VERSION ""

NS_ :

BS_:

BU_: FC

BO_ 999 GW_3E7: 8 Vector__XXX
 SG_ BCM_Status_Temp : 51|2@0+ (1,0) [0|3] ""  FC
 SG_ BCM_T_BATT : 39|8@0+ (1,-40) [-40|105] "°C"  FC

BO_ 1021 GW_3FD: 8 Vector__XXX
 SG_ BCM_DriveMode : 7|4@0+ (1,0) [0|15] ""  FC
 SG_ BCM_PowerManageLevel : 8|3@0+ (1,0) [0|7] ""  FC

BO_ 1310 GW_51E: 8 Vector__XXX
 SG_ TPMS_TireTemperature : 15|8@0+ (1,-40) [-40|214] "°C"  FC
 SG_ TPMS_TirePosition : 2|3@0+ (1,0) [0|3] ""  FC

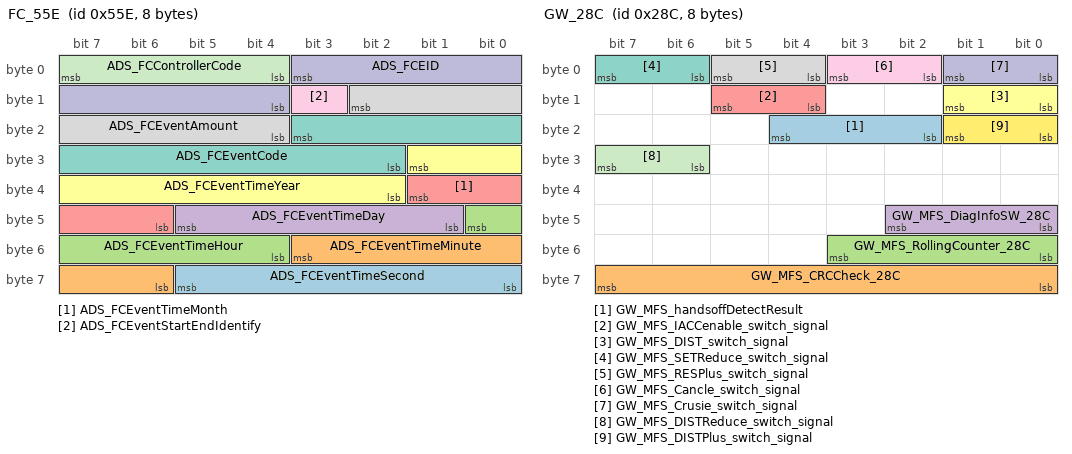
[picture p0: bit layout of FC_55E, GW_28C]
BO_ 1374 FC_55E: 8 FC
 SG_ ADS_FCEventTimeSecond : 61|6@0+ (1,0) [0|59] "秒" Vector__XXX
 SG_ ADS_FCEventTimeMinute : 51|6@0+ (1,0) [0|59] "分" Vector__XXX
 SG_ ADS_FCEventTimeHour : 40|5@0+ (1,0) [0|23] "时" Vector__XXX
 SG_ ADS_FCEventTimeDay : 45|5@0+ (1,0) [0|31] "日" Vector__XXX
 SG_ ADS_FCEventTimeMonth : 33|4@0+ (1,0) [0|15] "月" Vector__XXX
 SG_ ADS_FCEventTimeYear : 25|8@0+ (1,2013) [2013|2268] "年" Vector__XXX
 SG_ ADS_FCEventCode : 19|10@0+ (1,0) [0|1023] "" Vector__XXX
 SG_ ADS_FCEventAmount : 10|7@0+ (1,0) [0|127] "" Vector__XXX
 SG_ ADS_FCEventStartEndIdentify : 11|1@0+ (1,0) [0|1] "" Vector__XXX
 SG_ ADS_FCEID : 3|8@0+ (1,0) [0|255] "" Vector__XXX
 SG_ ADS_FCControllerCode : 7|4@0+ (1,0) [0|15] "" Vector__XXX

BO_ 652 GW_28C: 8 Vector__XXX
 SG_ GW_MFS_handsoffDetectResult : 20|3@0+ (1,0) [0|7] ""  FC
 SG_ GW_MFS_CRCCheck_28C : 63|8@0+ (1,0) [0|255] ""  FC
 SG_ GW_MFS_RollingCounter_28C : 51|4@0+ (1,0) [0|15] ""  FC
 SG_ GW_MFS_DiagInfoSW_28C : 42|3@0+ (1,0) [0|7] ""  FC
 SG_ GW_MFS_IACCenable_switch_signal : 13|2@0+ (1,0) [0|3] ""  FC
 SG_ GW_MFS_DIST_switch_signal : 9|2@0+ (1,0) [0|3] ""  FC
 SG_ GW_MFS_SETReduce_switch_signal : 7|2@0+ (1,0) [0|3] ""  FC
 SG_ GW_MFS_RESPlus_switch_signal : 5|2@0+ (1,0) [0|3] ""  FC
 SG_ GW_MFS_Cancle_switch_signal : 3|2@0+ (1,0) [0|3] ""  FC
 SG_ GW_MFS_Crusie_switch_signal : 1|2@0+ (1,0) [0|3] ""  FC
 SG_ GW_MFS_DISTReduce_switch_signal : 31|2@0+ (1,0) [0|3] ""  FC
 SG_ GW_MFS_DISTPlus_switch_signal : 17|2@0+ (1,0) [0|3] ""  FC

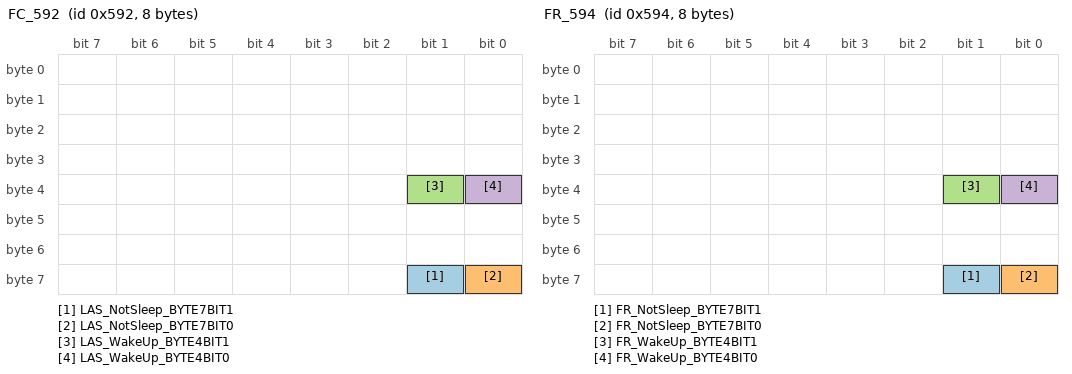
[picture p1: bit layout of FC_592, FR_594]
BO_ 1426 FC_592: 8 FC
 SG_ LAS_NotSleep_BYTE7BIT1 : 57|1@0+ (1,0) [0|1] "" Vector__XXX
 SG_ LAS_NotSleep_BYTE7BIT0 : 56|1@0+ (1,0) [0|1] "" Vector__XXX
 SG_ LAS_WakeUp_BYTE4BIT1 : 33|1@0+ (1,0) [0|1] "" Vector__XXX
 SG_ LAS_WakeUp_BYTE4BIT0 : 32|1@0+ (1,0) [0|1] "" Vector__XXX

BO_ 1428 FR_594: 8 Vector__XXX
 SG_ FR_NotSleep_BYTE7BIT1 : 57|1@0+ (1,0) [0|1] ""  FC
 SG_ FR_NotSleep_BYTE7BIT0 : 56|1@0+ (1,0) [0|1] ""  FC
 SG_ FR_WakeUp_BYTE4BIT1 : 33|1@0+ (1,0) [0|1] ""  FC
 SG_ FR_WakeUp_BYTE4BIT0 : 32|1@0+ (1,0) [0|1] ""  FC

BO_ 1106 FC_452: 8 FC

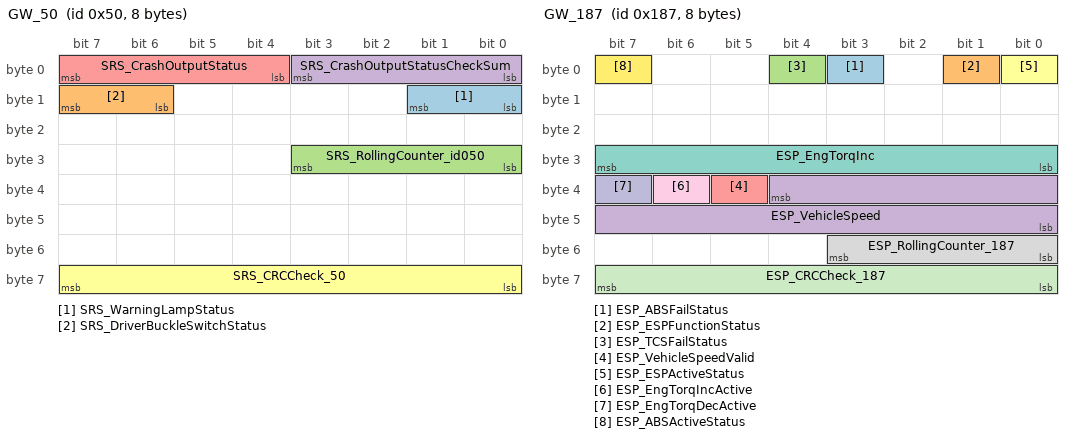
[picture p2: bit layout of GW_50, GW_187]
BO_ 80 GW_50: 8 Vector__XXX
 SG_ SRS_WarningLampStatus : 9|2@0+ (1,0) [0|3] ""  FC
 SG_ SRS_DriverBuckleSwitchStatus : 15|2@0+ (1,0) [0|3] ""  FC
 SG_ SRS_RollingCounter_id050 : 27|4@0+ (1,0) [0|15] ""  FC
 SG_ SRS_CrashOutputStatusCheckSum : 3|4@0+ (1,0) [0|15] ""  FC
 SG_ SRS_CrashOutputStatus : 7|4@0+ (1,0) [0|15] ""  FC
 SG_ SRS_CRCCheck_50 : 63|8@0+ (1,0) [0|255] ""  FC

BO_ 898 FC_382: 64 FC
 SG_ ACC_RollingCounter_382 : 491|4@0+ (1,0) [0|15] "" Vector__XXX
 SG_ ACC_CRCCheck_382 : 503|16@0+ (1,0) [0|65535] "" Vector__XXX
 SG_ ACC_CRCCheck_3E6 : 191|8@0+ (1,0) [0|255] "" Vector__XXX
 SG_ ACC_RollingCounter_3E6 : 179|4@0+ (1,0) [0|15] "" Vector__XXX
 SG_ ACC_LaneEquationStatus : 181|2@0+ (1,0) [0|3] "" Vector__XXX
 SG_ ACC_LaneEquationC3 : 161|12@0+ (4.768E-007,-0.0009760857) [-0.0009760857|0.0009760857] "" Vector__XXX
 SG_ ACC_LaneEquationC2 : 157|12@0+ (1.52588E-005,-0.0312347412) [-0.0312347412|0.0312347412] "" Vector__XXX
 SG_ ACC_LaneEquationC1 : 137|12@0+ (0.0004882813,-1) [-1|0.9990234375] "rad" Vector__XXX
 SG_ ACC_LaneQuality : 134|6@0+ (0.015625,0) [0|0.984375] "" Vector__XXX
 SG_ ACC_CRCCheck_35C : 127|8@0+ (1,0) [0|255] "" Vector__XXX
 SG_ ACC_RollingCounter_35C : 115|4@0+ (1,0) [0|15] "" Vector__XXX
 SG_ ACC_FRTarget2Type : 99|4@0+ (1,0) [0|15] "" Vector__XXX
 SG_ ACC_FRTarget2LatRange : 94|10@0+ (0.1,-50) [-50|50] "m" Vector__XXX
 SG_ ACC_FRTarget2LngRange : 72|9@0+ (0.5,-70) [-70|180] "m" Vector__XXX
 SG_ ACC_FRTarget2Detection : 76|3@0+ (1,0) [0|7] "" Vector__XXX
 SG_ ACC_FRTarget2Direction : 111|3@0+ (1,0) [0|7] "" Vector__XXX
 SG_ ACC_CRCCheck_35D : 63|8@0+ (1,0) [0|255] "" Vector__XXX
 SG_ ACC_RollingCounter_35D : 51|4@0+ (1,0) [0|15] "" Vector__XXX
 SG_ ACC_FRTarget1Direction : 47|3@0+ (1,0) [0|7] "" Vector__XXX
 SG_ ACC_FRTarget1Type : 35|4@0+ (1,0) [0|15] "" Vector__XXX
 SG_ ACC_FRTarget1LatRange : 30|10@0+ (0.1,-50) [-50|50] "m" Vector__XXX
 SG_ ACC_FRTarget1LngRange : 8|9@0+ (0.5,-70) [-70|180] "m" Vector__XXX
 SG_ ACC_FRTarget1Detection : 12|3@0+ (1,0) [0|7] "" Vector__XXX
 SG_ ACC_FLTarget2LatRange : 7|10@0+ (0.1,-50) [-50|50] "m" Vector__XXX

BO_ 1328 GW_530: 8 Vector__XXX
 SG_ IP_TotalOdometer : 23|24@0+ (0.1,0) [0|999999] "Km"  FC

BO_ 391 GW_187: 8 Vector__XXX
 SG_ ESP_ABSFailStatus : 3|1@0+ (1,0) [0|1] ""  FC
 SG_ ESP_ESPFunctionStatus : 1|1@0+ (1,0) [0|1] ""  FC
 SG_ ESP_TCSFailStatus : 4|1@0+ (1,0) [0|1] ""  FC
 SG_ ESP_VehicleSpeed : 36|13@0+ (0.05625,0) [0|360] "km/h"  FC
 SG_ ESP_VehicleSpeedValid : 37|1@0+ (1,0) [0|1] ""  FC
 SG_ ESP_ESPActiveStatus : 0|1@0+ (1,0) [0|1] ""  FC
 SG_ ESP_EngTorqInc : 31|8@0+ (0.392,0) [0|99.568] "%"  FC
 SG_ ESP_RollingCounter_187 : 51|4@0+ (1,0) [0|15] ""  FC
 SG_ ESP_EngTorqIncActive : 38|1@0+ (1,0) [0|1] ""  FC
 SG_ ESP_EngTorqDecActive : 39|1@0+ (1,0) [0|1] ""  FC
 SG_ ESP_CRCCheck_187 : 63|8@0+ (1,0) [0|255] ""  FC
 SG_ ESP_ABSActiveStatus : 7|1@0+ (1,0) [0|1] ""  FC

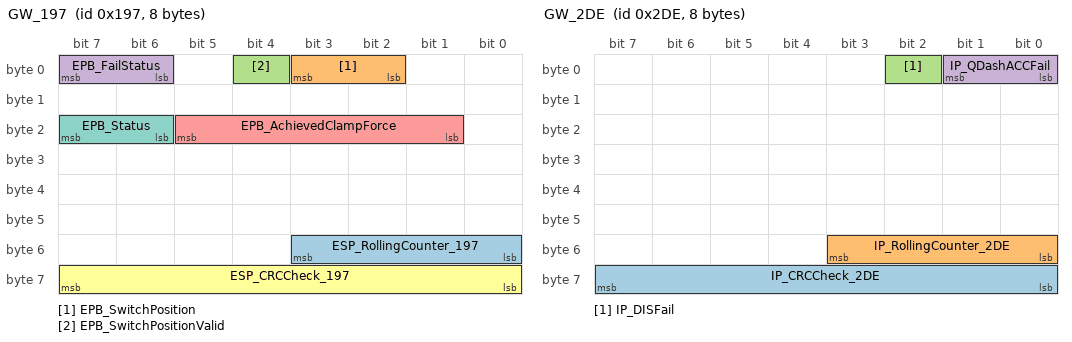
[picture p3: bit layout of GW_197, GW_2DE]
BO_ 407 GW_197: 8 Vector__XXX
 SG_ ESP_RollingCounter_197 : 51|4@0+ (1,0) [0|15] ""  FC
 SG_ EPB_SwitchPosition : 3|2@0+ (1,0) [0|3] ""  FC
 SG_ EPB_SwitchPositionValid : 4|1@0+ (1,0) [0|1] ""  FC
 SG_ EPB_FailStatus : 7|2@0+ (1,0) [0|3] ""  FC
 SG_ EPB_AchievedClampForce : 21|5@0+ (1,0) [0|31] "KN"  FC
 SG_ ESP_CRCCheck_197 : 63|8@0+ (1,0) [0|255] ""  FC
 SG_ EPB_Status : 23|2@0+ (1,0) [0|3] ""  FC

BO_ 523 GW_20B: 64 Vector__XXX
 SG_ ESP_RollingCounter_20B : 491|4@0+ (1,0) [0|15] ""  FC
 SG_ ESP_CRCCheck_20B : 503|16@0+ (1,0) [0|65535] ""  FC
 SG_ ESP_Vehicle_Speed_Reference : 103|13@0+ (0.05625,0) [0|360] "km/h"  FC
 SG_ Wheel_Speed_RR_Valid_Data : 71|1@0+ (1,0) [0|1] ""  FC
 SG_ Wheel_Speed_RR_Pulse : 231|8@0+ (1,0) [0|254] ""  FC
 SG_ Wheel_Speed_RR_Direction : 70|2@0+ (1,0) [0|3] ""  FC
 SG_ Wheel_Speed_RR_Data : 68|13@0+ (0.05625,0) [0|360] "km/h"  FC
 SG_ Wheel_Speed_RL_Valid_Data : 87|1@0+ (1,0) [0|1] ""  FC
 SG_ Wheel_Speed_RL_Pulse : 239|8@0+ (1,0) [0|254] ""  FC
 SG_ Wheel_Speed_RL_Direction : 86|2@0+ (1,0) [0|3] ""  FC
 SG_ Wheel_Speed_RL_Data : 84|13@0+ (0.05625,0) [0|360] "km/h"  FC
 SG_ Wheel_Speed_FR_Valid_Data : 7|1@0+ (1,0) [0|1] ""  FC
 SG_ Wheel_Speed_FR_Pulse : 223|8@0+ (1,0) [0|254] ""  FC
 SG_ Wheel_Speed_FR_Direction : 6|2@0+ (1,0) [0|3] ""  FC
 SG_ Wheel_Speed_FR_Data : 4|13@0+ (0.05625,0) [0|360] "km/h"  FC
 SG_ Wheel_Speed_FL_Valid_Data : 23|1@0+ (1,0) [0|1] ""  FC
 SG_ Wheel_Speed_FL_Pulse : 215|8@0+ (1,0) [0|254] ""  FC
 SG_ Wheel_Speed_FL_Direction : 22|2@0+ (1,0) [0|3] ""  FC
 SG_ Wheel_Speed_FL_Data : 20|13@0+ (0.05625,0) [0|360] "km/h"  FC
 SG_ ESP_VehicleStandstill : 267|1@0+ (1,0) [0|1] ""  FC
 SG_ ESP_VDCActive : 266|1@0+ (1,0) [0|1] ""  FC
 SG_ ESP_TCSActive : 265|1@0+ (1,0) [0|1] ""  FC
 SG_ ESP_RollingCounter_277 : 307|4@0+ (1,0) [0|15] ""  FC
 SG_ ESP_RollingCounter_258 : 243|4@0+ (1,0) [0|15] ""  FC
 SG_ ESP_RollingCounter_208 : 115|4@0+ (1,0) [0|15] ""  FC
 SG_ ESP_RollingCounter_206 : 51|4@0+ (1,0) [0|15] ""  FC
 SG_ ESP_QDCACC : 279|2@0+ (1,0) [0|3] ""  FC
 SG_ ESP_PrefillAvailable : 259|1@0+ (1,0) [0|1] ""  FC
 SG_ ESP_PrefillActive : 260|1@0+ (1,0) [0|1] ""  FC
 SG_ ESP_OnlyABSActive : 264|1@0+ (1,0) [0|1] ""  FC
 SG_ ESP_MasCylBrakePressureValid : 199|1@0+ (1,0) [0|1] ""  FC
 SG_ ESP_MasCylBrakePressure : 195|12@0+ (0.1,0) [0|250] "Bar"  FC
 SG_ ESP_HDC_STATUS : 274|2@0+ (1,0) [0|3] ""  FC
 SG_ ESP_CRCCheck_277 : 319|8@0+ (1,0) [0|255] ""  FC
 SG_ ESP_CRCCheck_258 : 255|8@0+ (1,0) [0|255] ""  FC
 SG_ ESP_CRCCheck_208 : 127|8@0+ (1,0) [0|255] ""  FC
 SG_ ESP_CRCCheck_206 : 63|8@0+ (1,0) [0|255] ""  FC
 SG_ ESP_CDD_Available : 268|1@0+ (1,0) [0|1] ""  FC
 SG_ ESP_CDD_Active : 269|1@0+ (1,0) [0|1] ""  FC
 SG_ ESP_BrakeOverHeatBrakeDiscTemp : 270|1@0+ (1,0) [0|1] ""  FC
 SG_ ESP_BrakeForce : 263|1@0+ (1,0) [0|1] ""  FC
 SG_ ESP_AWBavailable : 271|1@0+ (1,0) [0|1] ""  FC
 SG_ ESP_AWBactive : 256|1@0+ (1,0) [0|1] ""  FC
 SG_ ESP_AEBdecActive : 257|1@0+ (1,0) [0|1] ""  FC
 SG_ ESP_AEBAvailable : 258|1@0+ (1,0) [0|1] ""  FC
 SG_ ESP_ABAavailable : 261|1@0+ (1,0) [0|1] ""  FC
 SG_ ESP_ABAactive : 262|1@0+ (1,0) [0|1] ""  FC

BO_ 734 GW_2DE: 8 Vector__XXX
 SG_ IP_CRCCheck_2DE : 63|8@0+ (1,0) [0|255] ""  FC
 SG_ IP_RollingCounter_2DE : 51|4@0+ (1,0) [0|15] ""  FC
 SG_ IP_DISFail : 2|1@0+ (1,0) [0|1] ""  FC
 SG_ IP_QDashACCFail : 1|2@0+ (1,0) [0|3] ""  FC

BO_ 947 IBCMR_3B3: 8 Vector__XXX
 SG_ BCM_BrakeLampError : 31|1@0+ (1,0) [0|1] ""  FC
 SG_ BCM_RearFoglampStatus : 11|2@0+ (1,0) [0|3] ""  FC

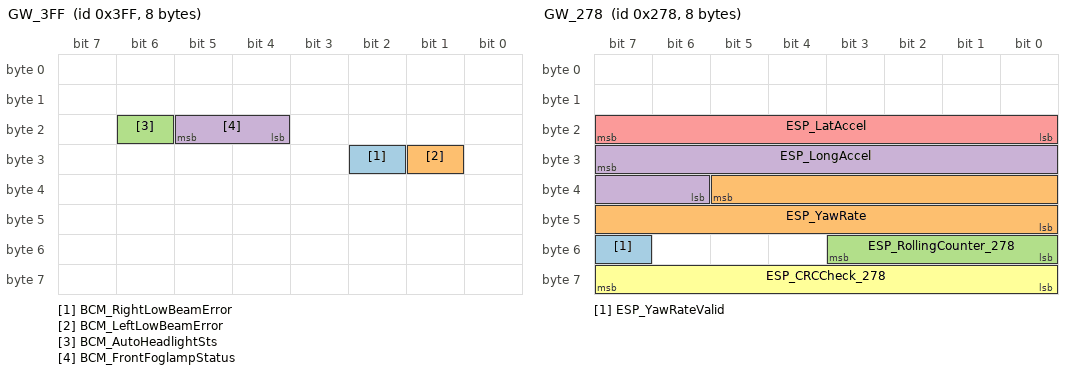
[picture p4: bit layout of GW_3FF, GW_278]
BO_ 1023 GW_3FF: 8 Vector__XXX
 SG_ BCM_RightLowBeamError : 26|1@0+ (1,0) [0|1] ""  FC
 SG_ BCM_LeftLowBeamError : 25|1@0+ (1,0) [0|1] ""  FC
 SG_ BCM_AutoHeadlightSts : 22|1@0+ (1,0) [0|1] ""  FC
 SG_ BCM_FrontFoglampStatus : 21|2@0+ (1,0) [0|3] ""  FC

BO_ 1882 FC_75A: 64 FC

BO_ 1899 FC_76B: 8 FC

BO_ 632 GW_278: 8 Vector__XXX
 SG_ ESP_YawRateValid : 55|1@0+ (1,0) [0|1] ""  FC
 SG_ ESP_YawRate : 37|14@0+ (0.01,-81.91) [-81.91|81.91] "degree/s"  FC
 SG_ ESP_RollingCounter_278 : 51|4@0+ (1,0) [0|15] ""  FC
 SG_ ESP_LongAccel : 31|10@0+ (0.03125,-16) [-16|15.90625] "m/s2"  FC
 SG_ ESP_LatAccel : 23|8@0+ (0.1,-12.7) [-12.7|12.7] "m/s2"  FC
 SG_ ESP_CRCCheck_278 : 63|8@0+ (1,0) [0|255] ""  FC

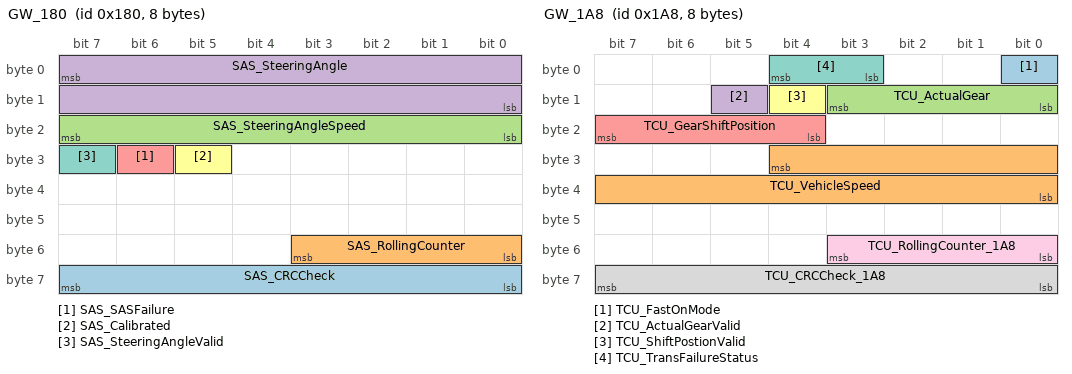
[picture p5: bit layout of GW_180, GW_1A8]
BO_ 384 GW_180: 8 Vector__XXX
 SG_ SAS_CRCCheck : 63|8@0+ (1,0) [0|255] ""  FC
 SG_ SAS_RollingCounter : 51|4@0+ (1,0) [0|15] ""  FC
 SG_ SAS_SteeringAngleSpeed : 23|8@0+ (4,0) [0|1016] "deg/s"  FC
 SG_ SAS_SteeringAngle : 7|16@0- (0.1,0) [-780|780] "degree"  FC
 SG_ SAS_SASFailure : 30|1@0+ (1,0) [0|1] ""  FC
 SG_ SAS_Calibrated : 29|1@0+ (1,0) [0|1] ""  FC
 SG_ SAS_SteeringAngleValid : 31|1@0+ (1,0) [0|1] ""  FC

BO_ 424 GW_1A8: 8 Vector__XXX
 SG_ TCU_FastOnMode : 0|1@0+ (1,0) [0|1] ""  FC
 SG_ TCU_VehicleSpeed : 28|13@0+ (0.05625,0) [0|360] "km/h"  FC
 SG_ TCU_ActualGear : 11|4@0+ (1,0) [0|15] ""  FC
 SG_ TCU_ActualGearValid : 13|1@0+ (1,0) [0|1] ""  FC
 SG_ TCU_GearShiftPosition : 23|4@0+ (1,0) [0|15] ""  FC
 SG_ TCU_ShiftPostionValid : 12|1@0+ (1,0) [0|1] ""  FC
 SG_ TCU_TransFailureStatus : 4|2@0+ (1,0) [0|3] ""  FC
 SG_ TCU_CRCCheck_1A8 : 63|8@0+ (1,0) [0|255] ""  FC
 SG_ TCU_RollingCounter_1A8 : 51|4@0+ (1,0) [0|15] ""  FC

BO_ 784 GW_310: 8 Vector__XXX
 SG_ AMP_AllAlarmFailureStatus : 38|1@0+ (1,0) [0|1] ""  FC
 SG_ AMP_IPEnableAlarmFailureStatus : 39|1@0+ (1,0) [0|1] ""  FC

BO_ 790 FC_316: 64 FC
 SG_ LAS_Line_04_MeasureType_FT : 495|3@0+ (1,0) [0|7] "" Vector__XXX
 SG_ LAS_Line_03_MeasureType_FT : 482|3@0+ (1,0) [0|7] "" Vector__XXX
 SG_ LAS_Line_02_MeasureType_FT : 354|3@0+ (1,0) [0|7] "" Vector__XXX
 SG_ LAS_Line_01_MeasureType_FT : 338|3@0+ (1,0) [0|7] "" Vector__XXX
 SG_ LAS_Line_03_curvature_alte_FT : 367|12@0+ (1.272E-007,-0.00026042) [-0.00026042|0.000260417] "1/m2" Vector__XXX
 SG_ LAS_Line_03_curve_FT : 274|14@0+ (1.9074E-006,-0.015625) [-0.015625|0.0156212077] "1/m" Vector__XXX
 SG_ LAS_Line_02_curvature_alte_FT : 179|12@0+ (1.272E-007,-0.00026042) [-0.00026042|0.000260417] "1/m2" Vector__XXX
 SG_ LAS_Line_02_curve_FT : 157|14@0+ (1.9074E-006,-0.015625) [-0.015625|0.0156212077] "1/m" Vector__XXX
 SG_ LAS_Line_01_curvature_alte_FT : 175|12@0+ (1.272E-007,-0.00026042) [-0.00026042|0.000260417] "1/m2" Vector__XXX
 SG_ LAS_Line_01_curve_FT : 82|14@0+ (1.9074E-006,-0.015625) [-0.015625|0.0156212077] "1/m" Vector__XXX
 SG_ LAS_RollingCounter_316 : 491|4@0+ (1,0) [0|15] "" Vector__XXX
 SG_ LAS_CRCCheck_316 : 503|16@0+ (1,0) [0|65535] "" Vector__XXX
 SG_ LAS_Line_03_MeasureType : 465|2@0+ (1,0) [0|2] "" Vector__XXX
 SG_ LAS_Line_03_curvature_alteration : 371|12@0+ (3.8147E-006,-0.0078125) [-0.0078125|0.0078086965] "1/m2" Vector__XXX
 SG_ LAS_Line_03__curve : 479|13@0+ (3.8147E-006,-0.015625) [-0.015625|0.0156212077] "1/m" Vector__XXX
 SG_ LAS_Line_03_HeadingAngle : 351|13@0+ (0.000488281,-1.6) [-1.6|1.6] "rad" Vector__XXX
 SG_ LAS_Line_03_dy : 462|12@0+ (0.015625,-32) [-32|31.984375] "m" Vector__XXX
 SG_ LAS_Line_03_dx_End_std : 455|9@0+ (0.0078125,0) [0|3.992187] "m" Vector__XXX
 SG_ LAS_Line_03__dx_End : 433|10@0+ (0.25,0) [0|255.75] "m" Vector__XXX
 SG_ LAS_Line_03_dx_Start_std : 426|9@0+ (0.0078125,0) [0|3.9921875] "m" Vector__XXX
 SG_ LAS_Line_03_dx_Start : 423|13@0+ (0.025,0) [0|204.775] "m" Vector__XXX
 SG_ LAS_Line_03_Width : 415|8@0+ (0.01,0) [0|2.55] "m" Vector__XXX
 SG_ LAS_Line_03_color : 402|3@0+ (1,0) [0|7] "" Vector__XXX
 SG_ LAS_Line_03_Id : 399|8@0+ (1,0) [1|255] "" Vector__XXX
 SG_ LAS_Line_03_TypeConfidence : 391|6@0+ (2,0) [0|100] "%" Vector__XXX
 SG_ LAS_Line_03_Type : 407|5@0+ (1,0) [0|31] "" Vector__XXX
 SG_ LAS_Line_02__exist_prob : 325|6@0+ (2,0) [0|100] "%" Vector__XXX
 SG_ LAS_Line_02_MeasureType : 310|2@0+ (1,0) [0|2] "" Vector__XXX
 SG_ LAS_Line_02_curvature_alteration : 307|12@0+ (3.8147E-006,-0.0078125) [-0.0078125|0.0078086965] "1/m2" Vector__XXX
 SG_ LAS_Line_02__curve : 292|13@0+ (3.8147E-006,-0.015625) [-0.015625|0.0156212077] "1/m" Vector__XXX
 SG_ LAS_Line_02_HeadingAngle : 335|13@0+ (0.000488281,-1.6) [-1.6|1.6] "rad" Vector__XXX
 SG_ LAS_Line_02_dy : 270|12@0+ (0.015625,-32) [-32|31.984375] "m" Vector__XXX
 SG_ LAS_Line_02_dx_End_std : 263|9@0+ (0.0078125,0) [0|3.992187] "m" Vector__XXX
 SG_ LAS_Line_02__dx_End : 241|10@0+ (0.25,0) [0|255.75] "m" Vector__XXX
 SG_ LAS_Line_02_dx_Start_std : 234|9@0+ (0.0078125,0) [0|3.9921875] "m" Vector__XXX
 SG_ LAS_Line_02_dx_Start : 231|13@0+ (0.025,0) [0|204.775] "m" Vector__XXX
 SG_ LAS_Line_02_Width : 223|8@0+ (0.01,0) [0|2.55] "m" Vector__XXX
 SG_ LAS_Line_02_color : 210|3@0+ (1,0) [0|7] "" Vector__XXX
 SG_ LAS_Line_02_Id : 207|8@0+ (1,0) [1|255] "" Vector__XXX
 SG_ LAS_Line_02_TypeConfidence : 199|6@0+ (2,0) [0|100] "%" Vector__XXX
 SG_ LAS_Line_02_Type : 215|5@0+ (1,0) [0|31] "" Vector__XXX
 SG_ LAS_Line_01__exist_prob : 133|6@0+ (2,0) [0|100] "%" Vector__XXX
 SG_ LAS_Line_01_MeasureType : 118|2@0+ (1,0) [0|2] "" Vector__XXX
 SG_ LAS_Line_01_curvature_alteration : 115|12@0+ (3.8147E-006,-0.0078125) [-0.0078125|0.0078086965] "1/m2" Vector__XXX
 SG_ LAS_Line_01__curve : 100|13@0+ (3.8147E-006,-0.015625) [-0.015625|0.0156212077] "1/m" Vector__XXX
 SG_ LAS_Line_01_HeadingAngle : 143|13@0+ (0.000488281,-1.6) [-1.6|1.6] "rad" Vector__XXX
 SG_ LAS_Line_01_dy : 78|12@0+ (0.015625,-32) [-32|31.984375] "m" Vector__XXX
 SG_ LAS_Line_01_dx_End_std : 71|9@0+ (0.0078125,0) [0|3.992187] "m" Vector__XXX
 SG_ LAS_Line_01__dx_End : 49|10@0+ (0.25,0) [0|255.75] "m" Vector__XXX
 SG_ LAS_Line_01_dx_Start_std : 42|9@0+ (0.0078125,0) [0|3.9921875] "m" Vector__XXX
 SG_ LAS_Line_01_dx_Start : 39|13@0+ (0.025,0) [0|204.775] "m" Vector__XXX
 SG_ LAS_Line_01_Width : 31|8@0+ (0.01,0) [0|2.55] "m" Vector__XXX
 SG_ LAS_Line_01_color : 18|3@0+ (1,0) [0|7] "" Vector__XXX
 SG_ LAS_Line_01_Id : 15|8@0+ (1,0) [1|255] "" Vector__XXX
 SG_ LAS_Line_01_TypeConfidence : 7|6@0+ (2,0) [0|100] "%" Vector__XXX
 SG_ LAS_Line_01_Type : 23|5@0+ (1,0) [0|31] "" Vector__XXX

BO_ 800 GW_320: 8 Vector__XXX
 SG_ GW_ResetReq : 31|7@0+ (1,0) [0|127] ""  FC

BO_ 822 FC_336: 64 FC
 SG_ LAS_Line_06_MeasureType_FT : 481|3@0+ (1,0) [0|7] "" Vector__XXX
 SG_ LAS_Line_06_curve_FT : 346|14@0+ (1.9074E-006,-0.015625) [-0.015625|0.0156212077] "1/m" Vector__XXX
 SG_ LAS_Line_05_MeasureType_FT : 154|3@0+ (1,0) [0|7] "" Vector__XXX
 SG_ LAS_Line_05_curve_FT : 170|14@0+ (1.9074E-006,-0.015625) [-0.015625|0.0156212077] "1/m" Vector__XXX
 SG_ LAS_Line_04_curvature_alte_FT : 272|12@0+ (1.272E-007,-0.00026042) [-0.00026042|0.000260417] "1/m2" Vector__XXX
 SG_ LAS_Line_04_curve_FT : 82|14@0+ (1.9074E-006,-0.015625) [-0.015625|0.0156212077] "1/m" Vector__XXX
 SG_ LAS_RollingCounter_336 : 491|4@0+ (1,0) [0|15] "" Vector__XXX
 SG_ LAS_CRCCheck_336 : 503|16@0+ (1,0) [0|65535] "" Vector__XXX
 SG_ LAS_Line_06__exist_prob : 333|6@0+ (2,0) [0|100] "%" Vector__XXX
 SG_ LAS_Line_06_MeasureType : 465|2@0+ (1,0) [0|2] "" Vector__XXX
 SG_ LAS_Line_06_curvature_alteration : 371|12@0+ (3.8147E-006,-0.0078125) [-0.0078125|0.0078086965] "1/m2" Vector__XXX
 SG_ LAS_Line_06__curve : 479|13@0+ (3.8147E-006,-0.015625) [-0.015625|0.0156212077] "1/m" Vector__XXX
 SG_ LAS_Line_06_HeadingAngle : 343|13@0+ (0.000488281,-1.6) [-1.6|1.6] "rad" Vector__XXX
 SG_ LAS_Line_06_dy : 462|12@0+ (0.015625,-32) [-32|31.984375] "m" Vector__XXX
 SG_ LAS_Line_06_dx_End_std : 455|9@0+ (0.0078125,0) [0|3.992187] "m" Vector__XXX
 SG_ LAS_Line_06__dx_End : 433|10@0+ (0.25,0) [0|255.75] "m" Vector__XXX
 SG_ LAS_Line_06_dx_Start_std : 426|9@0+ (0.0078125,0) [0|3.9921875] "m" Vector__XXX
 SG_ LAS_Line_06_dx_Start : 423|13@0+ (0.025,0) [0|204.775] "m" Vector__XXX
 SG_ LAS_Line_06_Width : 415|8@0+ (0.01,0) [0|2.55] "m" Vector__XXX
 SG_ LAS_Line_06_color : 402|3@0+ (1,0) [0|7] "" Vector__XXX
 SG_ LAS_Line_06_Id : 399|8@0+ (1,0) [1|255] "" Vector__XXX
 SG_ LAS_Line_06_TypeConfidence : 391|6@0+ (2,0) [0|100] "%" Vector__XXX
 SG_ LAS_Line_06_Type : 407|5@0+ (1,0) [0|31] "" Vector__XXX
 SG_ LAS_Line_05__exist_prob : 325|6@0+ (2,0) [0|100] "%" Vector__XXX
 SG_ LAS_Line_05_MeasureType : 310|2@0+ (1,0) [0|2] "" Vector__XXX
 SG_ LAS_Line_05_curvature_alteration : 307|12@0+ (3.8147E-006,-0.0078125) [-0.0078125|0.0078086965] "1/m2" Vector__XXX
 SG_ LAS_Line_05__curve : 292|13@0+ (3.8147E-006,-0.015625) [-0.015625|0.0156212077] "1/m" Vector__XXX
 SG_ LAS_Line_05_HeadingAngle : 167|13@0+ (0.000488281,-1.6) [-1.6|1.6] "rad" Vector__XXX
 SG_ LAS_Line_05_dy : 270|12@0+ (0.015625,-32) [-32|31.984375] "m" Vector__XXX
 SG_ LAS_Line_05_dx_End_std : 263|9@0+ (0.0078125,0) [0|3.992187] "m" Vector__XXX
 SG_ LAS_Line_05__dx_End : 241|10@0+ (0.25,0) [0|255.75] "m" Vector__XXX
 SG_ LAS_Line_05_dx_Start_std : 234|9@0+ (0.0078125,0) [0|3.9921875] "m" Vector__XXX
 SG_ LAS_Line_05_dx_Start : 231|13@0+ (0.025,0) [0|204.775] "m" Vector__XXX
 SG_ LAS_Line_05_Width : 223|8@0+ (0.01,0) [0|2.55] "m" Vector__XXX
 SG_ LAS_Line_05_color : 210|3@0+ (1,0) [0|7] "" Vector__XXX
 SG_ LAS_Line_05_Id : 207|8@0+ (1,0) [1|255] "" Vector__XXX
 SG_ LAS_Line_05_TypeConfidence : 199|6@0+ (2,0) [0|100] "%" Vector__XXX
 SG_ LAS_Line_05_Type : 215|5@0+ (1,0) [0|31] "" Vector__XXX
 SG_ LAS_Line_04__exist_prob : 133|6@0+ (2,0) [0|100] "%" Vector__XXX
 SG_ LAS_Line_04_MeasureType : 118|2@0+ (1,0) [0|2] "" Vector__XXX
 SG_ LAS_Line_04_curvature_alteration : 115|12@0+ (3.8147E-006,-0.0078125) [-0.0078125|0.0078086965] "1/m2" Vector__XXX
 SG_ LAS_Line_04__curve : 100|13@0+ (3.8147E-006,-0.015625) [-0.015625|0.0156212077] "1/m" Vector__XXX
 SG_ LAS_Line_04_HeadingAngle : 151|13@0+ (0.000488281,-1.6) [-1.6|1.6] "rad" Vector__XXX
 SG_ LAS_Line_04_dy : 78|12@0+ (0.015625,-32) [-32|31.984375] "m" Vector__XXX
 SG_ LAS_Line_04_dx_End_std : 71|9@0+ (0.0078125,0) [0|3.992187] "m" Vector__XXX
 SG_ LAS_Line_04__dx_End : 49|10@0+ (0.25,0) [0|255.75] "m" Vector__XXX
 SG_ LAS_Line_04_dx_Start_std : 42|9@0+ (0.0078125,0) [0|3.9921875] "m" Vector__XXX
 SG_ LAS_Line_04_dx_Start : 39|13@0+ (0.025,0) [0|204.775] "m" Vector__XXX
 SG_ LAS_Line_04_Width : 31|8@0+ (0.01,0) [0|2.55] "m" Vector__XXX
 SG_ LAS_Line_04_color : 18|3@0+ (1,0) [0|7] "" Vector__XXX
 SG_ LAS_Line_04_Id : 15|8@0+ (1,0) [1|255] "" Vector__XXX
 SG_ LAS_Line_04_TypeConfidence : 7|6@0+ (2,0) [0|100] "%" Vector__XXX
 SG_ LAS_Line_04_Type : 23|5@0+ (1,0) [0|31] "" Vector__XXX
 SG_ LAS_Line_03__exist_prob : 141|6@0+ (2,0) [0|100] "%" Vector__XXX

BO_ 683 FC_2AB: 64 FC
 SG_ FC_RollingCounter_28D : 491|4@0+ (1,0) [0|15] "" Vector__XXX
 SG_ FC_CRCCheck_28D : 503|16@0+ (1,0) [0|65535] "" Vector__XXX
 SG_ FC_AEBOBJ_Track_Age : 479|8@0+ (1,0) [0|255] "" Vector__XXX
 SG_ FC_AEBOBJ_Track_ID : 460|8@0+ (1,0) [0|255] "" Vector__XXX
 SG_ FC_AEBOBJ_FusionedFC_Track_ID : 487|8@0+ (1,0) [0|255] "" Vector__XXX
 SG_ FC_AEBOBJ_fusion_Sts : 463|2@0+ (1,0) [0|3] "" Vector__XXX
 SG_ FC_AEBOBJ_ObstacleProb : 453|6@0+ (2,0) [0|100] "%" Vector__XXX
 SG_ FC_AEBOBJ_ExistProb : 445|6@0+ (2,0) [0|100] "%" Vector__XXX
 SG_ FC_AEBOBJ_Brakelight_Info : 447|1@0+ (1,0) [0|1] "" Vector__XXX
 SG_ FC_AEBOBJ_Taillight_Info : 434|3@0+ (1,0) [0|7] "" Vector__XXX
 SG_ FC_AEBOBJ_Dis_to_R_LaneMark : 428|9@0+ (0.01,0) [0|5] "m" Vector__XXX
 SG_ FC_AEBOBJ_Dis_to_L_LaneMark : 422|9@0+ (0.01,0) [0|5] "m" Vector__XXX
 SG_ FC_AEBOBJ_Ax : 401|10@0+ (0.03125,-16) [-16|15.96875] "m/s2" Vector__XXX
 SG_ FC_AEBOBJ_Ay : 394|9@0+ (0.0625,-16) [-16|15.9375] "m/s2" Vector__XXX
 SG_ FC_AEBOBJ_Vx_std : 391|12@0+ (0.0625,-128) [-128|127.9375] "m/s" Vector__XXX
 SG_ FC_AEBOBJ_Vx : 372|12@0+ (0.0625,-128) [-128|127.9375] "m/s" Vector__XXX
 SG_ FC_AEBOBJ_Vy_std : 367|10@0+ (0.125,-64) [-64|63.875] "m/s" Vector__XXX
 SG_ FC_AEBOBJ_Vy : 345|10@0+ (0.125,-64) [-64|63.875] "m/s" Vector__XXX
 SG_ FC_AEBOBJ_Dx_Vnce : 329|14@0+ (0.05,0) [0|50] "" Vector__XXX
 SG_ FC_AEBOBJ_Dx : 327|13@0+ (0.0625,-256) [-256|255.9375] "m" Vector__XXX
 SG_ FC_AEBOBJ_Dy_Vnce : 305|10@0+ (0.02,0) [0|20] "m2" Vector__XXX
 SG_ FC_AEBOBJ_Dy : 301|11@0+ (0.125,-128) [-128|127.875] "m" Vector__XXX
 SG_ FC_AEBOBJ_HeadingAngle : 294|9@0+ (0.01,-1.57) [-1.57|1.57] "rad" Vector__XXX
 SG_ FC_AEBOBJ_Length : 287|9@0+ (0.05,0) [0|25.5] "m" Vector__XXX
 SG_ FC_AEBOBJ_Height : 264|9@0+ (0.01,0) [0|5.11] "m" Vector__XXX
 SG_ FC_AEBOBJ_Width : 259|11@0+ (0.01,0) [0|12] "m" Vector__XXX
 SG_ FC_AEBOBJ_Class : 263|3@0+ (1,0) [0|7] "" Vector__XXX

BO_ 711 GW_2C7: 64 Vector__XXX
 SG_ FRC_TiOut : 101|1@0+ (1,0) [0|1] "-"  FC
 SG_ FRC_TiLeap : 102|1@0+ (1,0) [0|1] "-"  FC
 SG_ FRC_TiBas : 103|1@0+ (1,0) [0|1] "-"  FC
 SG_ FRC_TiStamp : 71|32@0+ (0.0001,0) [0|429496.7295] "s"  FC
 SG_ FRC_FCTBStatus : 47|2@0+ (1,0) [0|3] ""  FC
 SG_ FRC_FCTAEnable : 52|1@0+ (1,0) [0|1] ""  FC
 SG_ FRC_PrefillActive : 26|1@0+ (1,0) [0|1] ""  FC
 SG_ FRC_RollingCounter_2C7 : 491|4@0+ (1,0) [0|15] ""  FC
 SG_ FRC_CRCCheck_2C7 : 503|16@0+ (1,0) [0|65535] ""  FC
 SG_ FRC_ObjDelay : 39|8@0+ (1,0) [0|255] "ms"  FC
 SG_ FRC_SystemStatus : 29|3@0+ (1,0) [0|7] ""  FC
 SG_ FRC_Right_FCTARStatus : 31|2@0+ (1,0) [0|3] ""  FC
 SG_ FRC_Right_FCTARAlert : 17|2@0+ (1,0) [0|3] ""  FC
 SG_ FRC_Left_FCTALAlert : 21|2@0+ (1,0) [0|3] ""  FC
 SG_ FRC_FCTBActive : 22|1@0+ (1,0) [0|1] ""  FC
 SG_ FRC_FCTBTargetDeceleration : 7|16@0+ (0.0005,-16) [-16|16] "m/s2"  FC
 SG_ FRC_FCTBEnable : 23|1@0+ (1,0) [0|1] ""  FC

BO_ 747 FC_2EB: 64 FC
 SG_ FC_RollingCounter_28F : 491|4@0+ (1,0) [0|15] "" Vector__XXX
 SG_ FC_CRCCheck_28F : 503|16@0+ (1,0) [0|65535] "" Vector__XXX
 SG_ FC_FrFrOBJ_Track_Age : 479|8@0+ (1,0) [0|255] "" Vector__XXX
 SG_ FC_FrFrOBJ_Track_ID : 460|8@0+ (1,0) [0|255] "" Vector__XXX
 SG_ FC_FrFrOBJ_FusionedFC_Track_ID : 487|8@0+ (1,0) [0|255] "" Vector__XXX
 SG_ FC_FrFrOBJ_fusion_Sts : 463|2@0+ (1,0) [0|3] "" Vector__XXX
 SG_ FC_FrFrOBJ_ObstacleProb : 453|6@0+ (2,0) [0|100] "%" Vector__XXX
 SG_ FC_FrFrOBJ_ExistProb : 445|6@0+ (2,0) [0|100] "%" Vector__XXX
 SG_ FC_FrFrOBJ_Brakelight_Info : 447|1@0+ (1,0) [0|1] "" Vector__XXX
 SG_ FC_FrFrOBJ_Taillight_Info : 434|3@0+ (1,0) [0|7] "" Vector__XXX
 SG_ FC_FrFrOBJ_Dis_to_R_LaneMark : 428|9@0+ (0.01,0) [0|5] "m" Vector__XXX
 SG_ FC_FrFrOBJ_Dis_to_L_LaneMark : 422|9@0+ (0.01,0) [0|5] "m" Vector__XXX
 SG_ FC_FrFrOBJ_Ax : 401|10@0+ (0.03125,-16) [-16|15.96875] "m/s2" Vector__XXX
 SG_ FC_FrFrOBJ_Ay : 394|9@0+ (0.0625,-16) [-16|15.9375] "m/s2" Vector__XXX
 SG_ FC_FrFrOBJ_Vx_std : 391|12@0+ (0.0625,-128) [-128|127.9375] "m/s" Vector__XXX
 SG_ FC_FrFrOBJ_Vx : 372|12@0+ (0.0625,-128) [-128|127.9375] "m/s" Vector__XXX
 SG_ FC_FrFrOBJ_Vy_std : 367|10@0+ (0.125,-64) [-64|63.875] "m/s" Vector__XXX
 SG_ FC_FrFrOBJ_Vy : 345|10@0+ (0.125,-64) [-64|63.875] "m/s" Vector__XXX
 SG_ FC_FrFrOBJ_Dx_Vnce : 329|14@0+ (0.05,0) [0|50] "" Vector__XXX
 SG_ FC_FrFrOBJ_Dx : 327|13@0+ (0.0625,-256) [-256|255.9375] "m" Vector__XXX
 SG_ FC_FrFrOBJ_Dy_Vnce : 305|10@0+ (0.02,0) [0|20] "m2" Vector__XXX
 SG_ FC_FrFrOBJ_Dy : 301|11@0+ (0.125,-128) [-128|127.875] "m" Vector__XXX
 SG_ FC_FrFrOBJ_HeadingAngle : 294|9@0+ (0.01,-1.57) [-1.57|1.57] "rad" Vector__XXX
 SG_ FC_FrFrOBJ_Length : 287|9@0+ (0.05,0) [0|25.5] "m" Vector__XXX
 SG_ FC_FrFrOBJ_Height : 264|9@0+ (0.01,0) [0|5.11] "m" Vector__XXX
 SG_ FC_FrFrOBJ_Width : 259|11@0+ (0.01,0) [0|12] "m" Vector__XXX
 SG_ FC_FrFrOBJ_Class : 263|3@0+ (1,0) [0|7] "" Vector__XXX
 SG_ FC_FrOBJ_Track_Age : 223|8@0+ (1,0) [0|255] "" Vector__XXX
 SG_ FC_FrOBJ_Track_ID : 204|8@0+ (1,0) [0|255] "" Vector__XXX
 SG_ FC_FrOBJ_FusionedFC_Track_ID : 231|8@0+ (1,0) [0|255] "" Vector__XXX
 SG_ FC_FrOBJ_fusion_Sts : 207|2@0+ (1,0) [0|3] "" Vector__XXX
 SG_ FC_FrOBJ_ObstacleProb : 197|6@0+ (2,0) [0|100] "%" Vector__XXX
 SG_ FC_FrOBJ_ExistProb : 189|6@0+ (2,0) [0|100] "%" Vector__XXX
 SG_ FC_FrOBJ_Brakelight_Info : 191|1@0+ (1,0) [0|1] "" Vector__XXX
 SG_ FC_FrOBJ_Taillight_Info : 178|3@0+ (1,0) [0|7] "" Vector__XXX
 SG_ FC_FrOBJ_Dis_to_R_LaneMark : 172|9@0+ (0.01,0) [0|5] "m" Vector__XXX
 SG_ FC_FrOBJ_Dis_to_L_LaneMark : 166|9@0+ (0.01,0) [0|5] "m" Vector__XXX
 SG_ FC_FrOBJ_Ax : 145|10@0+ (0.03125,-16) [-16|15.96875] "m/s2" Vector__XXX
 SG_ FC_FrOBJ_Ay : 138|9@0+ (0.0625,-16) [-16|15.9375] "m/s2" Vector__XXX
 SG_ FC_FrOBJ_Vx_std : 135|12@0+ (0.0625,-128) [-128|127.9375] "m/s" Vector__XXX
 SG_ FC_FrOBJ_Vx : 116|12@0+ (0.0625,-128) [-128|127.9375] "m/s" Vector__XXX
 SG_ FC_FrOBJ_Vy_std : 111|10@0+ (0.125,-64) [-64|63.875] "m/s" Vector__XXX
 SG_ FC_FrOBJ_Vy : 89|10@0+ (0.125,-64) [-64|63.875] "m/s" Vector__XXX
 SG_ FC_FrOBJ_Dx_Vnce : 73|14@0+ (0.05,0) [0|50] "m2" Vector__XXX
 SG_ FC_FrOBJ_Dx : 71|13@0+ (0.0625,-256) [-256|255.9375] "m" Vector__XXX
 SG_ FC_FrOBJ_Dy_Vnce : 49|10@0+ (0.02,0) [0|20] "m2" Vector__XXX
 SG_ FC_FrOBJ_Dy : 45|11@0+ (0.125,-128) [-128|127.875] "m" Vector__XXX
 SG_ FC_FrOBJ_HeadingAngle : 38|9@0+ (0.01,-1.57) [-1.57|1.57] "rad" Vector__XXX
 SG_ FC_FrOBJ_Length : 31|9@0+ (0.05,0) [0|25.5] "m" Vector__XXX
 SG_ FC_FrOBJ_Height : 8|9@0+ (0.01,0) [0|5.11] "m" Vector__XXX
 SG_ FC_FrOBJ_Width : 3|11@0+ (0.01,0) [0|12] "m" Vector__XXX
 SG_ FC_FrOBJ_Class : 7|3@0+ (1,0) [0|7] "" Vector__XXX

BO_ 750 FC_2EE: 64 FC
 SG_ FC_RollingCounter_29C : 491|4@0+ (1,0) [0|15] "" Vector__XXX
 SG_ FC_CRCCheck_29C : 503|16@0+ (1,0) [0|65535] "" Vector__XXX
 SG_ FC_LeFrOBJ_Track_Age : 479|8@0+ (1,0) [0|255] "" Vector__XXX
 SG_ FC_LeFrOBJ_Track_ID : 460|8@0+ (1,0) [0|255] "" Vector__XXX
 SG_ FC_LeFrOBJ_FusionedFC_Track_ID : 487|8@0+ (1,0) [0|255] "" Vector__XXX
 SG_ FC_LeFrOBJ_fusion_Sts : 463|2@0+ (1,0) [0|3] "" Vector__XXX
 SG_ FC_LeFrOBJ_ObstacleProb : 453|6@0+ (2,0) [0|100] "%" Vector__XXX
 SG_ FC_LeFrOBJ_ExistProb : 445|6@0+ (2,0) [0|100] "%" Vector__XXX
 SG_ FC_LeFrOBJ_Brakelight_Info : 447|1@0+ (1,0) [0|1] "" Vector__XXX
 SG_ FC_LeFrOBJ_Taillight_Info : 434|3@0+ (1,0) [0|7] "" Vector__XXX
 SG_ FC_LeFrOBJ_Dis_to_R_LaneMark : 428|9@0+ (0.01,0) [0|5] "m" Vector__XXX
 SG_ FC_LeFrOBJ_Dis_to_L_LaneMark : 422|9@0+ (0.01,0) [0|5] "m" Vector__XXX
 SG_ FC_LeFrOBJ_Ax : 401|10@0+ (0.03125,-16) [-16|15.96875] "m/s2" Vector__XXX
 SG_ FC_LeFrOBJ_Ay : 394|9@0+ (0.0625,-16) [-16|15.9375] "m/s2" Vector__XXX
 SG_ FC_LeFrOBJ_Vx_std : 391|12@0+ (0.0625,-128) [-128|127.9375] "m/s" Vector__XXX
 SG_ FC_LeFrOBJ_Vx : 372|12@0+ (0.0625,-128) [-128|127.9375] "m/s" Vector__XXX
 SG_ FC_LeFrOBJ_Vy_std : 367|10@0+ (0.125,-64) [-64|63.875] "m/s" Vector__XXX
 SG_ FC_LeFrOBJ_Vy : 345|10@0+ (0.125,-64) [-64|63.875] "m/s" Vector__XXX
 SG_ FC_LeFrOBJ_Dx_Vnce : 329|14@0+ (0.05,0) [0|50] "" Vector__XXX
 SG_ FC_LeFrOBJ_Dx : 327|13@0+ (0.0625,-256) [-256|255.9375] "m" Vector__XXX
 SG_ FC_LeFrOBJ_Dy_Vnce : 305|10@0+ (0.02,0) [0|20] "m2" Vector__XXX
 SG_ FC_LeFrOBJ_Dy : 301|11@0+ (0.125,-128) [-128|127.875] "m" Vector__XXX
 SG_ FC_LeFrOBJ_HeadingAngle : 294|9@0+ (0.01,-1.57) [-1.57|1.57] "rad" Vector__XXX
 SG_ FC_LeFrOBJ_Length : 287|9@0+ (0.05,0) [0|25.5] "m" Vector__XXX
 SG_ FC_LeFrOBJ_Height : 264|9@0+ (0.01,0) [0|5.11] "m" Vector__XXX
 SG_ FC_LeFrOBJ_Width : 259|11@0+ (0.01,0) [0|12] "m" Vector__XXX
 SG_ FC_LeFrOBJ_Class : 263|3@0+ (1,0) [0|7] "" Vector__XXX
 SG_ FC_LeOBJ_Track_Age : 223|8@0+ (1,0) [0|255] "" Vector__XXX
 SG_ FC_LeOBJ_Track_ID : 204|8@0+ (1,0) [0|255] "" Vector__XXX
 SG_ FC_LeOBJ_FusionedFC_Track_ID : 231|8@0+ (1,0) [0|255] "" Vector__XXX
 SG_ FC_LeOBJ_fusion_Sts : 207|2@0+ (1,0) [0|3] "" Vector__XXX
 SG_ FC_LeOBJ_ObstacleProb : 197|6@0+ (2,0) [0|100] "%" Vector__XXX
 SG_ FC_LeOBJ_ExistProb : 189|6@0+ (2,0) [0|100] "%" Vector__XXX
 SG_ FC_LeOBJ_Brakelight_Info : 191|1@0+ (1,0) [0|1] "" Vector__XXX
 SG_ FC_LeOBJ_Taillight_Info : 178|3@0+ (1,0) [0|7] "" Vector__XXX
 SG_ FC_LeOBJ_Dis_to_R_LaneMark : 172|9@0+ (0.01,0) [0|5] "m" Vector__XXX
 SG_ FC_LeOBJ_Dis_to_L_LaneMark : 166|9@0+ (0.01,0) [0|5] "m" Vector__XXX
 SG_ FC_LeOBJ_Ax : 145|10@0+ (0.03125,-16) [-16|15.96875] "m/s2" Vector__XXX
 SG_ FC_LeOBJ_Ay : 138|9@0+ (0.0625,-16) [-16|15.9375] "m/s2" Vector__XXX
 SG_ FC_LeOBJ_Vx_std : 135|12@0+ (0.0625,-128) [-128|127.9375] "m/s" Vector__XXX
 SG_ FC_LeOBJ_Vx : 116|12@0+ (0.0625,-128) [-128|127.9375] "m/s" Vector__XXX
 SG_ FC_LeOBJ_Vy_std : 111|10@0+ (0.125,-64) [-64|63.875] "m/s" Vector__XXX
 SG_ FC_LeOBJ_Vy : 89|10@0+ (0.125,-64) [-64|63.875] "m/s" Vector__XXX
 SG_ FC_LeOBJ_Dx_Vnce : 73|14@0+ (0.05,0) [0|50] "" Vector__XXX
 SG_ FC_LeOBJ_Dx : 71|13@0+ (0.0625,-256) [-256|255.9375] "m" Vector__XXX
 SG_ FC_LeOBJ_Dy_Vnce : 49|10@0+ (0.02,0) [0|20] "m2" Vector__XXX
 SG_ FC_LeOBJ_Dy : 45|11@0+ (0.125,-128) [-128|127.875] "m" Vector__XXX
 SG_ FC_LeOBJ_HeadingAngle : 38|9@0+ (0.01,-1.57) [-1.57|1.57] "rad" Vector__XXX
 SG_ FC_LeOBJ_Length : 31|9@0+ (0.05,0) [0|25.5] "m" Vector__XXX
 SG_ FC_LeOBJ_Height : 8|9@0+ (0.01,0) [0|5.11] "m" Vector__XXX
 SG_ FC_LeOBJ_Width : 3|11@0+ (0.01,0) [0|12] "m" Vector__XXX
 SG_ FC_LeOBJ_Class : 7|3@0+ (1,0) [0|7] "" Vector__XXX

BO_ 756 FC_2F4: 64 FC
 SG_ FC_RollingCounter_29D : 491|4@0+ (1,0) [0|15] "" Vector__XXX
 SG_ FC_CRCCheck_29D : 503|16@0+ (1,0) [0|65535] "" Vector__XXX
 SG_ FC_RiFrOBJ_Track_Age : 479|8@0+ (1,0) [0|255] "" Vector__XXX
 SG_ FC_RiFrOBJ_Track_ID : 460|8@0+ (1,0) [0|255] "" Vector__XXX
 SG_ FC_RiFrOBJ_FusionedFC_Track_ID : 487|8@0+ (1,0) [0|255] "" Vector__XXX
 SG_ FC_RiFrOBJ_fusion_Sts : 463|2@0+ (1,0) [0|3] "" Vector__XXX
 SG_ FC_RiFrOBJ_ObstacleProb : 453|6@0+ (2,0) [0|100] "%" Vector__XXX
 SG_ FC_RiFrOBJ_ExistProb : 445|6@0+ (2,0) [0|100] "%" Vector__XXX
 SG_ FC_RiFrOBJ_Brakelight_Info : 447|1@0+ (1,0) [0|1] "" Vector__XXX
 SG_ FC_RiFrOBJ_Taillight_Info : 434|3@0+ (1,0) [0|7] "" Vector__XXX
 SG_ FC_RiFrOBJ_Dis_to_R_LaneMark : 428|9@0+ (0.01,0) [0|5] "m" Vector__XXX
 SG_ FC_RiFrOBJ_Dis_to_L_LaneMark : 422|9@0+ (0.01,0) [0|5] "m" Vector__XXX
 SG_ FC_RiFrOBJ_Ax : 401|10@0+ (0.03125,-16) [-16|15.96875] "m/s2" Vector__XXX
 SG_ FC_RiFrOBJ_Ay : 394|9@0+ (0.0625,-16) [-16|15.9375] "m/s2" Vector__XXX
 SG_ FC_RiFrOBJ_Vx_std : 391|12@0+ (0.0625,-128) [-128|127.9375] "m/s" Vector__XXX
 SG_ FC_RiFrOBJ_Vx : 372|12@0+ (0.0625,-128) [-128|127.9375] "m/s" Vector__XXX
 SG_ FC_RiFrOBJ_Vy_std : 367|10@0+ (0.125,-64) [-64|63.875] "m/s" Vector__XXX
 SG_ FC_RiFrOBJ_Vy : 345|10@0+ (0.125,-64) [-64|63.875] "m/s" Vector__XXX
 SG_ FC_RiFrOBJ_Dx_Vnce : 329|14@0+ (0.05,0) [0|50] "" Vector__XXX
 SG_ FC_RiFrOBJ_Dx : 327|13@0+ (0.0625,-256) [-256|255.9375] "m" Vector__XXX
 SG_ FC_RiFrOBJ_Dy_Vnce : 305|10@0+ (0.02,0) [0|20] "m2" Vector__XXX
 SG_ FC_RiFrOBJ_Dy : 301|11@0+ (0.125,-128) [-128|127.875] "m" Vector__XXX
 SG_ FC_RiFrOBJ_HeadingAngle : 294|9@0+ (0.01,-1.57) [-1.57|1.57] "rad" Vector__XXX
 SG_ FC_RiFrOBJ_Length : 287|9@0+ (0.05,0) [0|25.5] "m" Vector__XXX
 SG_ FC_RiFrOBJ_Height : 264|9@0+ (0.01,0) [0|5.11] "m" Vector__XXX
 SG_ FC_RiFrOBJ_Width : 259|11@0+ (0.01,0) [0|12] "m" Vector__XXX
 SG_ FC_RiFrOBJ_Class : 263|3@0+ (1,0) [0|7] "" Vector__XXX
 SG_ FC_RiOBJ_Track_Age : 223|8@0+ (1,0) [0|255] "" Vector__XXX
 SG_ FC_RiOBJ_Track_ID : 204|8@0+ (1,0) [0|255] "" Vector__XXX
 SG_ FC_RiOBJ_FusionedFC_Track_ID : 231|8@0+ (1,0) [0|255] "" Vector__XXX
 SG_ FC_RiOBJ_fusion_Sts : 207|2@0+ (1,0) [0|3] "" Vector__XXX
 SG_ FC_RiOBJ_ObstacleProb : 197|6@0+ (2,0) [0|100] "%" Vector__XXX
 SG_ FC_RiOBJ_ExistProb : 189|6@0+ (2,0) [0|100] "%" Vector__XXX
 SG_ FC_RiOBJ_Brakelight_Info : 191|1@0+ (1,0) [0|1] "" Vector__XXX
 SG_ FC_RiOBJ_Taillight_Info : 178|3@0+ (1,0) [0|7] "" Vector__XXX
 SG_ FC_RiOBJ_Dis_to_R_LaneMark : 172|9@0+ (0.01,0) [0|5] "m" Vector__XXX
 SG_ FC_RiOBJ_Dis_to_L_LaneMark : 166|9@0+ (0.01,0) [0|5] "m" Vector__XXX
 SG_ FC_RiOBJ_Ax : 145|10@0+ (0.03125,-16) [-16|15.96875] "m/s2" Vector__XXX
 SG_ FC_RiOBJ_Ay : 138|9@0+ (0.0625,-16) [-16|15.9375] "m/s2" Vector__XXX
 SG_ FC_RiOBJ_Vx_std : 135|12@0+ (0.0625,-128) [-128|127.9375] "m/s" Vector__XXX
 SG_ FC_RiOBJ_Vx : 116|12@0+ (0.0625,-128) [-128|127.9375] "m/s" Vector__XXX
 SG_ FC_RiOBJ_Vy_std : 111|10@0+ (0.125,-64) [-64|63.875] "m/s" Vector__XXX
 SG_ FC_RiOBJ_Vy : 89|10@0+ (0.125,-64) [-64|63.875] "m/s" Vector__XXX
 SG_ FC_RiOBJ_Dx_Vnce : 73|14@0+ (0.05,0) [0|50] "" Vector__XXX
 SG_ FC_RiOBJ_Dx : 71|13@0+ (0.0625,-256) [-256|255.9375] "m" Vector__XXX
 SG_ FC_RiOBJ_Dy_Vnce : 49|10@0+ (0.02,0) [0|20] "m2" Vector__XXX
 SG_ FC_RiOBJ_Dy : 45|11@0+ (0.125,-128) [-128|127.875] "m" Vector__XXX
 SG_ FC_RiOBJ_HeadingAngle : 38|9@0+ (0.01,-1.57) [-1.57|1.57] "rad" Vector__XXX
 SG_ FC_RiOBJ_Length : 31|9@0+ (0.05,0) [0|25.5] "m" Vector__XXX
 SG_ FC_RiOBJ_Height : 8|9@0+ (0.01,0) [0|5.11] "m" Vector__XXX
 SG_ FC_RiOBJ_Width : 3|11@0+ (0.01,0) [0|12] "m" Vector__XXX
 SG_ FC_RiOBJ_Class : 7|3@0+ (1,0) [0|7] "" Vector__XXX

BO_ 831 FC_33F: 64 FC
 SG_ LAS_RollingCounter_33F : 491|4@0+ (1,0) [0|15] "" Vector__XXX
 SG_ LAS_CRCCheck_33F : 503|16@0+ (1,0) [0|65535] "" Vector__XXX
 SG_ LAS_Line_06_curvature_alte_FT : 11|12@0+ (1.272E-007,-0.00026042) [-0.00026042|0.000260417] "1/m2" Vector__XXX
 SG_ LAS_Line_05_curvature_alte_FT : 7|12@0+ (1.272E-007,-0.00026042) [-0.00026042|0.000260417] "1/m2" Vector__XXX

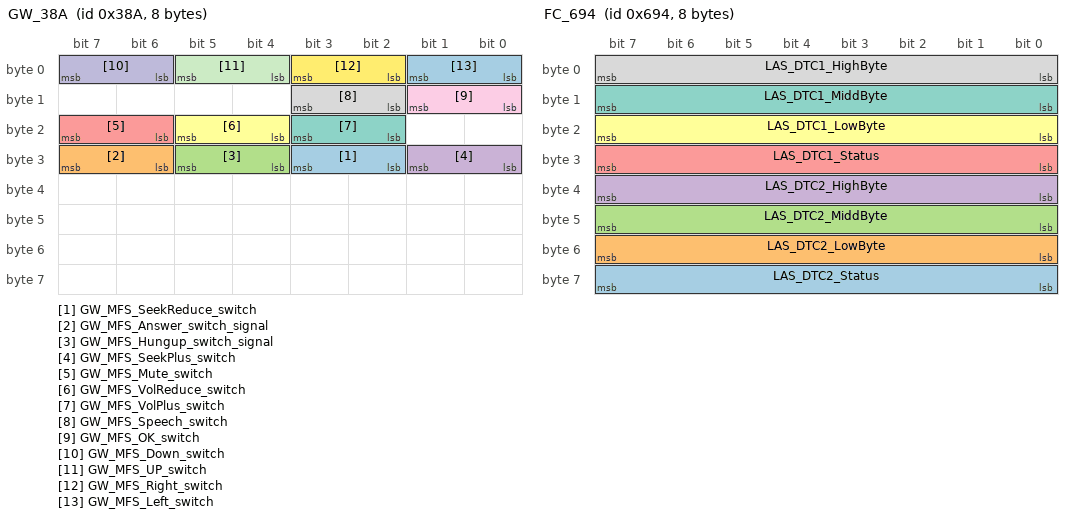
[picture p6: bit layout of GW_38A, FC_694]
BO_ 906 GW_38A: 8 Vector__XXX
 SG_ GW_MFS_SeekReduce_switch : 27|2@0+ (1,0) [0|3] ""  FC
 SG_ GW_MFS_Answer_switch_signal : 31|2@0+ (1,0) [0|3] ""  FC
 SG_ GW_MFS_Hungup_switch_signal : 29|2@0+ (1,0) [0|3] ""  FC
 SG_ GW_MFS_SeekPlus_switch : 25|2@0+ (1,0) [0|3] ""  FC
 SG_ GW_MFS_Mute_switch : 23|2@0+ (1,0) [0|3] ""  FC
 SG_ GW_MFS_VolReduce_switch : 21|2@0+ (1,0) [0|3] ""  FC
 SG_ GW_MFS_VolPlus_switch : 19|2@0+ (1,0) [0|3] ""  FC
 SG_ GW_MFS_Speech_switch : 11|2@0+ (1,0) [0|3] ""  FC
 SG_ GW_MFS_OK_switch : 9|2@0+ (1,0) [0|3] ""  FC
 SG_ GW_MFS_Down_switch : 7|2@0+ (1,0) [0|3] ""  FC
 SG_ GW_MFS_UP_switch : 5|2@0+ (1,0) [0|3] ""  FC
 SG_ GW_MFS_Right_switch : 3|2@0+ (1,0) [0|3] ""  FC
 SG_ GW_MFS_Left_switch : 1|2@0+ (1,0) [0|3] ""  FC

BO_ 1000 GW_3E8: 8 Vector__XXX
 SG_ BCM_SOF_Q_STATE : 51|2@0+ (1,0) [0|3] ""  FC
 SG_ BCM_SOF_Q : 15|8@0+ (0.5,0) [0|127] "Ah"  FC

BO_ 1684 FC_694: 8 FC
 SG_ LAS_DTC2_Status : 63|8@0+ (1,0) [0|255] "" Vector__XXX
 SG_ LAS_DTC2_LowByte : 55|8@0+ (1,0) [0|255] "" Vector__XXX
 SG_ LAS_DTC2_MiddByte : 47|8@0+ (1,0) [0|255] "" Vector__XXX
 SG_ LAS_DTC2_HighByte : 39|8@0+ (1,0) [0|255] "" Vector__XXX
 SG_ LAS_DTC1_Status : 31|8@0+ (1,0) [0|255] "" Vector__XXX
 SG_ LAS_DTC1_LowByte : 23|8@0+ (1,0) [0|255] "" Vector__XXX
 SG_ LAS_DTC1_MiddByte : 15|8@0+ (1,0) [0|255] "" Vector__XXX
 SG_ LAS_DTC1_HighByte : 7|8@0+ (1,0) [0|255] "" Vector__XXX

BO_ 723 FC_2D3: 64 FC
 SG_ ACC_CRCCheck_283 : 127|8@0+ (1,0) [0|255] "" Vector__XXX
 SG_ ACC_RollingCounter_283 : 115|4@0+ (1,0) [0|15] "" Vector__XXX
 SG_ ACC_AEBTargetLatRelSpeed_for_SRS : 77|10@0+ (0.125,-64) [-64|63.875] "m/s" Vector__XXX
 SG_ ACC_AEBTargetLatRange_for_SRS : 71|10@0+ (0.1,-50) [-50|50] "m" Vector__XXX
 SG_ ACC_CRCCheckr_282 : 63|8@0+ (1,0) [0|255] "" Vector__XXX
 SG_ ACC_RollingCounter_282 : 51|4@0+ (1,0) [0|15] "" Vector__XXX
 SG_ ACC_AEBTargetProb_for_SRS : 38|7@0+ (1,0) [0|100] "%" Vector__XXX
 SG_ ACC_AEBTargetType_for_SRS : 26|4@0+ (1,0) [0|15] "" Vector__XXX
 SG_ ACC_AEBTargetTTC_for_SRS : 18|8@0+ (0.01,0.01) [0.01|2.5] "s" Vector__XXX
 SG_ ACC_AEBTargetRelSpeed_for_SRS : 11|9@0+ (1,-250) [-250|250] "km/h" Vector__XXX
 SG_ ACC_AEBTargetLngRange_for_SRS : 4|9@0+ (0.5,-70) [-70|180] "m" Vector__XXX
 SG_ ACC_AEBActive_for_SRS : 5|1@0+ (1,0) [0|1] "" Vector__XXX
 SG_ ACC_AEBStatus_for_SRS : 7|2@0+ (1,0) [0|3] "" Vector__XXX

BO_ 780 FC_30C: 8 FC
 SG_ LAS_ResetSts : 7|3@0+ (1,0) [0|7] "" Vector__XXX

BO_ 738 GW_2E2: 64 Vector__XXX
 SG_ RLR_CRCCheck_2E2 : 503|16@0+ (1,0) [0|65535] ""  FC
 SG_ RLR_RollingCounter_2E2 : 491|4@0+ (1,0) [0|15] ""  FC
 SG_ RLR_ElkOBJ2_Measured : 313|2@0+ (1,0) [0|3] ""  FC
 SG_ RLR_ElkOBJ2_ExistProb : 319|6@0+ (2,0) [0|100] "%"  FC
 SG_ RLR_ElkOBJ2_Location : 305|2@0+ (1,0) [0|3] ""  FC
 SG_ RLR_ElkOBJ2_RelAx : 298|9@0+ (0.0625,-16) [-16|15.9375] "m/s2"  FC
 SG_ RLR_ElkOBJ2_RelAy : 292|10@0+ (0.03125,-16) [-16|15.9688] "m/s2"  FC
 SG_ RLR_ElkOBJ2_RelVx : 272|12@0+ (0.0625,-128) [-128|127.938] "m/s"  FC
 SG_ RLR_ElkOBJ2_RelVy : 266|10@0+ (0.125,-64) [-64|63.875] "m/s"  FC
 SG_ RLR_ElkOBJ2_Dx : 263|13@0+ (0.0625,-256) [-256|255.938] "m"  FC
 SG_ RLR_ElkOBJ2_RefPointLoc : 251|3@0+ (1,0) [0|7] ""  FC
 SG_ RLR_ElkOBJ2_Dy : 246|11@0+ (0.125,-128) [-128|127.875] "m"  FC
 SG_ RLR_ElkOBJ2_HeadingAngle : 224|10@0+ (0.01,-3.14) [-3.14|3.14] "rad"  FC
 SG_ RLR_ElkOBJ2_Length : 217|9@0+ (0.05,0) [0|25.5] "m"  FC
 SG_ RLR_ElkOBJ2_Height : 210|9@0+ (0.01,0) [0|5.11] "m"  FC
 SG_ RLR_ElkOBJ2_Width : 205|11@0+ (0.01,0) [0|12] "m"  FC
 SG_ RLR_ElkOBJ2_Type : 192|3@0+ (1,0) [0|7] ""  FC
 SG_ RLR_ElkOBJ2_Track_ID : 199|7@0+ (1,0) [0|127] ""  FC
 SG_ RLR_ElkOBJ2_RefPointDx : 168|13@0+ (0.0625,-256) [-256|255.938] "m"  FC
 SG_ RLR_ElkOBJ2_RefPointDy : 163|11@0+ (0.125,-128) [-128|127.875] "m"  FC
 SG_ RLR_ElkOBJ2_ObstacleProb : 153|6@0+ (2,0) [0|100] "%"  FC
 SG_ RLR_ElkOBJ1_RefPointDx : 150|13@0+ (0.0625,-256) [-256|255.938] "m"  FC
 SG_ RLR_ElkOBJ1_RefPointDy : 129|11@0+ (0.125,-128) [-128|127.875] "m"  FC
 SG_ RLR_ElkOBJ1_ObstacleProb : 135|6@0+ (2,0) [0|100] "%"  FC
 SG_ RLR_ElkOBJ1_Measured : 121|2@0+ (1,0) [0|3] ""  FC
 SG_ RLR_ElkOBJ1_ExistProb : 127|6@0+ (2,0) [0|100] "%"  FC
 SG_ RLR_ElkOBJ1_Location : 113|2@0+ (1,0) [0|3] ""  FC
 SG_ RLR_ElkOBJ1_RelAx : 106|9@0+ (0.0625,-16) [-16|15.9375] "m/s2"  FC
 SG_ RLR_ElkOBJ1_RelAy : 100|10@0+ (0.03125,-16) [-16|15.9688] "m/s2"  FC
 SG_ RLR_ElkOBJ1_RelVx : 80|12@0+ (0.0625,-128) [-128|127.938] "m/s"  FC
 SG_ RLR_ElkOBJ1_RelVy : 74|10@0+ (0.125,-64) [-64|63.875] "m/s"  FC
 SG_ RLR_ElkOBJ1_Dx : 71|13@0+ (0.0625,-256) [-256|255.938] "m"  FC
 SG_ RLR_ElkOBJ1_RefPointLoc : 59|3@0+ (1,0) [0|7] ""  FC
 SG_ RLR_ElkOBJ1_Dy : 54|11@0+ (0.125,-128) [-128|127.875] "m"  FC
 SG_ RLR_ElkOBJ1_HeadingAngle : 32|10@0+ (0.01,-3.14) [-3.14|3.14] "rad"  FC
 SG_ RLR_ElkOBJ1_Length : 25|9@0+ (0.05,0) [0|25.5] "m"  FC
 SG_ RLR_ElkOBJ1_Height : 18|9@0+ (0.01,0) [0|5.11] "m"  FC
 SG_ RLR_ElkOBJ1_Width : 13|11@0+ (0.01,0) [0|12] "m"  FC
 SG_ RLR_ElkOBJ1_Type : 0|3@0+ (1,0) [0|7] ""  FC
 SG_ RLR_ElkOBJ1_Track_ID : 7|7@0+ (1,0) [0|127] ""  FC

BO_ 739 GW_2E3: 64 Vector__XXX
 SG_ RLR_CRCCheck_2E3 : 503|16@0+ (1,0) [0|65535] ""  FC
 SG_ RLR_RollingCounter_2E3 : 491|4@0+ (1,0) [0|15] ""  FC
 SG_ RLR_ElkOBJ4_Measured : 313|2@0+ (1,0) [0|3] ""  FC
 SG_ RLR_ElkOBJ4_ExistProb : 319|6@0+ (2,0) [0|100] "%"  FC
 SG_ RLR_ElkOBJ4_Location : 305|2@0+ (1,0) [0|3] ""  FC
 SG_ RLR_ElkOBJ4_RelAx : 298|9@0+ (0.0625,-16) [-16|15.9375] "m/s2"  FC
 SG_ RLR_ElkOBJ4_RelAy : 292|10@0+ (0.03125,-16) [-16|15.9688] "m/s2"  FC
 SG_ RLR_ElkOBJ4_RelVx : 272|12@0+ (0.0625,-128) [-128|127.938] "m/s"  FC
 SG_ RLR_ElkOBJ4_RelVy : 266|10@0+ (0.125,-64) [-64|63.875] "m/s"  FC
 SG_ RLR_ElkOBJ4_Dx : 263|13@0+ (0.0625,-256) [-256|255.938] "m"  FC
 SG_ RLR_ElkOBJ4_RefPointLoc : 251|3@0+ (1,0) [0|7] ""  FC
 SG_ RLR_ElkOBJ4_Dy : 246|11@0+ (0.125,-128) [-128|127.875] "m"  FC
 SG_ RLR_ElkOBJ4_HeadingAngle : 224|10@0+ (0.01,-3.14) [-3.14|3.14] "rad"  FC
 SG_ RLR_ElkOBJ4_Length : 217|9@0+ (0.05,0) [0|25.5] "m"  FC
 SG_ RLR_ElkOBJ4_Height : 210|9@0+ (0.01,0) [0|5.11] "m"  FC
 SG_ RLR_ElkOBJ4_Width : 205|11@0+ (0.01,0) [0|12] "m"  FC
 SG_ RLR_ElkOBJ4_Type : 192|3@0+ (1,0) [0|7] ""  FC
 SG_ RLR_ElkOBJ4_Track_ID : 199|7@0+ (1,0) [0|127] ""  FC
 SG_ RLR_ElkOBJ4_RefPointDx : 168|13@0+ (0.0625,-256) [-256|255.938] "m"  FC
 SG_ RLR_ElkOBJ4_RefPointDy : 163|11@0+ (0.125,-128) [-128|127.875] "m"  FC
 SG_ RLR_ElkOBJ4_ObstacleProb : 153|6@0+ (2,0) [0|100] "%"  FC
 SG_ RLR_ElkOBJ3_RefPointDx : 150|13@0+ (0.0625,-256) [-256|255.938] "m"  FC
 SG_ RLR_ElkOBJ3_RefPointDy : 129|11@0+ (0.125,-128) [-128|127.875] "m"  FC
 SG_ RLR_ElkOBJ3_ObstacleProb : 135|6@0+ (2,0) [0|100] "%"  FC
 SG_ RLR_ElkOBJ3_Measured : 121|2@0+ (1,0) [0|3] ""  FC
 SG_ RLR_ElkOBJ3_ExistProb : 127|6@0+ (2,0) [0|100] "%"  FC
 SG_ RLR_ElkOBJ3_Location : 113|2@0+ (1,0) [0|3] ""  FC
 SG_ RLR_ElkOBJ3_RelAx : 106|9@0+ (0.0625,-16) [-16|15.9375] "m/s2"  FC
 SG_ RLR_ElkOBJ3_RelAy : 100|10@0+ (0.03125,-16) [-16|15.9688] "m/s2"  FC
 SG_ RLR_ElkOBJ3_RelVx : 80|12@0+ (0.0625,-128) [-128|127.938] "m/s"  FC
 SG_ RLR_ElkOBJ3_RelVy : 74|10@0+ (0.125,-64) [-64|63.875] "m/s"  FC
 SG_ RLR_ElkOBJ3_Dx : 71|13@0+ (0.0625,-256) [-256|255.938] "m"  FC
 SG_ RLR_ElkOBJ3_RefPointLoc : 59|3@0+ (1,0) [0|7] ""  FC
 SG_ RLR_ElkOBJ3_Dy : 54|11@0+ (0.125,-128) [-128|127.875] "m"  FC
 SG_ RLR_ElkOBJ3_HeadingAngle : 32|10@0+ (0.01,-3.14) [-3.14|3.14] "rad"  FC
 SG_ RLR_ElkOBJ3_Length : 25|9@0+ (0.05,0) [0|25.5] "m"  FC
 SG_ RLR_ElkOBJ3_Height : 18|9@0+ (0.01,0) [0|5.11] "m"  FC
 SG_ RLR_ElkOBJ3_Width : 13|11@0+ (0.01,0) [0|12] "m"  FC
 SG_ RLR_ElkOBJ3_Type : 0|3@0+ (1,0) [0|7] ""  FC
 SG_ RLR_ElkOBJ3_Track_ID : 7|7@0+ (1,0) [0|127] ""  FC

BO_ 1304 GW_518: 8 Vector__XXX
 SG_ BCM_CarMode : 11|2@0+ (1,0) [0|3] ""  FC

BO_ 686 GW_2AE: 8 Vector__XXX
 SG_ LCDAL_SystemStatus : 6|3@0+ (1,0) [0|7] ""  FC

BO_ 985 FC_3D9: 64 FC
 SG_ ACC_ObsTarget10ID : 306|5@0+ (1,0) [0|31] "" Vector__XXX
 SG_ ACC_ObsTarget10Type : 309|3@0+ (1,0) [0|7] "" Vector__XXX
 SG_ ACC_ObsTarget10LatRange : 303|10@0+ (0.1,-50) [-50|50] "m" Vector__XXX
 SG_ ACC_ObsTarget10LngRange : 282|11@0+ (0.1,-20) [-20|120] "m" Vector__XXX
 SG_ ACC_ObsTarget9ID : 287|5@0+ (1,0) [0|31] "" Vector__XXX
 SG_ ACC_ObsTarget9Type : 274|3@0+ (1,0) [0|7] "" Vector__XXX
 SG_ ACC_ObsTarget9LatRange : 268|10@0+ (0.1,-50) [-50|50] "m" Vector__XXX
 SG_ ACC_ObsTarget9LngRange : 263|11@0+ (0.1,-20) [-20|120] "m" Vector__XXX
 SG_ ACC_ObsTarget8ID : 242|5@0+ (1,0) [0|31] "" Vector__XXX
 SG_ ACC_ObsTarget8Type : 245|3@0+ (1,0) [0|7] "" Vector__XXX
 SG_ ACC_ObsTarget8LatRange : 239|10@0+ (0.1,-50) [-50|50] "m" Vector__XXX
 SG_ ACC_ObsTarget8LngRange : 218|11@0+ (0.1,-20) [-20|120] "m" Vector__XXX
 SG_ ACC_ObsTarget7ID : 223|5@0+ (1,0) [0|31] "" Vector__XXX
 SG_ ACC_ObsTarget7Type : 210|3@0+ (1,0) [0|7] "" Vector__XXX
 SG_ ACC_ObsTarget7LatRange : 204|10@0+ (0.1,-50) [-50|50] "m" Vector__XXX
 SG_ ACC_ObsTarget7LngRange : 199|11@0+ (0.1,-20) [-20|120] "m" Vector__XXX
 SG_ ACC_ObsTarget6ID : 178|5@0+ (1,0) [0|31] "" Vector__XXX
 SG_ ACC_ObsTarget6Type : 181|3@0+ (1,0) [0|7] "" Vector__XXX
 SG_ ACC_ObsTarget6LatRange : 175|10@0+ (0.1,-50) [-50|50] "m" Vector__XXX
 SG_ ACC_ObsTarget6LngRange : 154|11@0+ (0.1,-20) [-20|120] "m" Vector__XXX
 SG_ ACC_ObsTarget5ID : 159|5@0+ (1,0) [0|31] "" Vector__XXX
 SG_ ACC_ObsTarget5Type : 146|3@0+ (1,0) [0|7] "" Vector__XXX
 SG_ ACC_ObsTarget5LatRange : 140|10@0+ (0.1,-50) [-50|50] "m" Vector__XXX
 SG_ ACC_ObsTarget5LngRange : 135|11@0+ (0.1,-20) [-20|120] "m" Vector__XXX
 SG_ ACC_ObsTarget4ID : 114|5@0+ (1,0) [0|31] "" Vector__XXX
 SG_ ACC_ObsTarget4Type : 117|3@0+ (1,0) [0|7] "" Vector__XXX
 SG_ ACC_ObsTarget4LatRange : 111|10@0+ (0.1,-50) [-50|50] "m" Vector__XXX
 SG_ ACC_ObsTarget4LngRange : 90|11@0+ (0.1,-20) [-20|120] "m" Vector__XXX
 SG_ ACC_ObsTarget3ID : 95|5@0+ (1,0) [0|31] "" Vector__XXX
 SG_ ACC_ObsTarget3Type : 82|3@0+ (1,0) [0|7] "" Vector__XXX
 SG_ ACC_ObsTarget3LatRange : 76|10@0+ (0.1,-50) [-50|50] "m" Vector__XXX
 SG_ ACC_ObsTarget3LngRange : 71|11@0+ (0.1,-20) [-20|120] "m" Vector__XXX
 SG_ ACC_ObsTarget2ID : 50|5@0+ (1,0) [0|31] "" Vector__XXX
 SG_ ACC_ObsTarget2Type : 53|3@0+ (1,0) [0|7] "" Vector__XXX
 SG_ ACC_ObsTarget2LatRange : 47|10@0+ (0.1,-50) [-50|50] "m" Vector__XXX
 SG_ ACC_ObsTarget2LngRange : 26|11@0+ (0.1,-20) [-20|120] "m" Vector__XXX
 SG_ ACC_ObsTarget1ID : 31|5@0+ (1,0) [0|31] "" Vector__XXX
 SG_ ACC_ObsTarget1Type : 18|3@0+ (1,0) [0|7] "" Vector__XXX
 SG_ ACC_ObsTarget1LatRange : 12|10@0+ (0.1,-50) [-50|50] "m" Vector__XXX
 SG_ ACC_ObsTarget1LngRange : 7|11@0+ (0.1,-20) [-20|120] "m" Vector__XXX

BO_ 987 FC_3DB: 64 FC
 SG_ ACC_ObsTarget20ID : 306|5@0+ (1,0) [0|31] "" Vector__XXX
 SG_ ACC_ObsTarget20Type : 309|3@0+ (1,0) [0|7] "" Vector__XXX
 SG_ ACC_ObsTarget20LatRange : 303|10@0+ (0.1,-50) [-50|50] "m" Vector__XXX
 SG_ ACC_ObsTarget20LngRange : 282|11@0+ (0.1,-20) [-20|120] "m" Vector__XXX
 SG_ ACC_ObsTarget19ID : 287|5@0+ (1,0) [0|31] "" Vector__XXX
 SG_ ACC_ObsTarget19Type : 274|3@0+ (1,0) [0|7] "" Vector__XXX
 SG_ ACC_ObsTarget19LatRange : 268|10@0+ (0.1,-50) [-50|50] "m" Vector__XXX
 SG_ ACC_ObsTarget19LngRange : 263|11@0+ (0.1,-20) [-20|120] "m" Vector__XXX
 SG_ ACC_ObsTarget18ID : 242|5@0+ (1,0) [0|31] "" Vector__XXX
 SG_ ACC_ObsTarget18Type : 245|3@0+ (1,0) [0|7] "" Vector__XXX
 SG_ ACC_ObsTarget18LatRange : 239|10@0+ (0.1,-50) [-50|50] "m" Vector__XXX
 SG_ ACC_ObsTarget18LngRange : 218|11@0+ (0.1,-20) [-20|120] "m" Vector__XXX
 SG_ ACC_ObsTarget17ID : 223|5@0+ (1,0) [0|31] "" Vector__XXX
 SG_ ACC_ObsTarget17Type : 210|3@0+ (1,0) [0|7] "" Vector__XXX
 SG_ ACC_ObsTarget17LatRange : 204|10@0+ (0.1,-50) [-50|50] "m" Vector__XXX
 SG_ ACC_ObsTarget17LngRange : 199|11@0+ (0.1,-20) [-20|120] "m" Vector__XXX
 SG_ ACC_ObsTarget16ID : 178|5@0+ (1,0) [0|31] "" Vector__XXX
 SG_ ACC_ObsTarget16Type : 181|3@0+ (1,0) [0|7] "" Vector__XXX
 SG_ ACC_ObsTarget16LatRange : 175|10@0+ (0.1,-50) [-50|50] "m" Vector__XXX
 SG_ ACC_ObsTarget16LngRange : 154|11@0+ (0.1,-20) [-20|120] "m" Vector__XXX
 SG_ ACC_ObsTarget15ID : 159|5@0+ (1,0) [0|31] "" Vector__XXX
 SG_ ACC_ObsTarget15Type : 146|3@0+ (1,0) [0|7] "" Vector__XXX
 SG_ ACC_ObsTarget15LatRange : 140|10@0+ (0.1,-50) [-50|50] "m" Vector__XXX
 SG_ ACC_ObsTarget15LngRange : 135|11@0+ (0.1,-20) [-20|120] "m" Vector__XXX
 SG_ ACC_ObsTarget14ID : 114|5@0+ (1,0) [0|31] "" Vector__XXX
 SG_ ACC_ObsTarget14Type : 117|3@0+ (1,0) [0|7] "" Vector__XXX
 SG_ ACC_ObsTarget14LatRange : 111|10@0+ (0.1,-50) [-50|50] "m" Vector__XXX
 SG_ ACC_ObsTarget14LngRange : 90|11@0+ (0.1,-20) [-20|120] "m" Vector__XXX
 SG_ ACC_ObsTarget13ID : 95|5@0+ (1,0) [0|31] "" Vector__XXX
 SG_ ACC_ObsTarget13Type : 82|3@0+ (1,0) [0|7] "" Vector__XXX
 SG_ ACC_ObsTarget13LatRange : 76|10@0+ (0.1,-50) [-50|50] "m" Vector__XXX
 SG_ ACC_ObsTarget13LngRange : 71|11@0+ (0.1,-20) [-20|120] "m" Vector__XXX
 SG_ ACC_ObsTarget12ID : 50|5@0+ (1,0) [0|31] "" Vector__XXX
 SG_ ACC_ObsTarget12Type : 53|3@0+ (1,0) [0|7] "" Vector__XXX
 SG_ ACC_ObsTarget12LatRange : 47|10@0+ (0.1,-50) [-50|50] "m" Vector__XXX
 SG_ ACC_ObsTarget12LngRange : 26|11@0+ (0.1,-20) [-20|120] "m" Vector__XXX
 SG_ ACC_ObsTarget11ID : 31|5@0+ (1,0) [0|31] "" Vector__XXX
 SG_ ACC_ObsTarget11Type : 18|3@0+ (1,0) [0|7] "" Vector__XXX
 SG_ ACC_ObsTarget11LatRange : 12|10@0+ (0.1,-50) [-50|50] "m" Vector__XXX
 SG_ ACC_ObsTarget11LngRange : 7|11@0+ (0.1,-20) [-20|120] "m" Vector__XXX

CM_ BO_ 999 " ";
CM_ SG_ 999 BCM_Status_Temp "GW报文转发 ";
CM_ SG_ 999 BCM_T_BATT "GW报文转发 ";
CM_ BO_ 1021 " ";
CM_ BO_ 1310 " ";
CM_ SG_ 1310 TPMS_TirePosition "GW报文转发 ";
CM_ BO_ 1374 " ";
CM_ SG_ 1374 ADS_FCEventTimeSecond "仅800W摄像头、ADS或ADC配置才有 ";
CM_ SG_ 1374 ADS_FCEventTimeMinute "仅800W摄像头、ADS或ADC配置才有 ";
CM_ SG_ 1374 ADS_FCEventTimeHour "仅800W摄像头、ADS或ADC配置才有 ";
CM_ SG_ 1374 ADS_FCEventTimeDay "仅800W摄像头、ADS或ADC配置才有 ";
CM_ SG_ 1374 ADS_FCEventTimeMonth "仅800W摄像头、ADS或ADC配置才有 ";
CM_ SG_ 1374 ADS_FCEventTimeYear "仅800W摄像头、ADS或ADC配置才有 ";
CM_ SG_ 1374 ADS_FCEventCode "仅800W摄像头、ADS或ADC配置才有 ";
CM_ SG_ 1374 ADS_FCEventAmount "仅800W摄像头、ADS或ADC配置才有 ";
CM_ SG_ 1374 ADS_FCEventStartEndIdentify "仅800W摄像头、ADS或ADC配置才有 ";
CM_ SG_ 1374 ADS_FCEID "仅800W摄像头、ADS或ADC配置才有 ";
CM_ SG_ 1374 ADS_FCControllerCode "仅800W摄像头、ADS或ADC配置才有 ";
CM_ BO_ 652 "MFS_LIN_2 ";
CM_ SG_ 652 GW_MFS_CRCCheck_28C "GW对LIN的CRC重新计算并发出 ";
CM_ BO_ 1426 " ";
CM_ SG_ 1426 LAS_NotSleep_BYTE7BIT1 " ";
CM_ SG_ 1426 LAS_NotSleep_BYTE7BIT0 " ";
CM_ SG_ 1426 LAS_WakeUp_BYTE4BIT1 " ";
CM_ SG_ 1426 LAS_WakeUp_BYTE4BIT0 " ";
CM_ BO_ 1428 " ";
CM_ SG_ 1428 FR_NotSleep_BYTE7BIT1 " ";
CM_ SG_ 1428 FR_NotSleep_BYTE7BIT0 " ";
CM_ SG_ 1428 FR_WakeUp_BYTE4BIT1 " ";
CM_ SG_ 1428 FR_WakeUp_BYTE4BIT0 " ";
CM_ BO_ 1106 "Diag--VDC--ADAS1
TX 100M--VDC--T1 100/100R--NULL ";
CM_ BO_ 80 " ";
CM_ SG_ 80 SRS_DriverBuckleSwitchStatus "ACM接收为AT专用 ";
CM_ SG_ 80 SRS_RollingCounter_id050 "ACM接收为AT专用 ";
CM_ BO_ 898 " ";
CM_ SG_ 898 ACC_CRCCheck_3E6 " ";
CM_ SG_ 898 ACC_RollingCounter_3E6 "rolling counter ";
CM_ SG_ 898 ACC_LaneEquationC3 " ";
CM_ SG_ 898 ACC_LaneEquationC2 " ";
CM_ SG_ 898 ACC_LaneEquationC1 " ";
CM_ SG_ 898 ACC_LaneQuality " ";
CM_ SG_ 898 ACC_CRCCheck_35C " ";
CM_ SG_ 898 ACC_RollingCounter_35C "rolling counter ";
CM_ SG_ 898 ACC_FRTarget2Type " ";
CM_ SG_ 898 ACC_FRTarget2LatRange " ";
CM_ SG_ 898 ACC_FRTarget2LngRange "负数代表向后，正数代表向前，原点为前雷达波束发射面 ";
CM_ SG_ 898 ACC_FRTarget2Detection " ";
CM_ SG_ 898 ACC_FRTarget2Direction " ";
CM_ SG_ 898 ACC_CRCCheck_35D " ";
CM_ SG_ 898 ACC_RollingCounter_35D "rolling counter ";
CM_ SG_ 898 ACC_FRTarget1Direction " ";
CM_ SG_ 898 ACC_FRTarget1LngRange "负数代表向后，正数代表向前，原点为前雷达波束发射面 ";
CM_ SG_ 898 ACC_FLTarget2LatRange " ";
CM_ BO_ 1328 " ";
CM_ SG_ 1328 IP_TotalOdometer "GW报文转发 ";
CM_ BO_ 391 " ";
CM_ SG_ 391 ESP_VehicleSpeed "TCU接收为DCT专用
ACM接收为AT/DCT专用 ";
CM_ SG_ 391 ESP_VehicleSpeedValid "TCU接收为DCT专用
ACM接收为AT/DCT专用 ";
CM_ SG_ 391 ESP_ESPActiveStatus "TCU接收为DCT专用 ";
CM_ SG_ 391 ESP_EngTorqInc "燃烧扭矩 ";
CM_ SG_ 391 ESP_RollingCounter_187 "AT/DCT
ACM接收为AT/DCT专用 ";
CM_ SG_ 391 ESP_CRCCheck_187 "AT/DCT ";
CM_ BO_ 407 " ";
CM_ SG_ 407 ESP_RollingCounter_197 "TCU接收为DCT专用 ";
CM_ SG_ 407 EPB_FailStatus "TCU接收为DCT专用 ";
CM_ SG_ 407 EPB_AchievedClampForce "TCU接收为DCT专用 ";
CM_ SG_ 407 ESP_CRCCheck_197 " ";
CM_ BO_ 523 " ";
CM_ SG_ 523 Wheel_Speed_RR_Pulse "All4wheelpulsesignalsaresentbyABSwithoutfiltering.Theriseedgeandfalledgearebothcountedinit,thewheelpulsemustbesequentialintheway0,1,2…254,0,1… ";
CM_ SG_ 523 Wheel_Speed_RL_Pulse "All4wheelpulsesignalsaresentbyABSwithoutfiltering.Theriseedgeandfalledgearebothcountedinit,thewheelpulsemustbesequentialintheway0,1,2…254,0,2… ";
CM_ SG_ 523 ESP_RollingCounter_277 "rollingcounter ";
CM_ SG_ 523 ESP_RollingCounter_258 "258 ";
CM_ SG_ 523 ESP_RollingCounter_208 "rollingcounter ";
CM_ SG_ 523 ESP_RollingCounter_206 "rollingcounter ";
CM_ SG_ 523 ESP_MasCylBrakePressureValid "258 ";
CM_ SG_ 523 ESP_MasCylBrakePressure "indicatedthepressureofbrakemastercylinder,butnotthepressureofbrake ";
CM_ SG_ 523 ESP_CRCCheck_277 " ";
CM_ SG_ 523 ESP_CRCCheck_258 "258 ";
CM_ SG_ 523 ESP_CRCCheck_208 " ";
CM_ SG_ 523 ESP_CRCCheck_206 " ";
CM_ BO_ 734 " ";
CM_ SG_ 734 IP_DISFail "GW报文转发 ";
CM_ SG_ 734 IP_QDashACCFail "GW报文转发 ";
CM_ BO_ 947 " ";
CM_ BO_ 1023 " ";
CM_ BO_ 1882 "CANFD诊断仪使用（DLC长度为8到64） ";
CM_ BO_ 632 " ";
CM_ BO_ 384 " ";
CM_ BO_ 424 " ";
CM_ SG_ 424 TCU_FastOnMode "DCT专用 ";
CM_ SG_ 424 TCU_VehicleSpeed "AT/DCT
ACM接收为AT专用 ";
CM_ SG_ 424 TCU_ActualGear "AT/DCT ";
CM_ SG_ 424 TCU_ActualGearValid "AT/DCT ";
CM_ SG_ 424 TCU_GearShiftPosition "AT/DCT
ACM接收为AT专用 ";
CM_ SG_ 424 TCU_ShiftPostionValid "AT/DCT
ACM接收为AT专用 ";
CM_ SG_ 424 TCU_TransFailureStatus "AT/DCT ";
CM_ SG_ 424 TCU_CRCCheck_1A8 "ACM接收为AT专用 ";
CM_ SG_ 424 TCU_RollingCounter_1A8 "AT/DCT
ACM接收为AT专用
rollingcounter ";
CM_ BO_ 784 " ";
CM_ BO_ 790 " ";
CM_ SG_ 790 LAS_Line_04_MeasureType_FT "IACC配置车型无此信号 ";
CM_ SG_ 790 LAS_Line_03_MeasureType_FT "IACC配置车型无此信号 ";
CM_ SG_ 790 LAS_Line_02_MeasureType_FT "IACC配置车型无此信号 ";
CM_ SG_ 790 LAS_Line_01_MeasureType_FT "IACC配置车型无此信号 ";
CM_ SG_ 790 LAS_Line_03_curvature_alte_FT "IACC配置车型无此信号 ";
CM_ SG_ 790 LAS_Line_03_curve_FT "IACC配置车型无此信号 ";
CM_ SG_ 790 LAS_Line_02_curvature_alte_FT "IACC配置车型无此信号 ";
CM_ SG_ 790 LAS_Line_02_curve_FT "IACC配置车型无此信号 ";
CM_ SG_ 790 LAS_Line_01_curvature_alte_FT "IACC配置车型无此信号 ";
CM_ SG_ 790 LAS_Line_01_curve_FT "IACC配置车型无此信号 ";
CM_ SG_ 790 LAS_RollingCounter_316 "IACC配置车型无此信号 ";
CM_ SG_ 790 LAS_CRCCheck_316 "IACC配置车型无此信号 ";
CM_ SG_ 790 LAS_Line_03_MeasureType "IACC配置车型无此信号 ";
CM_ SG_ 790 LAS_Line_03_curvature_alteration "IACC配置车型无此信号 ";
CM_ SG_ 790 LAS_Line_03__curve "IACC配置车型无此信号 ";
CM_ SG_ 790 LAS_Line_03_HeadingAngle "IACC配置车型无此信号 ";
CM_ SG_ 790 LAS_Line_03_dy "IACC配置车型无此信号 ";
CM_ SG_ 790 LAS_Line_03_dx_End_std "IACC配置车型无此信号 ";
CM_ SG_ 790 LAS_Line_03__dx_End "IACC配置车型无此信号 ";
CM_ SG_ 790 LAS_Line_03_dx_Start_std "IACC配置车型无此信号 ";
CM_ SG_ 790 LAS_Line_03_dx_Start "IACC配置车型无此信号 ";
CM_ SG_ 790 LAS_Line_03_Width "IACC配置车型无此信号 ";
CM_ SG_ 790 LAS_Line_03_color "IACC配置车型无此信号 ";
CM_ SG_ 790 LAS_Line_03_Id "IACC配置车型无此信号 ";
CM_ SG_ 790 LAS_Line_03_TypeConfidence "IACC配置车型无此信号 ";
CM_ SG_ 790 LAS_Line_03_Type "IACC配置车型无此信号 ";
CM_ SG_ 790 LAS_Line_02__exist_prob "IACC配置车型无此信号 ";
CM_ SG_ 790 LAS_Line_02_MeasureType "IACC配置车型无此信号 ";
CM_ SG_ 790 LAS_Line_02_curvature_alteration "IACC配置车型无此信号 ";
CM_ SG_ 790 LAS_Line_02__curve "IACC配置车型无此信号 ";
CM_ SG_ 790 LAS_Line_02_HeadingAngle "IACC配置车型无此信号 ";
CM_ SG_ 790 LAS_Line_02_dy "IACC配置车型无此信号 ";
CM_ SG_ 790 LAS_Line_02_dx_End_std "IACC配置车型无此信号 ";
CM_ SG_ 790 LAS_Line_02__dx_End "IACC配置车型无此信号 ";
CM_ SG_ 790 LAS_Line_02_dx_Start_std "IACC配置车型无此信号 ";
CM_ SG_ 790 LAS_Line_02_dx_Start "IACC配置车型无此信号 ";
CM_ SG_ 790 LAS_Line_02_Width "IACC配置车型无此信号 ";
CM_ SG_ 790 LAS_Line_02_color "IACC配置车型无此信号 ";
CM_ SG_ 790 LAS_Line_02_Id "IACC配置车型无此信号 ";
CM_ SG_ 790 LAS_Line_02_TypeConfidence "IACC配置车型无此信号 ";
CM_ SG_ 790 LAS_Line_02_Type "IACC配置车型无此信号 ";
CM_ SG_ 790 LAS_Line_01__exist_prob "IACC配置车型无此信号 ";
CM_ SG_ 790 LAS_Line_01_MeasureType "IACC配置车型无此信号 ";
CM_ SG_ 790 LAS_Line_01_curvature_alteration "IACC配置车型无此信号 ";
CM_ SG_ 790 LAS_Line_01__curve "IACC配置车型无此信号 ";
CM_ SG_ 790 LAS_Line_01_HeadingAngle "IACC配置车型无此信号 ";
CM_ SG_ 790 LAS_Line_01_dy "IACC配置车型无此信号 ";
CM_ SG_ 790 LAS_Line_01_dx_End_std "IACC配置车型无此信号 ";
CM_ SG_ 790 LAS_Line_01__dx_End "IACC配置车型无此信号 ";
CM_ SG_ 790 LAS_Line_01_dx_Start_std "IACC配置车型无此信号 ";
CM_ SG_ 790 LAS_Line_01_dx_Start "IACC配置车型无此信号 ";
CM_ SG_ 790 LAS_Line_01_Width "IACC配置车型无此信号 ";
CM_ SG_ 790 LAS_Line_01_color "IACC配置车型无此信号 ";
CM_ SG_ 790 LAS_Line_01_Id "IACC配置车型无此信号 ";
CM_ SG_ 790 LAS_Line_01_TypeConfidence "IACC配置车型无此信号 ";
CM_ SG_ 790 LAS_Line_01_Type "IACC配置车型无此信号 ";
CM_ BO_ 800 " ";
CM_ SG_ 800 GW_ResetReq " ";
CM_ BO_ 822 " ";
CM_ SG_ 822 LAS_Line_06_MeasureType_FT "IACC配置车型无此信号 ";
CM_ SG_ 822 LAS_Line_06_curve_FT "IACC配置车型无此信号 ";
CM_ SG_ 822 LAS_Line_05_MeasureType_FT "IACC配置车型无此信号 ";
CM_ SG_ 822 LAS_Line_05_curve_FT "IACC配置车型无此信号 ";
CM_ SG_ 822 LAS_Line_04_curvature_alte_FT "IACC配置车型无此信号 ";
CM_ SG_ 822 LAS_Line_04_curve_FT "IACC配置车型无此信号 ";
CM_ SG_ 822 LAS_RollingCounter_336 "IACC配置车型无此信号 ";
CM_ SG_ 822 LAS_CRCCheck_336 "IACC配置车型无此信号 ";
CM_ SG_ 822 LAS_Line_06__exist_prob "IACC配置车型无此信号 ";
CM_ SG_ 822 LAS_Line_06_MeasureType "IACC配置车型无此信号 ";
CM_ SG_ 822 LAS_Line_06_curvature_alteration "IACC配置车型无此信号 ";
CM_ SG_ 822 LAS_Line_06__curve "IACC配置车型无此信号 ";
CM_ SG_ 822 LAS_Line_06_HeadingAngle "IACC配置车型无此信号 ";
CM_ SG_ 822 LAS_Line_06_dy "IACC配置车型无此信号 ";
CM_ SG_ 822 LAS_Line_06_dx_End_std "IACC配置车型无此信号 ";
CM_ SG_ 822 LAS_Line_06__dx_End "IACC配置车型无此信号 ";
CM_ SG_ 822 LAS_Line_06_dx_Start_std "IACC配置车型无此信号 ";
CM_ SG_ 822 LAS_Line_06_dx_Start "IACC配置车型无此信号 ";
CM_ SG_ 822 LAS_Line_06_Width "IACC配置车型无此信号 ";
CM_ SG_ 822 LAS_Line_06_color "IACC配置车型无此信号 ";
CM_ SG_ 822 LAS_Line_06_Id "IACC配置车型无此信号 ";
CM_ SG_ 822 LAS_Line_06_TypeConfidence "IACC配置车型无此信号 ";
CM_ SG_ 822 LAS_Line_06_Type "IACC配置车型无此信号 ";
CM_ SG_ 822 LAS_Line_05__exist_prob "IACC配置车型无此信号 ";
CM_ SG_ 822 LAS_Line_05_MeasureType "IACC配置车型无此信号 ";
CM_ SG_ 822 LAS_Line_05_curvature_alteration "IACC配置车型无此信号 ";
CM_ SG_ 822 LAS_Line_05__curve "IACC配置车型无此信号 ";
CM_ SG_ 822 LAS_Line_05_HeadingAngle "IACC配置车型无此信号 ";
CM_ SG_ 822 LAS_Line_05_dy "IACC配置车型无此信号 ";
CM_ SG_ 822 LAS_Line_05_dx_End_std "IACC配置车型无此信号 ";
CM_ SG_ 822 LAS_Line_05__dx_End "IACC配置车型无此信号 ";
CM_ SG_ 822 LAS_Line_05_dx_Start_std "IACC配置车型无此信号 ";
CM_ SG_ 822 LAS_Line_05_dx_Start "IACC配置车型无此信号 ";
CM_ SG_ 822 LAS_Line_05_Width "IACC配置车型无此信号 ";
CM_ SG_ 822 LAS_Line_05_color "IACC配置车型无此信号 ";
CM_ SG_ 822 LAS_Line_05_Id "IACC配置车型无此信号 ";
CM_ SG_ 822 LAS_Line_05_TypeConfidence "IACC配置车型无此信号 ";
CM_ SG_ 822 LAS_Line_05_Type "IACC配置车型无此信号 ";
CM_ SG_ 822 LAS_Line_04__exist_prob "IACC配置车型无此信号 ";
CM_ SG_ 822 LAS_Line_04_MeasureType "IACC配置车型无此信号 ";
CM_ SG_ 822 LAS_Line_04_curvature_alteration "IACC配置车型无此信号 ";
CM_ SG_ 822 LAS_Line_04__curve "IACC配置车型无此信号 ";
CM_ SG_ 822 LAS_Line_04_HeadingAngle "IACC配置车型无此信号 ";
CM_ SG_ 822 LAS_Line_04_dy "IACC配置车型无此信号 ";
CM_ SG_ 822 LAS_Line_04_dx_End_std "IACC配置车型无此信号 ";
CM_ SG_ 822 LAS_Line_04__dx_End "IACC配置车型无此信号 ";
CM_ SG_ 822 LAS_Line_04_dx_Start_std "IACC配置车型无此信号 ";
CM_ SG_ 822 LAS_Line_04_dx_Start "IACC配置车型无此信号 ";
CM_ SG_ 822 LAS_Line_04_Width "IACC配置车型无此信号 ";
CM_ SG_ 822 LAS_Line_04_color "IACC配置车型无此信号 ";
CM_ SG_ 822 LAS_Line_04_Id "IACC配置车型无此信号 ";
CM_ SG_ 822 LAS_Line_04_TypeConfidence "IACC配置车型无此信号 ";
CM_ SG_ 822 LAS_Line_04_Type "IACC配置车型无此信号 ";
CM_ SG_ 822 LAS_Line_03__exist_prob "IACC配置车型无此信号 ";
CM_ BO_ 683 " ";
CM_ SG_ 683 FC_RollingCounter_28D "IACC配置车型无此信号 ";
CM_ SG_ 683 FC_CRCCheck_28D "IACC配置车型无此信号 ";
CM_ SG_ 683 FC_AEBOBJ_Track_Age "IACC配置车型无此信号 ";
CM_ SG_ 683 FC_AEBOBJ_Track_ID "IACC配置车型无此信号 ";
CM_ SG_ 683 FC_AEBOBJ_FusionedFC_Track_ID "IACC配置车型无此信号 ";
CM_ SG_ 683 FC_AEBOBJ_fusion_Sts "IACC配置车型无此信号 ";
CM_ SG_ 683 FC_AEBOBJ_ObstacleProb "IACC配置车型无此信号 ";
CM_ SG_ 683 FC_AEBOBJ_ExistProb "IACC配置车型无此信号 ";
CM_ SG_ 683 FC_AEBOBJ_Brakelight_Info "IACC配置车型无此信号 ";
CM_ SG_ 683 FC_AEBOBJ_Taillight_Info "IACC配置车型无此信号 ";
CM_ SG_ 683 FC_AEBOBJ_Dis_to_R_LaneMark "IACC配置车型无此信号 ";
CM_ SG_ 683 FC_AEBOBJ_Dis_to_L_LaneMark "IACC配置车型无此信号 ";
CM_ SG_ 683 FC_AEBOBJ_Ax "IACC配置车型无此信号 ";
CM_ SG_ 683 FC_AEBOBJ_Ay "IACC配置车型无此信号 ";
CM_ SG_ 683 FC_AEBOBJ_Vx_std "IACC配置车型无此信号 ";
CM_ SG_ 683 FC_AEBOBJ_Vx "IACC配置车型无此信号 ";
CM_ SG_ 683 FC_AEBOBJ_Vy_std "IACC配置车型无此信号 ";
CM_ SG_ 683 FC_AEBOBJ_Vy "IACC配置车型无此信号 ";
CM_ SG_ 683 FC_AEBOBJ_Dx_Vnce "IACC配置车型无此信号 ";
CM_ SG_ 683 FC_AEBOBJ_Dx "IACC配置车型无此信号 ";
CM_ SG_ 683 FC_AEBOBJ_Dy_Vnce "IACC配置车型无此信号 ";
CM_ SG_ 683 FC_AEBOBJ_Dy "IACC配置车型无此信号 ";
CM_ SG_ 683 FC_AEBOBJ_HeadingAngle "IACC配置车型无此信号 ";
CM_ SG_ 683 FC_AEBOBJ_Length "IACC配置车型无此信号 ";
CM_ SG_ 683 FC_AEBOBJ_Height "IACC配置车型无此信号 ";
CM_ SG_ 683 FC_AEBOBJ_Width "IACC配置车型无此信号 ";
CM_ SG_ 683 FC_AEBOBJ_Class "IACC配置车型无此信号 ";
CM_ BO_ 711 " ";
CM_ SG_ 711 FRC_TiOut " ";
CM_ SG_ 711 FRC_TiLeap " ";
CM_ SG_ 711 FRC_TiBas " ";
CM_ SG_ 711 FRC_TiStamp " ";
CM_ SG_ 711 FRC_FCTAEnable " ";
CM_ SG_ 711 FRC_ObjDelay " ";
CM_ SG_ 711 FRC_SystemStatus " ";
CM_ SG_ 711 FRC_FCTBActive " ";
CM_ SG_ 711 FRC_FCTBTargetDeceleration " ";
CM_ SG_ 711 FRC_FCTBEnable " ";
CM_ BO_ 747 " ";
CM_ SG_ 747 FC_RollingCounter_28F "IACC配置车型无此信号 ";
CM_ SG_ 747 FC_CRCCheck_28F "IACC配置车型无此信号 ";
CM_ SG_ 747 FC_FrFrOBJ_Track_Age "IACC配置车型无此信号 ";
CM_ SG_ 747 FC_FrFrOBJ_Track_ID "IACC配置车型无此信号 ";
CM_ SG_ 747 FC_FrFrOBJ_FusionedFC_Track_ID "IACC配置车型无此信号 ";
CM_ SG_ 747 FC_FrFrOBJ_fusion_Sts "IACC配置车型无此信号 ";
CM_ SG_ 747 FC_FrFrOBJ_ObstacleProb "IACC配置车型无此信号 ";
CM_ SG_ 747 FC_FrFrOBJ_ExistProb "IACC配置车型无此信号 ";
CM_ SG_ 747 FC_FrFrOBJ_Brakelight_Info "IACC配置车型无此信号 ";
CM_ SG_ 747 FC_FrFrOBJ_Taillight_Info "IACC配置车型无此信号 ";
CM_ SG_ 747 FC_FrFrOBJ_Dis_to_R_LaneMark "IACC配置车型无此信号 ";
CM_ SG_ 747 FC_FrFrOBJ_Dis_to_L_LaneMark "IACC配置车型无此信号 ";
CM_ SG_ 747 FC_FrFrOBJ_Ax "IACC配置车型无此信号 ";
CM_ SG_ 747 FC_FrFrOBJ_Ay "IACC配置车型无此信号 ";
CM_ SG_ 747 FC_FrFrOBJ_Vx_std "IACC配置车型无此信号 ";
CM_ SG_ 747 FC_FrFrOBJ_Vx "IACC配置车型无此信号 ";
CM_ SG_ 747 FC_FrFrOBJ_Vy_std "IACC配置车型无此信号 ";
CM_ SG_ 747 FC_FrFrOBJ_Vy "IACC配置车型无此信号 ";
CM_ SG_ 747 FC_FrFrOBJ_Dx_Vnce "IACC配置车型无此信号 ";
CM_ SG_ 747 FC_FrFrOBJ_Dx "IACC配置车型无此信号 ";
CM_ SG_ 747 FC_FrFrOBJ_Dy_Vnce "IACC配置车型无此信号 ";
CM_ SG_ 747 FC_FrFrOBJ_Dy "IACC配置车型无此信号 ";
CM_ SG_ 747 FC_FrFrOBJ_HeadingAngle "IACC配置车型无此信号 ";
CM_ SG_ 747 FC_FrFrOBJ_Length "IACC配置车型无此信号 ";
CM_ SG_ 747 FC_FrFrOBJ_Height "IACC配置车型无此信号 ";
CM_ SG_ 747 FC_FrFrOBJ_Width "IACC配置车型无此信号 ";
CM_ SG_ 747 FC_FrFrOBJ_Class "IACC配置车型无此信号 ";
CM_ SG_ 747 FC_FrOBJ_Track_Age "IACC配置车型无此信号 ";
CM_ SG_ 747 FC_FrOBJ_Track_ID "IACC配置车型无此信号 ";
CM_ SG_ 747 FC_FrOBJ_FusionedFC_Track_ID "IACC配置车型无此信号 ";
CM_ SG_ 747 FC_FrOBJ_fusion_Sts "IACC配置车型无此信号 ";
CM_ SG_ 747 FC_FrOBJ_ObstacleProb "IACC配置车型无此信号 ";
CM_ SG_ 747 FC_FrOBJ_ExistProb "IACC配置车型无此信号 ";
CM_ SG_ 747 FC_FrOBJ_Brakelight_Info "IACC配置车型无此信号 ";
CM_ SG_ 747 FC_FrOBJ_Taillight_Info "IACC配置车型无此信号 ";
CM_ SG_ 747 FC_FrOBJ_Dis_to_R_LaneMark "IACC配置车型无此信号 ";
CM_ SG_ 747 FC_FrOBJ_Dis_to_L_LaneMark "IACC配置车型无此信号 ";
CM_ SG_ 747 FC_FrOBJ_Ax "IACC配置车型无此信号 ";
CM_ SG_ 747 FC_FrOBJ_Ay "IACC配置车型无此信号 ";
CM_ SG_ 747 FC_FrOBJ_Vx_std "IACC配置车型无此信号 ";
CM_ SG_ 747 FC_FrOBJ_Vx "IACC配置车型无此信号 ";
CM_ SG_ 747 FC_FrOBJ_Vy_std "IACC配置车型无此信号 ";
CM_ SG_ 747 FC_FrOBJ_Vy "IACC配置车型无此信号 ";
CM_ SG_ 747 FC_FrOBJ_Dx_Vnce "IACC配置车型无此信号 ";
CM_ SG_ 747 FC_FrOBJ_Dx "IACC配置车型无此信号 ";
CM_ SG_ 747 FC_FrOBJ_Dy_Vnce "IACC配置车型无此信号 ";
CM_ SG_ 747 FC_FrOBJ_Dy "IACC配置车型无此信号 ";
CM_ SG_ 747 FC_FrOBJ_HeadingAngle "IACC配置车型无此信号 ";
CM_ SG_ 747 FC_FrOBJ_Length "IACC配置车型无此信号 ";
CM_ SG_ 747 FC_FrOBJ_Height "IACC配置车型无此信号 ";
CM_ SG_ 747 FC_FrOBJ_Width "IACC配置车型无此信号 ";
CM_ SG_ 747 FC_FrOBJ_Class "IACC配置车型无此信号 ";
CM_ BO_ 750 " ";
CM_ SG_ 750 FC_RollingCounter_29C "IACC配置车型无此信号 ";
CM_ SG_ 750 FC_CRCCheck_29C "IACC配置车型无此信号 ";
CM_ SG_ 750 FC_LeFrOBJ_Track_Age "IACC配置车型无此信号 ";
CM_ SG_ 750 FC_LeFrOBJ_Track_ID "IACC配置车型无此信号 ";
CM_ SG_ 750 FC_LeFrOBJ_FusionedFC_Track_ID "IACC配置车型无此信号 ";
CM_ SG_ 750 FC_LeFrOBJ_fusion_Sts "IACC配置车型无此信号 ";
CM_ SG_ 750 FC_LeFrOBJ_ObstacleProb "IACC配置车型无此信号 ";
CM_ SG_ 750 FC_LeFrOBJ_ExistProb "IACC配置车型无此信号 ";
CM_ SG_ 750 FC_LeFrOBJ_Brakelight_Info "IACC配置车型无此信号 ";
CM_ SG_ 750 FC_LeFrOBJ_Taillight_Info "IACC配置车型无此信号 ";
CM_ SG_ 750 FC_LeFrOBJ_Dis_to_R_LaneMark "IACC配置车型无此信号 ";
CM_ SG_ 750 FC_LeFrOBJ_Dis_to_L_LaneMark "IACC配置车型无此信号 ";
CM_ SG_ 750 FC_LeFrOBJ_Ax "IACC配置车型无此信号 ";
CM_ SG_ 750 FC_LeFrOBJ_Ay "IACC配置车型无此信号 ";
CM_ SG_ 750 FC_LeFrOBJ_Vx_std "IACC配置车型无此信号 ";
CM_ SG_ 750 FC_LeFrOBJ_Vx "IACC配置车型无此信号 ";
CM_ SG_ 750 FC_LeFrOBJ_Vy_std "IACC配置车型无此信号 ";
CM_ SG_ 750 FC_LeFrOBJ_Vy "IACC配置车型无此信号 ";
CM_ SG_ 750 FC_LeFrOBJ_Dx_Vnce "IACC配置车型无此信号 ";
CM_ SG_ 750 FC_LeFrOBJ_Dx "IACC配置车型无此信号 ";
CM_ SG_ 750 FC_LeFrOBJ_Dy_Vnce "IACC配置车型无此信号 ";
CM_ SG_ 750 FC_LeFrOBJ_Dy "IACC配置车型无此信号 ";
CM_ SG_ 750 FC_LeFrOBJ_HeadingAngle "IACC配置车型无此信号 ";
CM_ SG_ 750 FC_LeFrOBJ_Length "IACC配置车型无此信号 ";
CM_ SG_ 750 FC_LeFrOBJ_Height "IACC配置车型无此信号 ";
CM_ SG_ 750 FC_LeFrOBJ_Width "IACC配置车型无此信号 ";
CM_ SG_ 750 FC_LeFrOBJ_Class "IACC配置车型无此信号 ";
CM_ SG_ 750 FC_LeOBJ_Track_Age "IACC配置车型无此信号 ";
CM_ SG_ 750 FC_LeOBJ_Track_ID "IACC配置车型无此信号 ";
CM_ SG_ 750 FC_LeOBJ_FusionedFC_Track_ID "IACC配置车型无此信号 ";
CM_ SG_ 750 FC_LeOBJ_fusion_Sts "IACC配置车型无此信号 ";
CM_ SG_ 750 FC_LeOBJ_ObstacleProb "IACC配置车型无此信号 ";
CM_ SG_ 750 FC_LeOBJ_ExistProb "IACC配置车型无此信号 ";
CM_ SG_ 750 FC_LeOBJ_Brakelight_Info "IACC配置车型无此信号 ";
CM_ SG_ 750 FC_LeOBJ_Taillight_Info "IACC配置车型无此信号 ";
CM_ SG_ 750 FC_LeOBJ_Dis_to_R_LaneMark "IACC配置车型无此信号 ";
CM_ SG_ 750 FC_LeOBJ_Dis_to_L_LaneMark "IACC配置车型无此信号 ";
CM_ SG_ 750 FC_LeOBJ_Ax "IACC配置车型无此信号 ";
CM_ SG_ 750 FC_LeOBJ_Ay "IACC配置车型无此信号 ";
CM_ SG_ 750 FC_LeOBJ_Vx_std "IACC配置车型无此信号 ";
CM_ SG_ 750 FC_LeOBJ_Vx "IACC配置车型无此信号 ";
CM_ SG_ 750 FC_LeOBJ_Vy_std "IACC配置车型无此信号 ";
CM_ SG_ 750 FC_LeOBJ_Vy "IACC配置车型无此信号 ";
CM_ SG_ 750 FC_LeOBJ_Dx_Vnce "IACC配置车型无此信号 ";
CM_ SG_ 750 FC_LeOBJ_Dx "IACC配置车型无此信号 ";
CM_ SG_ 750 FC_LeOBJ_Dy_Vnce "IACC配置车型无此信号 ";
CM_ SG_ 750 FC_LeOBJ_Dy "IACC配置车型无此信号 ";
CM_ SG_ 750 FC_LeOBJ_HeadingAngle "IACC配置车型无此信号 ";
CM_ SG_ 750 FC_LeOBJ_Length "IACC配置车型无此信号 ";
CM_ SG_ 750 FC_LeOBJ_Height "IACC配置车型无此信号 ";
CM_ SG_ 750 FC_LeOBJ_Width "IACC配置车型无此信号 ";
CM_ SG_ 750 FC_LeOBJ_Class "IACC配置车型无此信号 ";
CM_ BO_ 756 " ";
CM_ SG_ 756 FC_RollingCounter_29D "IACC配置车型无此信号 ";
CM_ SG_ 756 FC_CRCCheck_29D "IACC配置车型无此信号 ";
CM_ SG_ 756 FC_RiFrOBJ_Track_Age "IACC配置车型无此信号 ";
CM_ SG_ 756 FC_RiFrOBJ_Track_ID "IACC配置车型无此信号 ";
CM_ SG_ 756 FC_RiFrOBJ_FusionedFC_Track_ID "IACC配置车型无此信号 ";
CM_ SG_ 756 FC_RiFrOBJ_fusion_Sts "IACC配置车型无此信号 ";
CM_ SG_ 756 FC_RiFrOBJ_ObstacleProb "IACC配置车型无此信号 ";
CM_ SG_ 756 FC_RiFrOBJ_ExistProb "IACC配置车型无此信号 ";
CM_ SG_ 756 FC_RiFrOBJ_Brakelight_Info "IACC配置车型无此信号 ";
CM_ SG_ 756 FC_RiFrOBJ_Taillight_Info "IACC配置车型无此信号 ";
CM_ SG_ 756 FC_RiFrOBJ_Dis_to_R_LaneMark "IACC配置车型无此信号 ";
CM_ SG_ 756 FC_RiFrOBJ_Dis_to_L_LaneMark "IACC配置车型无此信号 ";
CM_ SG_ 756 FC_RiFrOBJ_Ax "IACC配置车型无此信号 ";
CM_ SG_ 756 FC_RiFrOBJ_Ay "IACC配置车型无此信号 ";
CM_ SG_ 756 FC_RiFrOBJ_Vx_std "IACC配置车型无此信号 ";
CM_ SG_ 756 FC_RiFrOBJ_Vx "IACC配置车型无此信号 ";
CM_ SG_ 756 FC_RiFrOBJ_Vy_std "IACC配置车型无此信号 ";
CM_ SG_ 756 FC_RiFrOBJ_Vy "IACC配置车型无此信号 ";
CM_ SG_ 756 FC_RiFrOBJ_Dx_Vnce "IACC配置车型无此信号 ";
CM_ SG_ 756 FC_RiFrOBJ_Dx "IACC配置车型无此信号 ";
CM_ SG_ 756 FC_RiFrOBJ_Dy_Vnce "IACC配置车型无此信号 ";
CM_ SG_ 756 FC_RiFrOBJ_Dy "IACC配置车型无此信号 ";
CM_ SG_ 756 FC_RiFrOBJ_HeadingAngle "IACC配置车型无此信号 ";
CM_ SG_ 756 FC_RiFrOBJ_Length "IACC配置车型无此信号 ";
CM_ SG_ 756 FC_RiFrOBJ_Height "IACC配置车型无此信号 ";
CM_ SG_ 756 FC_RiFrOBJ_Width "IACC配置车型无此信号 ";
CM_ SG_ 756 FC_RiFrOBJ_Class "IACC配置车型无此信号 ";
CM_ SG_ 756 FC_RiOBJ_Track_Age "IACC配置车型无此信号 ";
CM_ SG_ 756 FC_RiOBJ_Track_ID "IACC配置车型无此信号 ";
CM_ SG_ 756 FC_RiOBJ_FusionedFC_Track_ID "IACC配置车型无此信号 ";
CM_ SG_ 756 FC_RiOBJ_fusion_Sts "IACC配置车型无此信号 ";
CM_ SG_ 756 FC_RiOBJ_ObstacleProb "IACC配置车型无此信号 ";
CM_ SG_ 756 FC_RiOBJ_ExistProb "IACC配置车型无此信号 ";
CM_ SG_ 756 FC_RiOBJ_Brakelight_Info "IACC配置车型无此信号 ";
CM_ SG_ 756 FC_RiOBJ_Taillight_Info "IACC配置车型无此信号 ";
CM_ SG_ 756 FC_RiOBJ_Dis_to_R_LaneMark "IACC配置车型无此信号 ";
CM_ SG_ 756 FC_RiOBJ_Dis_to_L_LaneMark "IACC配置车型无此信号 ";
CM_ SG_ 756 FC_RiOBJ_Ax "IACC配置车型无此信号 ";
CM_ SG_ 756 FC_RiOBJ_Ay "IACC配置车型无此信号 ";
CM_ SG_ 756 FC_RiOBJ_Vx_std "IACC配置车型无此信号 ";
CM_ SG_ 756 FC_RiOBJ_Vx "IACC配置车型无此信号 ";
CM_ SG_ 756 FC_RiOBJ_Vy_std "IACC配置车型无此信号 ";
CM_ SG_ 756 FC_RiOBJ_Vy "IACC配置车型无此信号 ";
CM_ SG_ 756 FC_RiOBJ_Dx_Vnce "IACC配置车型无此信号 ";
CM_ SG_ 756 FC_RiOBJ_Dx "IACC配置车型无此信号 ";
CM_ SG_ 756 FC_RiOBJ_Dy_Vnce "IACC配置车型无此信号 ";
CM_ SG_ 756 FC_RiOBJ_Dy "IACC配置车型无此信号 ";
CM_ SG_ 756 FC_RiOBJ_HeadingAngle "IACC配置车型无此信号 ";
CM_ SG_ 756 FC_RiOBJ_Length "IACC配置车型无此信号 ";
CM_ SG_ 756 FC_RiOBJ_Height "IACC配置车型无此信号 ";
CM_ SG_ 756 FC_RiOBJ_Width "IACC配置车型无此信号 ";
CM_ SG_ 756 FC_RiOBJ_Class "IACC配置车型无此信号 ";
CM_ BO_ 831 " ";
CM_ SG_ 831 LAS_RollingCounter_33F "IACC配置车型无此信号 ";
CM_ SG_ 831 LAS_CRCCheck_33F "IACC配置车型无此信号 ";
CM_ SG_ 831 LAS_Line_06_curvature_alte_FT "IACC配置车型无此信号 ";
CM_ SG_ 831 LAS_Line_05_curvature_alte_FT "IACC配置车型无此信号 ";
CM_ BO_ 906 " ";
CM_ BO_ 1000 " ";
CM_ SG_ 1000 BCM_SOF_Q_STATE "GW报文转发 ";
CM_ SG_ 1000 BCM_SOF_Q "GW报文转发 ";
CM_ BO_ 1684 " ";
CM_ SG_ 1684 LAS_DTC2_Status "DTC上传 ";
CM_ SG_ 1684 LAS_DTC2_LowByte "DTC上传 ";
CM_ SG_ 1684 LAS_DTC2_MiddByte "DTC上传 ";
CM_ SG_ 1684 LAS_DTC2_HighByte "DTC上传 ";
CM_ SG_ 1684 LAS_DTC1_Status "DTC上传 ";
CM_ SG_ 1684 LAS_DTC1_LowByte "DTC上传 ";
CM_ SG_ 1684 LAS_DTC1_MiddByte "DTC上传 ";
CM_ SG_ 1684 LAS_DTC1_HighByte "DTC上传 ";
CM_ BO_ 723 " ";
CM_ SG_ 723 ACC_CRCCheck_283 " ";
CM_ SG_ 723 ACC_RollingCounter_283 " ";
CM_ SG_ 723 ACC_AEBTargetLatRelSpeed_for_SRS "向左为正，向右为负 ";
CM_ SG_ 723 ACC_AEBTargetLatRange_for_SRS "向左为正，向右为负 ";
CM_ SG_ 723 ACC_CRCCheckr_282 " ";
CM_ SG_ 723 ACC_RollingCounter_282 " ";
CM_ SG_ 723 ACC_AEBTargetProb_for_SRS " ";
CM_ SG_ 723 ACC_AEBTargetTTC_for_SRS "碰撞时刻为0 ";
CM_ SG_ 723 ACC_AEBTargetRelSpeed_for_SRS "前方目标比本车快为正，前方目标比本车慢为负 ";
CM_ SG_ 723 ACC_AEBTargetLngRange_for_SRS "负数代表向后，正数代表向前，原点为前雷达波束发射面 ";
CM_ SG_ 723 ACC_AEBStatus_for_SRS " ";
CM_ BO_ 780 " ";
CM_ BO_ 738 " ";
CM_ BO_ 739 " ";
CM_ BO_ 1304 " ";
CM_ SG_ 1304 BCM_CarMode "无效值是为转DBC ";
CM_ BO_ 686 " ";
CM_ SG_ 686 LCDAL_SystemStatus " ";
CM_ BO_ 985 " ";
CM_ SG_ 985 ACC_ObsTarget10ID " ";
CM_ SG_ 985 ACC_ObsTarget10Type " ";
CM_ SG_ 985 ACC_ObsTarget10LatRange "横向距离向左为负，向右为正 ";
CM_ SG_ 985 ACC_ObsTarget10LngRange "纵向距离向前为正，向后为负
 ";
CM_ SG_ 985 ACC_ObsTarget9ID " ";
CM_ SG_ 985 ACC_ObsTarget9Type " ";
CM_ SG_ 985 ACC_ObsTarget9LatRange "横向距离向左为负，向右为正 ";
CM_ SG_ 985 ACC_ObsTarget9LngRange "纵向距离向前为正，向后为负
 ";
CM_ SG_ 985 ACC_ObsTarget8ID " ";
CM_ SG_ 985 ACC_ObsTarget8Type " ";
CM_ SG_ 985 ACC_ObsTarget8LatRange "横向距离向左为负，向右为正 ";
CM_ SG_ 985 ACC_ObsTarget8LngRange "纵向距离向前为正，向后为负
 ";
CM_ SG_ 985 ACC_ObsTarget7ID " ";
CM_ SG_ 985 ACC_ObsTarget7Type " ";
CM_ SG_ 985 ACC_ObsTarget7LatRange "横向距离向左为负，向右为正 ";
CM_ SG_ 985 ACC_ObsTarget7LngRange "纵向距离向前为正，向后为负
 ";
CM_ SG_ 985 ACC_ObsTarget6ID " ";
CM_ SG_ 985 ACC_ObsTarget6Type " ";
CM_ SG_ 985 ACC_ObsTarget6LatRange "横向距离向左为负，向右为正 ";
CM_ SG_ 985 ACC_ObsTarget6LngRange "纵向距离向前为正，向后为负
 ";
CM_ SG_ 985 ACC_ObsTarget5ID " ";
CM_ SG_ 985 ACC_ObsTarget5Type " ";
CM_ SG_ 985 ACC_ObsTarget5LatRange "横向距离向左为负，向右为正 ";
CM_ SG_ 985 ACC_ObsTarget5LngRange "纵向距离向前为正，向后为负
 ";
CM_ SG_ 985 ACC_ObsTarget4ID " ";
CM_ SG_ 985 ACC_ObsTarget4Type " ";
CM_ SG_ 985 ACC_ObsTarget4LatRange "横向距离向左为负，向右为正 ";
CM_ SG_ 985 ACC_ObsTarget4LngRange "纵向距离向前为正，向后为负
 ";
CM_ SG_ 985 ACC_ObsTarget3ID " ";
CM_ SG_ 985 ACC_ObsTarget3Type " ";
CM_ SG_ 985 ACC_ObsTarget3LatRange "横向距离向左为负，向右为正 ";
CM_ SG_ 985 ACC_ObsTarget3LngRange "纵向距离向前为正，向后为负
 ";
CM_ SG_ 985 ACC_ObsTarget2ID " ";
CM_ SG_ 985 ACC_ObsTarget2Type " ";
CM_ SG_ 985 ACC_ObsTarget2LatRange "横向距离向左为负，向右为正 ";
CM_ SG_ 985 ACC_ObsTarget2LngRange "纵向距离向前为正，向后为负
 ";
CM_ SG_ 985 ACC_ObsTarget1ID " ";
CM_ SG_ 985 ACC_ObsTarget1Type " ";
CM_ SG_ 985 ACC_ObsTarget1LatRange "横向距离向左为负，向右为正 ";
CM_ SG_ 985 ACC_ObsTarget1LngRange "纵向距离向前为正，向后为负
 ";
CM_ BO_ 987 " ";
CM_ SG_ 987 ACC_ObsTarget20ID " ";
CM_ SG_ 987 ACC_ObsTarget20Type " ";
CM_ SG_ 987 ACC_ObsTarget20LatRange "横向距离向左为负，向右为正 ";
CM_ SG_ 987 ACC_ObsTarget20LngRange "纵向距离向前为正，向后为负
 ";
CM_ SG_ 987 ACC_ObsTarget19ID " ";
CM_ SG_ 987 ACC_ObsTarget19Type " ";
CM_ SG_ 987 ACC_ObsTarget19LatRange "横向距离向左为负，向右为正 ";
CM_ SG_ 987 ACC_ObsTarget19LngRange "纵向距离向前为正，向后为负
 ";
CM_ SG_ 987 ACC_ObsTarget18ID " ";
CM_ SG_ 987 ACC_ObsTarget18Type " ";
CM_ SG_ 987 ACC_ObsTarget18LatRange "横向距离向左为负，向右为正 ";
CM_ SG_ 987 ACC_ObsTarget18LngRange "纵向距离向前为正，向后为负
 ";
CM_ SG_ 987 ACC_ObsTarget17ID " ";
CM_ SG_ 987 ACC_ObsTarget17Type " ";
CM_ SG_ 987 ACC_ObsTarget17LatRange "横向距离向左为负，向右为正 ";
CM_ SG_ 987 ACC_ObsTarget17LngRange "纵向距离向前为正，向后为负
 ";
CM_ SG_ 987 ACC_ObsTarget16ID " ";
CM_ SG_ 987 ACC_ObsTarget16Type " ";
CM_ SG_ 987 ACC_ObsTarget16LatRange "横向距离向左为负，向右为正 ";
CM_ SG_ 987 ACC_ObsTarget16LngRange "纵向距离向前为正，向后为负
 ";
CM_ SG_ 987 ACC_ObsTarget15ID " ";
CM_ SG_ 987 ACC_ObsTarget15Type " ";
CM_ SG_ 987 ACC_ObsTarget15LatRange "横向距离向左为负，向右为正 ";
CM_ SG_ 987 ACC_ObsTarget15LngRange "纵向距离向前为正，向后为负
 ";
CM_ SG_ 987 ACC_ObsTarget14ID " ";
CM_ SG_ 987 ACC_ObsTarget14Type " ";
CM_ SG_ 987 ACC_ObsTarget14LatRange "横向距离向左为负，向右为正 ";
CM_ SG_ 987 ACC_ObsTarget14LngRange "纵向距离向前为正，向后为负
 ";
CM_ SG_ 987 ACC_ObsTarget13ID " ";
CM_ SG_ 987 ACC_ObsTarget13Type " ";
CM_ SG_ 987 ACC_ObsTarget13LatRange "横向距离向左为负，向右为正 ";
CM_ SG_ 987 ACC_ObsTarget13LngRange "纵向距离向前为正，向后为负
 ";
CM_ SG_ 987 ACC_ObsTarget12ID " ";
CM_ SG_ 987 ACC_ObsTarget12Type " ";
CM_ SG_ 987 ACC_ObsTarget12LatRange "横向距离向左为负，向右为正 ";
CM_ SG_ 987 ACC_ObsTarget12LngRange "纵向距离向前为正，向后为负
 ";
CM_ SG_ 987 ACC_ObsTarget11ID " ";
CM_ SG_ 987 ACC_ObsTarget11Type " ";
CM_ SG_ 987 ACC_ObsTarget11LatRange "横向距离向左为负，向右为正 ";
CM_ SG_ 987 ACC_ObsTarget11LngRange "纵向距离向前为正，向后为负
 ";
BA_DEF_ SG_  "GenSigSendType" ENUM  "Cyclic","OnWrite","OnWriteWithRepetition","OnChange","OnChangeWithRepetition","IfActive","IfActiveWithRepetition","NoSigSendType","NotUsed","NotUsed","NotUsed","NotUsed","NotUsed";
BA_DEF_ SG_  "GenSigCycleTime" INT 0 0;
BA_DEF_ SG_  "GenSigInvalidValue" STRING ;
BA_DEF_ SG_  "GenSigStartValue" INT 0 0;
BA_DEF_ BO_  "VFrameFormat" ENUM  "StandardCAN","ExtendedCAN","reserved","reserved","reserved","reserved","reserved","reserved","reserved","reserved","reserved","reserved","reserved","reserved","StandardCAN_FD","ExtendedCAN_FD";
BA_DEF_ BO_  "CANFD_BRS" ENUM  "0","1";
BA_DEF_ BO_  "GenMsgCycleTime" INT 0 65535;
BA_DEF_ BO_  "GenMsgILSupport" ENUM  "No","Yes";
BA_DEF_ BO_  "GenMsgSendType" ENUM  "Cyclic","Event","NotUsed","NotUsed","NotUsed","Cyclic","NotUsed","IfActive","NoMsgSendType","NotUsed";
BA_DEF_DEF_  "GenSigSendType" "Cyclic";
BA_DEF_DEF_  "GenSigCycleTime" 0;
BA_DEF_DEF_  "GenSigInvalidValue" "/";
BA_DEF_DEF_  "GenSigStartValue" 0;
BA_DEF_DEF_  "VFrameFormat" "StandardCAN";
BA_DEF_DEF_  "CANFD_BRS" "1";
BA_DEF_DEF_  "GenMsgCycleTime" 0;
BA_DEF_DEF_  "GenMsgILSupport" "Yes";
BA_DEF_DEF_  "GenMsgSendType" "NoMsgSendType";
BA_ "GenMsgCycleTime" BO_ 999 100;
BA_ "GenMsgSendType" BO_ 999 0;
BA_ "VFrameFormat" BO_ 999 14;
BA_ "GenMsgCycleTime" BO_ 1021 100;
BA_ "GenMsgSendType" BO_ 1021 0;
BA_ "VFrameFormat" BO_ 1021 14;
BA_ "GenMsgCycleTime" BO_ 1310 500;
BA_ "GenMsgSendType" BO_ 1310 0;
BA_ "VFrameFormat" BO_ 1310 14;
BA_ "GenMsgCycleTime" BO_ 1374 500;
BA_ "GenMsgSendType" BO_ 1374 0;
BA_ "VFrameFormat" BO_ 1374 14;
BA_ "GenMsgCycleTime" BO_ 652 40;
BA_ "GenMsgSendType" BO_ 652 0;
BA_ "VFrameFormat" BO_ 652 14;
BA_ "GenMsgCycleTime" BO_ 1426 1000;
BA_ "GenMsgSendType" BO_ 1426 0;
BA_ "VFrameFormat" BO_ 1426 14;
BA_ "GenMsgCycleTime" BO_ 1428 1000;
BA_ "GenMsgSendType" BO_ 1428 0;
BA_ "VFrameFormat" BO_ 1428 14;
BA_ "GenMsgSendType" BO_ 1106 1;
BA_ "VFrameFormat" BO_ 1106 14;
BA_ "GenMsgCycleTime" BO_ 80 500;
BA_ "GenMsgSendType" BO_ 80 0;
BA_ "VFrameFormat" BO_ 80 14;
BA_ "GenMsgCycleTime" BO_ 898 100;
BA_ "GenMsgSendType" BO_ 898 0;
BA_ "VFrameFormat" BO_ 898 14;
BA_ "GenMsgCycleTime" BO_ 1328 500;
BA_ "GenMsgSendType" BO_ 1328 0;
BA_ "VFrameFormat" BO_ 1328 14;
BA_ "GenMsgCycleTime" BO_ 391 10;
BA_ "GenMsgSendType" BO_ 391 0;
BA_ "VFrameFormat" BO_ 391 14;
BA_ "GenMsgCycleTime" BO_ 407 10;
BA_ "GenMsgSendType" BO_ 407 0;
BA_ "VFrameFormat" BO_ 407 14;
BA_ "GenMsgCycleTime" BO_ 523 20;
BA_ "GenMsgSendType" BO_ 523 0;
BA_ "VFrameFormat" BO_ 523 14;
BA_ "GenMsgCycleTime" BO_ 734 50;
BA_ "GenMsgSendType" BO_ 734 0;
BA_ "VFrameFormat" BO_ 734 14;
BA_ "GenMsgCycleTime" BO_ 947 100;
BA_ "GenMsgSendType" BO_ 947 0;
BA_ "VFrameFormat" BO_ 947 14;
BA_ "GenMsgCycleTime" BO_ 1023 100;
BA_ "GenMsgSendType" BO_ 1023 0;
BA_ "VFrameFormat" BO_ 1023 14;
BA_ "GenMsgSendType" BO_ 1882 1;
BA_ "VFrameFormat" BO_ 1882 14;
BA_ "GenMsgSendType" BO_ 1899 1;
BA_ "VFrameFormat" BO_ 1899 14;
BA_ "GenMsgCycleTime" BO_ 632 20;
BA_ "GenMsgSendType" BO_ 632 0;
BA_ "VFrameFormat" BO_ 632 14;
BA_ "GenMsgCycleTime" BO_ 384 10;
BA_ "GenMsgSendType" BO_ 384 0;
BA_ "VFrameFormat" BO_ 384 14;
BA_ "GenMsgCycleTime" BO_ 424 10;
BA_ "GenMsgSendType" BO_ 424 0;
BA_ "VFrameFormat" BO_ 424 14;
BA_ "GenMsgCycleTime" BO_ 784 100;
BA_ "GenMsgSendType" BO_ 784 0;
BA_ "VFrameFormat" BO_ 784 14;
BA_ "GenMsgCycleTime" BO_ 790 100;
BA_ "GenMsgSendType" BO_ 790 0;
BA_ "VFrameFormat" BO_ 790 14;
BA_ "GenMsgCycleTime" BO_ 800 100;
BA_ "GenMsgSendType" BO_ 800 0;
BA_ "VFrameFormat" BO_ 800 14;
BA_ "GenMsgCycleTime" BO_ 822 100;
BA_ "GenMsgSendType" BO_ 822 0;
BA_ "VFrameFormat" BO_ 822 14;
BA_ "GenMsgCycleTime" BO_ 683 50;
BA_ "GenMsgSendType" BO_ 683 0;
BA_ "VFrameFormat" BO_ 683 14;
BA_ "GenMsgCycleTime" BO_ 711 50;
BA_ "GenMsgSendType" BO_ 711 0;
BA_ "VFrameFormat" BO_ 711 14;
BA_ "GenMsgCycleTime" BO_ 747 50;
BA_ "GenMsgSendType" BO_ 747 0;
BA_ "VFrameFormat" BO_ 747 14;
BA_ "GenMsgCycleTime" BO_ 750 50;
BA_ "GenMsgSendType" BO_ 750 0;
BA_ "VFrameFormat" BO_ 750 14;
BA_ "GenMsgCycleTime" BO_ 756 50;
BA_ "GenMsgSendType" BO_ 756 0;
BA_ "VFrameFormat" BO_ 756 14;
BA_ "GenMsgCycleTime" BO_ 831 100;
BA_ "GenMsgSendType" BO_ 831 0;
BA_ "VFrameFormat" BO_ 831 14;
BA_ "GenMsgCycleTime" BO_ 906 40;
BA_ "GenMsgSendType" BO_ 906 0;
BA_ "VFrameFormat" BO_ 906 14;
BA_ "GenMsgCycleTime" BO_ 1000 100;
BA_ "GenMsgSendType" BO_ 1000 0;
BA_ "VFrameFormat" BO_ 1000 14;
BA_ "GenMsgCycleTime" BO_ 1684 500;
BA_ "GenMsgSendType" BO_ 1684 0;
BA_ "VFrameFormat" BO_ 1684 14;
BA_ "GenMsgCycleTime" BO_ 723 40;
BA_ "GenMsgSendType" BO_ 723 0;
BA_ "VFrameFormat" BO_ 723 14;
BA_ "GenMsgCycleTime" BO_ 780 100;
BA_ "GenMsgSendType" BO_ 780 0;
BA_ "VFrameFormat" BO_ 780 14;
BA_ "GenMsgCycleTime" BO_ 738 50;
BA_ "GenMsgSendType" BO_ 738 0;
BA_ "VFrameFormat" BO_ 738 14;
BA_ "GenMsgCycleTime" BO_ 739 50;
BA_ "GenMsgSendType" BO_ 739 0;
BA_ "VFrameFormat" BO_ 739 14;
BA_ "GenMsgCycleTime" BO_ 1304 500;
BA_ "GenMsgSendType" BO_ 1304 0;
BA_ "VFrameFormat" BO_ 1304 14;
BA_ "GenMsgCycleTime" BO_ 686 50;
BA_ "GenMsgSendType" BO_ 686 0;
BA_ "VFrameFormat" BO_ 686 14;
BA_ "GenMsgCycleTime" BO_ 985 100;
BA_ "GenMsgSendType" BO_ 985 0;
BA_ "VFrameFormat" BO_ 985 14;
BA_ "GenMsgCycleTime" BO_ 987 100;
BA_ "GenMsgSendType" BO_ 987 0;
BA_ "VFrameFormat" BO_ 987 14;
BA_ "GenSigCycleTime" SG_ 999 BCM_Status_Temp 100;
BA_ "GenSigInvalidValue" SG_ 999 BCM_Status_Temp "0";
BA_ "GenSigCycleTime" SG_ 999 BCM_T_BATT 100;
BA_ "GenSigInvalidValue" SG_ 999 BCM_T_BATT "255";
BA_ "GenSigStartValue" SG_ 999 BCM_T_BATT 255;
BA_ "GenSigCycleTime" SG_ 1021 BCM_DriveMode 100;
BA_ "GenSigInvalidValue" SG_ 1021 BCM_DriveMode "15";
BA_ "GenSigCycleTime" SG_ 1021 BCM_PowerManageLevel 100;
BA_ "GenSigInvalidValue" SG_ 1021 BCM_PowerManageLevel "7";
BA_ "GenSigCycleTime" SG_ 1310 TPMS_TireTemperature 500;
BA_ "GenSigInvalidValue" SG_ 1310 TPMS_TireTemperature "255";
BA_ "GenSigStartValue" SG_ 1310 TPMS_TireTemperature 40;
BA_ "GenSigCycleTime" SG_ 1310 TPMS_TirePosition 500;
BA_ "GenSigInvalidValue" SG_ 1310 TPMS_TirePosition "0";
BA_ "GenSigCycleTime" SG_ 1374 ADS_FCEventTimeSecond 500;
BA_ "GenSigCycleTime" SG_ 1374 ADS_FCEventTimeMinute 500;
BA_ "GenSigCycleTime" SG_ 1374 ADS_FCEventTimeHour 500;
BA_ "GenSigCycleTime" SG_ 1374 ADS_FCEventTimeDay 500;
BA_ "GenSigCycleTime" SG_ 1374 ADS_FCEventTimeMonth 500;
BA_ "GenSigCycleTime" SG_ 1374 ADS_FCEventTimeYear 500;
BA_ "GenSigCycleTime" SG_ 1374 ADS_FCEventCode 500;
BA_ "GenSigCycleTime" SG_ 1374 ADS_FCEventAmount 500;
BA_ "GenSigCycleTime" SG_ 1374 ADS_FCEventStartEndIdentify 500;
BA_ "GenSigCycleTime" SG_ 1374 ADS_FCEID 500;
BA_ "GenSigCycleTime" SG_ 1374 ADS_FCControllerCode 500;
BA_ "GenSigCycleTime" SG_ 652 GW_MFS_handsoffDetectResult 40;
BA_ "GenSigCycleTime" SG_ 652 GW_MFS_CRCCheck_28C 40;
BA_ "GenSigCycleTime" SG_ 652 GW_MFS_RollingCounter_28C 40;
BA_ "GenSigCycleTime" SG_ 652 GW_MFS_DiagInfoSW_28C 40;
BA_ "GenSigInvalidValue" SG_ 652 GW_MFS_DiagInfoSW_28C "7";
BA_ "GenSigCycleTime" SG_ 652 GW_MFS_IACCenable_switch_signal 40;
BA_ "GenSigInvalidValue" SG_ 652 GW_MFS_IACCenable_switch_signal "3";
BA_ "GenSigCycleTime" SG_ 652 GW_MFS_DIST_switch_signal 40;
BA_ "GenSigInvalidValue" SG_ 652 GW_MFS_DIST_switch_signal "3";
BA_ "GenSigCycleTime" SG_ 652 GW_MFS_SETReduce_switch_signal 40;
BA_ "GenSigInvalidValue" SG_ 652 GW_MFS_SETReduce_switch_signal "3";
BA_ "GenSigCycleTime" SG_ 652 GW_MFS_RESPlus_switch_signal 40;
BA_ "GenSigInvalidValue" SG_ 652 GW_MFS_RESPlus_switch_signal "3";
BA_ "GenSigCycleTime" SG_ 652 GW_MFS_Cancle_switch_signal 40;
BA_ "GenSigInvalidValue" SG_ 652 GW_MFS_Cancle_switch_signal "3";
BA_ "GenSigCycleTime" SG_ 652 GW_MFS_Crusie_switch_signal 40;
BA_ "GenSigInvalidValue" SG_ 652 GW_MFS_Crusie_switch_signal "3";
BA_ "GenSigCycleTime" SG_ 652 GW_MFS_DISTReduce_switch_signal 40;
BA_ "GenSigCycleTime" SG_ 652 GW_MFS_DISTPlus_switch_signal 40;
BA_ "GenSigCycleTime" SG_ 1426 LAS_NotSleep_BYTE7BIT1 1000;
BA_ "GenSigCycleTime" SG_ 1426 LAS_NotSleep_BYTE7BIT0 1000;
BA_ "GenSigCycleTime" SG_ 1426 LAS_WakeUp_BYTE4BIT1 1000;
BA_ "GenSigCycleTime" SG_ 1426 LAS_WakeUp_BYTE4BIT0 1000;
BA_ "GenSigCycleTime" SG_ 1428 FR_NotSleep_BYTE7BIT1 1000;
BA_ "GenSigCycleTime" SG_ 1428 FR_NotSleep_BYTE7BIT0 1000;
BA_ "GenSigCycleTime" SG_ 1428 FR_WakeUp_BYTE4BIT1 1000;
BA_ "GenSigCycleTime" SG_ 1428 FR_WakeUp_BYTE4BIT0 1000;
BA_ "GenSigCycleTime" SG_ 80 SRS_WarningLampStatus 500;
BA_ "GenSigCycleTime" SG_ 80 SRS_DriverBuckleSwitchStatus 500;
BA_ "GenSigCycleTime" SG_ 80 SRS_RollingCounter_id050 500;
BA_ "GenSigCycleTime" SG_ 80 SRS_CrashOutputStatusCheckSum 500;
BA_ "GenSigCycleTime" SG_ 80 SRS_CrashOutputStatus 500;
BA_ "GenSigCycleTime" SG_ 80 SRS_CRCCheck_50 500;
BA_ "GenSigCycleTime" SG_ 898 ACC_RollingCounter_382 100;
BA_ "GenSigCycleTime" SG_ 898 ACC_CRCCheck_382 100;
BA_ "GenSigCycleTime" SG_ 898 ACC_CRCCheck_3E6 100;
BA_ "GenSigCycleTime" SG_ 898 ACC_RollingCounter_3E6 100;
BA_ "GenSigCycleTime" SG_ 898 ACC_LaneEquationStatus 100;
BA_ "GenSigCycleTime" SG_ 898 ACC_LaneEquationC3 100;
BA_ "GenSigStartValue" SG_ 898 ACC_LaneEquationC3 2047;
BA_ "GenSigCycleTime" SG_ 898 ACC_LaneEquationC2 100;
BA_ "GenSigStartValue" SG_ 898 ACC_LaneEquationC2 2047;
BA_ "GenSigCycleTime" SG_ 898 ACC_LaneEquationC1 100;
BA_ "GenSigStartValue" SG_ 898 ACC_LaneEquationC1 2047;
BA_ "GenSigCycleTime" SG_ 898 ACC_LaneQuality 100;
BA_ "GenSigCycleTime" SG_ 898 ACC_CRCCheck_35C 100;
BA_ "GenSigCycleTime" SG_ 898 ACC_RollingCounter_35C 100;
BA_ "GenSigCycleTime" SG_ 898 ACC_FRTarget2Type 100;
BA_ "GenSigCycleTime" SG_ 898 ACC_FRTarget2LatRange 100;
BA_ "GenSigStartValue" SG_ 898 ACC_FRTarget2LatRange 500;
BA_ "GenSigCycleTime" SG_ 898 ACC_FRTarget2LngRange 100;
BA_ "GenSigStartValue" SG_ 898 ACC_FRTarget2LngRange 500;
BA_ "GenSigCycleTime" SG_ 898 ACC_FRTarget2Detection 100;
BA_ "GenSigCycleTime" SG_ 898 ACC_FRTarget2Direction 100;
BA_ "GenSigStartValue" SG_ 898 ACC_FRTarget2Direction 5;
BA_ "GenSigCycleTime" SG_ 898 ACC_CRCCheck_35D 100;
BA_ "GenSigCycleTime" SG_ 898 ACC_RollingCounter_35D 100;
BA_ "GenSigCycleTime" SG_ 898 ACC_FRTarget1Direction 100;
BA_ "GenSigStartValue" SG_ 898 ACC_FRTarget1Direction 5;
BA_ "GenSigCycleTime" SG_ 898 ACC_FRTarget1Type 100;
BA_ "GenSigCycleTime" SG_ 898 ACC_FRTarget1LatRange 100;
BA_ "GenSigStartValue" SG_ 898 ACC_FRTarget1LatRange 500;
BA_ "GenSigCycleTime" SG_ 898 ACC_FRTarget1LngRange 100;
BA_ "GenSigStartValue" SG_ 898 ACC_FRTarget1LngRange 500;
BA_ "GenSigCycleTime" SG_ 898 ACC_FRTarget1Detection 100;
BA_ "GenSigCycleTime" SG_ 898 ACC_FLTarget2LatRange 100;
BA_ "GenSigStartValue" SG_ 898 ACC_FLTarget2LatRange 500;
BA_ "GenSigCycleTime" SG_ 1328 IP_TotalOdometer 500;
BA_ "GenSigInvalidValue" SG_ 1328 IP_TotalOdometer "16777215";
BA_ "GenSigCycleTime" SG_ 391 ESP_ABSFailStatus 10;
BA_ "GenSigCycleTime" SG_ 391 ESP_ESPFunctionStatus 10;
BA_ "GenSigStartValue" SG_ 391 ESP_ESPFunctionStatus 1;
BA_ "GenSigCycleTime" SG_ 391 ESP_TCSFailStatus 10;
BA_ "GenSigCycleTime" SG_ 391 ESP_VehicleSpeed 10;
BA_ "GenSigInvalidValue" SG_ 391 ESP_VehicleSpeed "8191";
BA_ "GenSigCycleTime" SG_ 391 ESP_VehicleSpeedValid 10;
BA_ "GenSigInvalidValue" SG_ 391 ESP_VehicleSpeedValid "1";
BA_ "GenSigCycleTime" SG_ 391 ESP_ESPActiveStatus 10;
BA_ "GenSigCycleTime" SG_ 391 ESP_EngTorqInc 10;
BA_ "GenSigInvalidValue" SG_ 391 ESP_EngTorqInc "0";
BA_ "GenSigCycleTime" SG_ 391 ESP_RollingCounter_187 10;
BA_ "GenSigCycleTime" SG_ 391 ESP_EngTorqIncActive 10;
BA_ "GenSigCycleTime" SG_ 391 ESP_EngTorqDecActive 10;
BA_ "GenSigCycleTime" SG_ 391 ESP_CRCCheck_187 10;
BA_ "GenSigCycleTime" SG_ 391 ESP_ABSActiveStatus 10;
BA_ "GenSigCycleTime" SG_ 407 ESP_RollingCounter_197 10;
BA_ "GenSigCycleTime" SG_ 407 EPB_SwitchPosition 10;
BA_ "GenSigInvalidValue" SG_ 407 EPB_SwitchPosition "3";
BA_ "GenSigCycleTime" SG_ 407 EPB_SwitchPositionValid 10;
BA_ "GenSigInvalidValue" SG_ 407 EPB_SwitchPositionValid "1";
BA_ "GenSigStartValue" SG_ 407 EPB_SwitchPositionValid 1;
BA_ "GenSigCycleTime" SG_ 407 EPB_FailStatus 10;
BA_ "GenSigCycleTime" SG_ 407 EPB_AchievedClampForce 10;
BA_ "GenSigInvalidValue" SG_ 407 EPB_AchievedClampForce "31";
BA_ "GenSigStartValue" SG_ 407 EPB_AchievedClampForce 29;
BA_ "GenSigCycleTime" SG_ 407 ESP_CRCCheck_197 10;
BA_ "GenSigCycleTime" SG_ 407 EPB_Status 10;
BA_ "GenSigCycleTime" SG_ 523 ESP_RollingCounter_20B 20;
BA_ "GenSigCycleTime" SG_ 523 ESP_CRCCheck_20B 20;
BA_ "GenSigCycleTime" SG_ 523 ESP_Vehicle_Speed_Reference 20;
BA_ "GenSigInvalidValue" SG_ 523 ESP_Vehicle_Speed_Reference "8191";
BA_ "GenSigCycleTime" SG_ 523 Wheel_Speed_RR_Valid_Data 20;
BA_ "GenSigInvalidValue" SG_ 523 Wheel_Speed_RR_Valid_Data "1";
BA_ "GenSigCycleTime" SG_ 523 Wheel_Speed_RR_Pulse 20;
BA_ "GenSigInvalidValue" SG_ 523 Wheel_Speed_RR_Pulse "255";
BA_ "GenSigCycleTime" SG_ 523 Wheel_Speed_RR_Direction 20;
BA_ "GenSigCycleTime" SG_ 523 Wheel_Speed_RR_Data 20;
BA_ "GenSigInvalidValue" SG_ 523 Wheel_Speed_RR_Data "8191";
BA_ "GenSigCycleTime" SG_ 523 Wheel_Speed_RL_Valid_Data 20;
BA_ "GenSigInvalidValue" SG_ 523 Wheel_Speed_RL_Valid_Data "1";
BA_ "GenSigCycleTime" SG_ 523 Wheel_Speed_RL_Pulse 20;
BA_ "GenSigInvalidValue" SG_ 523 Wheel_Speed_RL_Pulse "255";
BA_ "GenSigCycleTime" SG_ 523 Wheel_Speed_RL_Direction 20;
BA_ "GenSigInvalidValue" SG_ 523 Wheel_Speed_RL_Direction "3";
BA_ "GenSigCycleTime" SG_ 523 Wheel_Speed_RL_Data 20;
BA_ "GenSigInvalidValue" SG_ 523 Wheel_Speed_RL_Data "8191";
BA_ "GenSigCycleTime" SG_ 523 Wheel_Speed_FR_Valid_Data 20;
BA_ "GenSigInvalidValue" SG_ 523 Wheel_Speed_FR_Valid_Data "1";
BA_ "GenSigCycleTime" SG_ 523 Wheel_Speed_FR_Direction 20;
BA_ "GenSigInvalidValue" SG_ 523 Wheel_Speed_FR_Direction "3";
BA_ "GenSigCycleTime" SG_ 523 Wheel_Speed_FR_Data 20;
BA_ "GenSigInvalidValue" SG_ 523 Wheel_Speed_FR_Data "8191";
BA_ "GenSigCycleTime" SG_ 523 Wheel_Speed_FL_Valid_Data 20;
BA_ "GenSigInvalidValue" SG_ 523 Wheel_Speed_FL_Valid_Data "1";
BA_ "GenSigCycleTime" SG_ 523 Wheel_Speed_FL_Direction 20;
BA_ "GenSigInvalidValue" SG_ 523 Wheel_Speed_FL_Direction "3";
BA_ "GenSigCycleTime" SG_ 523 Wheel_Speed_FL_Data 20;
BA_ "GenSigInvalidValue" SG_ 523 Wheel_Speed_FL_Data "8191";
BA_ "GenSigCycleTime" SG_ 523 ESP_VehicleStandstill 20;
BA_ "GenSigCycleTime" SG_ 523 ESP_VDCActive 20;
BA_ "GenSigCycleTime" SG_ 523 ESP_TCSActive 20;
BA_ "GenSigCycleTime" SG_ 523 ESP_RollingCounter_277 20;
BA_ "GenSigCycleTime" SG_ 523 ESP_RollingCounter_258 20;
BA_ "GenSigCycleTime" SG_ 523 ESP_RollingCounter_208 20;
BA_ "GenSigCycleTime" SG_ 523 ESP_RollingCounter_206 20;
BA_ "GenSigCycleTime" SG_ 523 ESP_QDCACC 20;
BA_ "GenSigCycleTime" SG_ 523 ESP_PrefillAvailable 20;
BA_ "GenSigCycleTime" SG_ 523 ESP_PrefillActive 20;
BA_ "GenSigCycleTime" SG_ 523 ESP_OnlyABSActive 20;
BA_ "GenSigCycleTime" SG_ 523 ESP_MasCylBrakePressureValid 20;
BA_ "GenSigCycleTime" SG_ 523 ESP_MasCylBrakePressure 20;
BA_ "GenSigInvalidValue" SG_ 523 ESP_MasCylBrakePressure "4095";
BA_ "GenSigCycleTime" SG_ 523 ESP_HDC_STATUS 20;
BA_ "GenSigInvalidValue" SG_ 523 ESP_HDC_STATUS "3";
BA_ "GenSigCycleTime" SG_ 523 ESP_CRCCheck_277 20;
BA_ "GenSigCycleTime" SG_ 523 ESP_CRCCheck_258 20;
BA_ "GenSigCycleTime" SG_ 523 ESP_CRCCheck_208 20;
BA_ "GenSigCycleTime" SG_ 523 ESP_CRCCheck_206 20;
BA_ "GenSigCycleTime" SG_ 523 ESP_CDD_Available 20;
BA_ "GenSigCycleTime" SG_ 523 ESP_CDD_Active 20;
BA_ "GenSigCycleTime" SG_ 523 ESP_BrakeOverHeatBrakeDiscTemp 20;
BA_ "GenSigCycleTime" SG_ 523 ESP_BrakeForce 20;
BA_ "GenSigCycleTime" SG_ 523 ESP_AWBavailable 20;
BA_ "GenSigCycleTime" SG_ 523 ESP_AWBactive 20;
BA_ "GenSigCycleTime" SG_ 523 ESP_AEBdecActive 20;
BA_ "GenSigCycleTime" SG_ 523 ESP_AEBAvailable 20;
BA_ "GenSigCycleTime" SG_ 523 ESP_ABAavailable 20;
BA_ "GenSigCycleTime" SG_ 523 ESP_ABAactive 20;
BA_ "GenSigCycleTime" SG_ 734 IP_CRCCheck_2DE 50;
BA_ "GenSigCycleTime" SG_ 734 IP_RollingCounter_2DE 50;
BA_ "GenSigCycleTime" SG_ 734 IP_DISFail 50;
BA_ "GenSigInvalidValue" SG_ 734 IP_DISFail "0";
BA_ "GenSigCycleTime" SG_ 734 IP_QDashACCFail 50;
BA_ "GenSigInvalidValue" SG_ 734 IP_QDashACCFail "0";
BA_ "GenSigCycleTime" SG_ 947 BCM_BrakeLampError 100;
BA_ "GenSigCycleTime" SG_ 947 BCM_RearFoglampStatus 100;
BA_ "GenSigInvalidValue" SG_ 947 BCM_RearFoglampStatus "3";
BA_ "GenSigCycleTime" SG_ 1023 BCM_RightLowBeamError 100;
BA_ "GenSigCycleTime" SG_ 1023 BCM_LeftLowBeamError 100;
BA_ "GenSigCycleTime" SG_ 1023 BCM_AutoHeadlightSts 100;
BA_ "GenSigInvalidValue" SG_ 1023 BCM_AutoHeadlightSts "0";
BA_ "GenSigCycleTime" SG_ 1023 BCM_FrontFoglampStatus 100;
BA_ "GenSigInvalidValue" SG_ 1023 BCM_FrontFoglampStatus "3";
BA_ "GenSigCycleTime" SG_ 632 ESP_YawRateValid 20;
BA_ "GenSigCycleTime" SG_ 632 ESP_YawRate 20;
BA_ "GenSigInvalidValue" SG_ 632 ESP_YawRate "16383";
BA_ "GenSigCycleTime" SG_ 632 ESP_RollingCounter_278 20;
BA_ "GenSigCycleTime" SG_ 632 ESP_LongAccel 20;
BA_ "GenSigInvalidValue" SG_ 632 ESP_LongAccel "1023";
BA_ "GenSigCycleTime" SG_ 632 ESP_LatAccel 20;
BA_ "GenSigInvalidValue" SG_ 632 ESP_LatAccel "255";
BA_ "GenSigCycleTime" SG_ 632 ESP_CRCCheck_278 20;
BA_ "GenSigCycleTime" SG_ 384 SAS_CRCCheck 10;
BA_ "GenSigCycleTime" SG_ 384 SAS_RollingCounter 10;
BA_ "GenSigCycleTime" SG_ 384 SAS_SteeringAngleSpeed 10;
BA_ "GenSigInvalidValue" SG_ 384 SAS_SteeringAngleSpeed "255";
BA_ "GenSigCycleTime" SG_ 384 SAS_SteeringAngle 10;
BA_ "GenSigInvalidValue" SG_ 384 SAS_SteeringAngle "32767";
BA_ "GenSigCycleTime" SG_ 384 SAS_SASFailure 10;
BA_ "GenSigInvalidValue" SG_ 384 SAS_SASFailure "1";
BA_ "GenSigCycleTime" SG_ 384 SAS_Calibrated 10;
BA_ "GenSigCycleTime" SG_ 384 SAS_SteeringAngleValid 10;
BA_ "GenSigInvalidValue" SG_ 384 SAS_SteeringAngleValid "1";
BA_ "GenSigCycleTime" SG_ 424 TCU_FastOnMode 10;
BA_ "GenSigCycleTime" SG_ 424 TCU_VehicleSpeed 10;
BA_ "GenSigInvalidValue" SG_ 424 TCU_VehicleSpeed "8191";
BA_ "GenSigCycleTime" SG_ 424 TCU_ActualGear 10;
BA_ "GenSigInvalidValue" SG_ 424 TCU_ActualGear "15";
BA_ "GenSigCycleTime" SG_ 424 TCU_ActualGearValid 10;
BA_ "GenSigInvalidValue" SG_ 424 TCU_ActualGearValid "1";
BA_ "GenSigCycleTime" SG_ 424 TCU_GearShiftPosition 10;
BA_ "GenSigInvalidValue" SG_ 424 TCU_GearShiftPosition "15";
BA_ "GenSigStartValue" SG_ 424 TCU_GearShiftPosition 14;
BA_ "GenSigCycleTime" SG_ 424 TCU_ShiftPostionValid 10;
BA_ "GenSigInvalidValue" SG_ 424 TCU_ShiftPostionValid "1";
BA_ "GenSigCycleTime" SG_ 424 TCU_TransFailureStatus 10;
BA_ "GenSigCycleTime" SG_ 424 TCU_CRCCheck_1A8 10;
BA_ "GenSigCycleTime" SG_ 424 TCU_RollingCounter_1A8 10;
BA_ "GenSigCycleTime" SG_ 784 AMP_AllAlarmFailureStatus 100;
BA_ "GenSigCycleTime" SG_ 784 AMP_IPEnableAlarmFailureStatus 100;
BA_ "GenSigCycleTime" SG_ 790 LAS_Line_04_MeasureType_FT 100;
BA_ "GenSigCycleTime" SG_ 790 LAS_Line_03_MeasureType_FT 100;
BA_ "GenSigCycleTime" SG_ 790 LAS_Line_02_MeasureType_FT 100;
BA_ "GenSigCycleTime" SG_ 790 LAS_Line_01_MeasureType_FT 100;
BA_ "GenSigCycleTime" SG_ 790 LAS_Line_03_curvature_alte_FT 100;
BA_ "GenSigStartValue" SG_ 790 LAS_Line_03_curvature_alte_FT 2048;
BA_ "GenSigCycleTime" SG_ 790 LAS_Line_03_curve_FT 100;
BA_ "GenSigStartValue" SG_ 790 LAS_Line_03_curve_FT 12288;
BA_ "GenSigCycleTime" SG_ 790 LAS_Line_02_curvature_alte_FT 100;
BA_ "GenSigStartValue" SG_ 790 LAS_Line_02_curvature_alte_FT 2048;
BA_ "GenSigCycleTime" SG_ 790 LAS_Line_02_curve_FT 100;
BA_ "GenSigStartValue" SG_ 790 LAS_Line_02_curve_FT 12288;
BA_ "GenSigCycleTime" SG_ 790 LAS_Line_01_curvature_alte_FT 100;
BA_ "GenSigStartValue" SG_ 790 LAS_Line_01_curvature_alte_FT 2048;
BA_ "GenSigCycleTime" SG_ 790 LAS_Line_01_curve_FT 100;
BA_ "GenSigStartValue" SG_ 790 LAS_Line_01_curve_FT 12288;
BA_ "GenSigCycleTime" SG_ 790 LAS_RollingCounter_316 100;
BA_ "GenSigCycleTime" SG_ 790 LAS_CRCCheck_316 100;
BA_ "GenSigCycleTime" SG_ 790 LAS_Line_03_MeasureType 100;
BA_ "GenSigCycleTime" SG_ 790 LAS_Line_03_curvature_alteration 100;
BA_ "GenSigStartValue" SG_ 790 LAS_Line_03_curvature_alteration 2048;
BA_ "GenSigCycleTime" SG_ 790 LAS_Line_03__curve 100;
BA_ "GenSigStartValue" SG_ 790 LAS_Line_03__curve 4096;
BA_ "GenSigCycleTime" SG_ 790 LAS_Line_03_HeadingAngle 100;
BA_ "GenSigStartValue" SG_ 790 LAS_Line_03_HeadingAngle 3277;
BA_ "GenSigCycleTime" SG_ 790 LAS_Line_03_dy 100;
BA_ "GenSigCycleTime" SG_ 790 LAS_Line_03_dx_End_std 100;
BA_ "GenSigCycleTime" SG_ 790 LAS_Line_03__dx_End 100;
BA_ "GenSigCycleTime" SG_ 790 LAS_Line_03_dx_Start_std 100;
BA_ "GenSigCycleTime" SG_ 790 LAS_Line_03_dx_Start 100;
BA_ "GenSigCycleTime" SG_ 790 LAS_Line_03_Width 100;
BA_ "GenSigCycleTime" SG_ 790 LAS_Line_03_color 100;
BA_ "GenSigCycleTime" SG_ 790 LAS_Line_03_Id 100;
BA_ "GenSigStartValue" SG_ 790 LAS_Line_03_Id 1;
BA_ "GenSigCycleTime" SG_ 790 LAS_Line_03_TypeConfidence 100;
BA_ "GenSigCycleTime" SG_ 790 LAS_Line_03_Type 100;
BA_ "GenSigCycleTime" SG_ 790 LAS_Line_02__exist_prob 100;
BA_ "GenSigCycleTime" SG_ 790 LAS_Line_02_MeasureType 100;
BA_ "GenSigCycleTime" SG_ 790 LAS_Line_02_curvature_alteration 100;
BA_ "GenSigStartValue" SG_ 790 LAS_Line_02_curvature_alteration 2048;
BA_ "GenSigCycleTime" SG_ 790 LAS_Line_02__curve 100;
BA_ "GenSigStartValue" SG_ 790 LAS_Line_02__curve 4096;
BA_ "GenSigCycleTime" SG_ 790 LAS_Line_02_HeadingAngle 100;
BA_ "GenSigStartValue" SG_ 790 LAS_Line_02_HeadingAngle 3277;
BA_ "GenSigCycleTime" SG_ 790 LAS_Line_02_dy 100;
BA_ "GenSigCycleTime" SG_ 790 LAS_Line_02_dx_End_std 100;
BA_ "GenSigCycleTime" SG_ 790 LAS_Line_02__dx_End 100;
BA_ "GenSigCycleTime" SG_ 790 LAS_Line_02_dx_Start_std 100;
BA_ "GenSigCycleTime" SG_ 790 LAS_Line_02_dx_Start 100;
BA_ "GenSigCycleTime" SG_ 790 LAS_Line_02_Width 100;
BA_ "GenSigCycleTime" SG_ 790 LAS_Line_02_color 100;
BA_ "GenSigCycleTime" SG_ 790 LAS_Line_02_Id 100;
BA_ "GenSigStartValue" SG_ 790 LAS_Line_02_Id 1;
BA_ "GenSigCycleTime" SG_ 790 LAS_Line_02_TypeConfidence 100;
BA_ "GenSigCycleTime" SG_ 790 LAS_Line_02_Type 100;
BA_ "GenSigCycleTime" SG_ 790 LAS_Line_01__exist_prob 100;
BA_ "GenSigCycleTime" SG_ 790 LAS_Line_01_MeasureType 100;
BA_ "GenSigCycleTime" SG_ 790 LAS_Line_01_curvature_alteration 100;
BA_ "GenSigStartValue" SG_ 790 LAS_Line_01_curvature_alteration 2048;
BA_ "GenSigCycleTime" SG_ 790 LAS_Line_01__curve 100;
BA_ "GenSigStartValue" SG_ 790 LAS_Line_01__curve 4096;
BA_ "GenSigCycleTime" SG_ 790 LAS_Line_01_HeadingAngle 100;
BA_ "GenSigStartValue" SG_ 790 LAS_Line_01_HeadingAngle 3277;
BA_ "GenSigCycleTime" SG_ 790 LAS_Line_01_dy 100;
BA_ "GenSigCycleTime" SG_ 790 LAS_Line_01_dx_End_std 100;
BA_ "GenSigCycleTime" SG_ 790 LAS_Line_01__dx_End 100;
BA_ "GenSigCycleTime" SG_ 790 LAS_Line_01_dx_Start_std 100;
BA_ "GenSigCycleTime" SG_ 790 LAS_Line_01_dx_Start 100;
BA_ "GenSigCycleTime" SG_ 790 LAS_Line_01_Width 100;
BA_ "GenSigCycleTime" SG_ 790 LAS_Line_01_color 100;
BA_ "GenSigCycleTime" SG_ 790 LAS_Line_01_Id 100;
BA_ "GenSigStartValue" SG_ 790 LAS_Line_01_Id 1;
BA_ "GenSigCycleTime" SG_ 790 LAS_Line_01_TypeConfidence 100;
BA_ "GenSigCycleTime" SG_ 790 LAS_Line_01_Type 100;
BA_ "GenSigCycleTime" SG_ 800 GW_ResetReq 100;
BA_ "GenSigInvalidValue" SG_ 800 GW_ResetReq "127";
BA_ "GenSigCycleTime" SG_ 822 LAS_Line_06_MeasureType_FT 100;
BA_ "GenSigCycleTime" SG_ 822 LAS_Line_06_curve_FT 100;
BA_ "GenSigStartValue" SG_ 822 LAS_Line_06_curve_FT 12288;
BA_ "GenSigCycleTime" SG_ 822 LAS_Line_05_MeasureType_FT 100;
BA_ "GenSigCycleTime" SG_ 822 LAS_Line_05_curve_FT 100;
BA_ "GenSigStartValue" SG_ 822 LAS_Line_05_curve_FT 12288;
BA_ "GenSigCycleTime" SG_ 822 LAS_Line_04_curvature_alte_FT 100;
BA_ "GenSigStartValue" SG_ 822 LAS_Line_04_curvature_alte_FT 2048;
BA_ "GenSigCycleTime" SG_ 822 LAS_Line_04_curve_FT 100;
BA_ "GenSigStartValue" SG_ 822 LAS_Line_04_curve_FT 12288;
BA_ "GenSigCycleTime" SG_ 822 LAS_RollingCounter_336 100;
BA_ "GenSigCycleTime" SG_ 822 LAS_CRCCheck_336 100;
BA_ "GenSigCycleTime" SG_ 822 LAS_Line_06__exist_prob 100;
BA_ "GenSigCycleTime" SG_ 822 LAS_Line_06_MeasureType 100;
BA_ "GenSigCycleTime" SG_ 822 LAS_Line_06_curvature_alteration 100;
BA_ "GenSigStartValue" SG_ 822 LAS_Line_06_curvature_alteration 2048;
BA_ "GenSigCycleTime" SG_ 822 LAS_Line_06__curve 100;
BA_ "GenSigStartValue" SG_ 822 LAS_Line_06__curve 4096;
BA_ "GenSigCycleTime" SG_ 822 LAS_Line_06_HeadingAngle 100;
BA_ "GenSigStartValue" SG_ 822 LAS_Line_06_HeadingAngle 3277;
BA_ "GenSigCycleTime" SG_ 822 LAS_Line_06_dy 100;
BA_ "GenSigCycleTime" SG_ 822 LAS_Line_06_dx_End_std 100;
BA_ "GenSigCycleTime" SG_ 822 LAS_Line_06__dx_End 100;
BA_ "GenSigCycleTime" SG_ 822 LAS_Line_06_dx_Start_std 100;
BA_ "GenSigCycleTime" SG_ 822 LAS_Line_06_dx_Start 100;
BA_ "GenSigCycleTime" SG_ 822 LAS_Line_06_Width 100;
BA_ "GenSigCycleTime" SG_ 822 LAS_Line_06_color 100;
BA_ "GenSigCycleTime" SG_ 822 LAS_Line_06_Id 100;
BA_ "GenSigStartValue" SG_ 822 LAS_Line_06_Id 1;
BA_ "GenSigCycleTime" SG_ 822 LAS_Line_06_TypeConfidence 100;
BA_ "GenSigCycleTime" SG_ 822 LAS_Line_06_Type 100;
BA_ "GenSigCycleTime" SG_ 822 LAS_Line_05__exist_prob 100;
BA_ "GenSigCycleTime" SG_ 822 LAS_Line_05_MeasureType 100;
BA_ "GenSigCycleTime" SG_ 822 LAS_Line_05_curvature_alteration 100;
BA_ "GenSigStartValue" SG_ 822 LAS_Line_05_curvature_alteration 2048;
BA_ "GenSigCycleTime" SG_ 822 LAS_Line_05__curve 100;
BA_ "GenSigStartValue" SG_ 822 LAS_Line_05__curve 4096;
BA_ "GenSigCycleTime" SG_ 822 LAS_Line_05_HeadingAngle 100;
BA_ "GenSigStartValue" SG_ 822 LAS_Line_05_HeadingAngle 3277;
BA_ "GenSigCycleTime" SG_ 822 LAS_Line_05_dy 100;
BA_ "GenSigCycleTime" SG_ 822 LAS_Line_05_dx_End_std 100;
BA_ "GenSigCycleTime" SG_ 822 LAS_Line_05__dx_End 100;
BA_ "GenSigCycleTime" SG_ 822 LAS_Line_05_dx_Start_std 100;
BA_ "GenSigCycleTime" SG_ 822 LAS_Line_05_dx_Start 100;
BA_ "GenSigCycleTime" SG_ 822 LAS_Line_05_Width 100;
BA_ "GenSigCycleTime" SG_ 822 LAS_Line_05_color 100;
BA_ "GenSigCycleTime" SG_ 822 LAS_Line_05_Id 100;
BA_ "GenSigStartValue" SG_ 822 LAS_Line_05_Id 1;
BA_ "GenSigCycleTime" SG_ 822 LAS_Line_05_TypeConfidence 100;
BA_ "GenSigCycleTime" SG_ 822 LAS_Line_05_Type 100;
BA_ "GenSigCycleTime" SG_ 822 LAS_Line_04__exist_prob 100;
BA_ "GenSigCycleTime" SG_ 822 LAS_Line_04_MeasureType 100;
BA_ "GenSigCycleTime" SG_ 822 LAS_Line_04_curvature_alteration 100;
BA_ "GenSigStartValue" SG_ 822 LAS_Line_04_curvature_alteration 2048;
BA_ "GenSigCycleTime" SG_ 822 LAS_Line_04__curve 100;
BA_ "GenSigStartValue" SG_ 822 LAS_Line_04__curve 4096;
BA_ "GenSigCycleTime" SG_ 822 LAS_Line_04_HeadingAngle 100;
BA_ "GenSigStartValue" SG_ 822 LAS_Line_04_HeadingAngle 3277;
BA_ "GenSigCycleTime" SG_ 822 LAS_Line_04_dy 100;
BA_ "GenSigCycleTime" SG_ 822 LAS_Line_04_dx_End_std 100;
BA_ "GenSigCycleTime" SG_ 822 LAS_Line_04__dx_End 100;
BA_ "GenSigCycleTime" SG_ 822 LAS_Line_04_dx_Start_std 100;
BA_ "GenSigCycleTime" SG_ 822 LAS_Line_04_dx_Start 100;
BA_ "GenSigCycleTime" SG_ 822 LAS_Line_04_Width 100;
BA_ "GenSigCycleTime" SG_ 822 LAS_Line_04_color 100;
BA_ "GenSigCycleTime" SG_ 822 LAS_Line_04_Id 100;
BA_ "GenSigStartValue" SG_ 822 LAS_Line_04_Id 1;
BA_ "GenSigCycleTime" SG_ 822 LAS_Line_04_TypeConfidence 100;
BA_ "GenSigCycleTime" SG_ 822 LAS_Line_04_Type 100;
BA_ "GenSigCycleTime" SG_ 822 LAS_Line_03__exist_prob 100;
BA_ "GenSigCycleTime" SG_ 683 FC_RollingCounter_28D 50;
BA_ "GenSigCycleTime" SG_ 683 FC_CRCCheck_28D 50;
BA_ "GenSigCycleTime" SG_ 683 FC_AEBOBJ_Track_Age 50;
BA_ "GenSigCycleTime" SG_ 683 FC_AEBOBJ_Track_ID 50;
BA_ "GenSigCycleTime" SG_ 683 FC_AEBOBJ_FusionedFC_Track_ID 50;
BA_ "GenSigCycleTime" SG_ 683 FC_AEBOBJ_fusion_Sts 50;
BA_ "GenSigCycleTime" SG_ 683 FC_AEBOBJ_ObstacleProb 50;
BA_ "GenSigCycleTime" SG_ 683 FC_AEBOBJ_ExistProb 50;
BA_ "GenSigCycleTime" SG_ 683 FC_AEBOBJ_Brakelight_Info 50;
BA_ "GenSigCycleTime" SG_ 683 FC_AEBOBJ_Taillight_Info 50;
BA_ "GenSigCycleTime" SG_ 683 FC_AEBOBJ_Dis_to_R_LaneMark 50;
BA_ "GenSigCycleTime" SG_ 683 FC_AEBOBJ_Dis_to_L_LaneMark 50;
BA_ "GenSigCycleTime" SG_ 683 FC_AEBOBJ_Ax 50;
BA_ "GenSigCycleTime" SG_ 683 FC_AEBOBJ_Ay 50;
BA_ "GenSigCycleTime" SG_ 683 FC_AEBOBJ_Vx_std 50;
BA_ "GenSigCycleTime" SG_ 683 FC_AEBOBJ_Vx 50;
BA_ "GenSigCycleTime" SG_ 683 FC_AEBOBJ_Vy_std 50;
BA_ "GenSigCycleTime" SG_ 683 FC_AEBOBJ_Vy 50;
BA_ "GenSigCycleTime" SG_ 683 FC_AEBOBJ_Dx_Vnce 50;
BA_ "GenSigCycleTime" SG_ 683 FC_AEBOBJ_Dx 50;
BA_ "GenSigCycleTime" SG_ 683 FC_AEBOBJ_Dy_Vnce 50;
BA_ "GenSigCycleTime" SG_ 683 FC_AEBOBJ_Dy 50;
BA_ "GenSigCycleTime" SG_ 683 FC_AEBOBJ_HeadingAngle 50;
BA_ "GenSigCycleTime" SG_ 683 FC_AEBOBJ_Length 50;
BA_ "GenSigCycleTime" SG_ 683 FC_AEBOBJ_Height 50;
BA_ "GenSigCycleTime" SG_ 683 FC_AEBOBJ_Width 50;
BA_ "GenSigCycleTime" SG_ 683 FC_AEBOBJ_Class 50;
BA_ "GenSigCycleTime" SG_ 711 FRC_TiOut 50;
BA_ "GenSigCycleTime" SG_ 711 FRC_TiLeap 50;
BA_ "GenSigCycleTime" SG_ 711 FRC_TiBas 50;
BA_ "GenSigCycleTime" SG_ 711 FRC_TiStamp 50;
BA_ "GenSigCycleTime" SG_ 711 FRC_FCTBStatus 50;
BA_ "GenSigInvalidValue" SG_ 711 FRC_FCTBStatus "3";
BA_ "GenSigCycleTime" SG_ 711 FRC_FCTAEnable 50;
BA_ "GenSigStartValue" SG_ 711 FRC_FCTAEnable 1;
BA_ "GenSigCycleTime" SG_ 711 FRC_PrefillActive 50;
BA_ "GenSigCycleTime" SG_ 711 FRC_RollingCounter_2C7 50;
BA_ "GenSigCycleTime" SG_ 711 FRC_CRCCheck_2C7 50;
BA_ "GenSigCycleTime" SG_ 711 FRC_ObjDelay 50;
BA_ "GenSigCycleTime" SG_ 711 FRC_SystemStatus 50;
BA_ "GenSigInvalidValue" SG_ 711 FRC_SystemStatus "7";
BA_ "GenSigStartValue" SG_ 711 FRC_SystemStatus 1;
BA_ "GenSigCycleTime" SG_ 711 FRC_Right_FCTARStatus 50;
BA_ "GenSigInvalidValue" SG_ 711 FRC_Right_FCTARStatus "3";
BA_ "GenSigCycleTime" SG_ 711 FRC_Right_FCTARAlert 50;
BA_ "GenSigCycleTime" SG_ 711 FRC_Left_FCTALAlert 50;
BA_ "GenSigCycleTime" SG_ 711 FRC_FCTBActive 50;
BA_ "GenSigInvalidValue" SG_ 711 FRC_FCTBActive "0";
BA_ "GenSigCycleTime" SG_ 711 FRC_FCTBTargetDeceleration 50;
BA_ "GenSigStartValue" SG_ 711 FRC_FCTBTargetDeceleration 32000;
BA_ "GenSigCycleTime" SG_ 711 FRC_FCTBEnable 50;
BA_ "GenSigStartValue" SG_ 711 FRC_FCTBEnable 1;
BA_ "GenSigCycleTime" SG_ 747 FC_RollingCounter_28F 50;
BA_ "GenSigCycleTime" SG_ 747 FC_CRCCheck_28F 50;
BA_ "GenSigCycleTime" SG_ 747 FC_FrFrOBJ_Track_Age 50;
BA_ "GenSigCycleTime" SG_ 747 FC_FrFrOBJ_Track_ID 50;
BA_ "GenSigCycleTime" SG_ 747 FC_FrFrOBJ_FusionedFC_Track_ID 50;
BA_ "GenSigCycleTime" SG_ 747 FC_FrFrOBJ_fusion_Sts 50;
BA_ "GenSigCycleTime" SG_ 747 FC_FrFrOBJ_ObstacleProb 50;
BA_ "GenSigCycleTime" SG_ 747 FC_FrFrOBJ_ExistProb 50;
BA_ "GenSigCycleTime" SG_ 747 FC_FrFrOBJ_Brakelight_Info 50;
BA_ "GenSigCycleTime" SG_ 747 FC_FrFrOBJ_Taillight_Info 50;
BA_ "GenSigCycleTime" SG_ 747 FC_FrFrOBJ_Dis_to_R_LaneMark 50;
BA_ "GenSigCycleTime" SG_ 747 FC_FrFrOBJ_Dis_to_L_LaneMark 50;
BA_ "GenSigCycleTime" SG_ 747 FC_FrFrOBJ_Ax 50;
BA_ "GenSigCycleTime" SG_ 747 FC_FrFrOBJ_Ay 50;
BA_ "GenSigCycleTime" SG_ 747 FC_FrFrOBJ_Vx_std 50;
BA_ "GenSigCycleTime" SG_ 747 FC_FrFrOBJ_Vx 50;
BA_ "GenSigCycleTime" SG_ 747 FC_FrFrOBJ_Vy_std 50;
BA_ "GenSigCycleTime" SG_ 747 FC_FrFrOBJ_Vy 50;
BA_ "GenSigCycleTime" SG_ 747 FC_FrFrOBJ_Dx_Vnce 50;
BA_ "GenSigCycleTime" SG_ 747 FC_FrFrOBJ_Dx 50;
BA_ "GenSigCycleTime" SG_ 747 FC_FrFrOBJ_Dy_Vnce 50;
BA_ "GenSigCycleTime" SG_ 747 FC_FrFrOBJ_Dy 50;
BA_ "GenSigCycleTime" SG_ 747 FC_FrFrOBJ_HeadingAngle 50;
BA_ "GenSigCycleTime" SG_ 747 FC_FrFrOBJ_Length 50;
BA_ "GenSigCycleTime" SG_ 747 FC_FrFrOBJ_Height 50;
BA_ "GenSigCycleTime" SG_ 747 FC_FrFrOBJ_Width 50;
BA_ "GenSigCycleTime" SG_ 747 FC_FrFrOBJ_Class 50;
BA_ "GenSigCycleTime" SG_ 747 FC_FrOBJ_Track_Age 50;
BA_ "GenSigCycleTime" SG_ 747 FC_FrOBJ_Track_ID 50;
BA_ "GenSigCycleTime" SG_ 747 FC_FrOBJ_FusionedFC_Track_ID 50;
BA_ "GenSigCycleTime" SG_ 747 FC_FrOBJ_fusion_Sts 50;
BA_ "GenSigCycleTime" SG_ 747 FC_FrOBJ_ObstacleProb 50;
BA_ "GenSigCycleTime" SG_ 747 FC_FrOBJ_ExistProb 50;
BA_ "GenSigCycleTime" SG_ 747 FC_FrOBJ_Brakelight_Info 50;
BA_ "GenSigCycleTime" SG_ 747 FC_FrOBJ_Taillight_Info 50;
BA_ "GenSigCycleTime" SG_ 747 FC_FrOBJ_Dis_to_R_LaneMark 50;
BA_ "GenSigCycleTime" SG_ 747 FC_FrOBJ_Dis_to_L_LaneMark 50;
BA_ "GenSigCycleTime" SG_ 747 FC_FrOBJ_Ax 50;
BA_ "GenSigCycleTime" SG_ 747 FC_FrOBJ_Ay 50;
BA_ "GenSigCycleTime" SG_ 747 FC_FrOBJ_Vx_std 50;
BA_ "GenSigCycleTime" SG_ 747 FC_FrOBJ_Vx 50;
BA_ "GenSigCycleTime" SG_ 747 FC_FrOBJ_Vy_std 50;
BA_ "GenSigCycleTime" SG_ 747 FC_FrOBJ_Vy 50;
BA_ "GenSigCycleTime" SG_ 747 FC_FrOBJ_Dx_Vnce 50;
BA_ "GenSigCycleTime" SG_ 747 FC_FrOBJ_Dx 50;
BA_ "GenSigCycleTime" SG_ 747 FC_FrOBJ_Dy_Vnce 50;
BA_ "GenSigCycleTime" SG_ 747 FC_FrOBJ_Dy 50;
BA_ "GenSigCycleTime" SG_ 747 FC_FrOBJ_HeadingAngle 50;
BA_ "GenSigCycleTime" SG_ 747 FC_FrOBJ_Length 50;
BA_ "GenSigCycleTime" SG_ 747 FC_FrOBJ_Height 50;
BA_ "GenSigCycleTime" SG_ 747 FC_FrOBJ_Width 50;
BA_ "GenSigCycleTime" SG_ 747 FC_FrOBJ_Class 50;
BA_ "GenSigCycleTime" SG_ 750 FC_RollingCounter_29C 50;
BA_ "GenSigCycleTime" SG_ 750 FC_CRCCheck_29C 50;
BA_ "GenSigCycleTime" SG_ 750 FC_LeFrOBJ_Track_Age 50;
BA_ "GenSigCycleTime" SG_ 750 FC_LeFrOBJ_Track_ID 50;
BA_ "GenSigCycleTime" SG_ 750 FC_LeFrOBJ_FusionedFC_Track_ID 50;
BA_ "GenSigCycleTime" SG_ 750 FC_LeFrOBJ_fusion_Sts 50;
BA_ "GenSigCycleTime" SG_ 750 FC_LeFrOBJ_ObstacleProb 50;
BA_ "GenSigCycleTime" SG_ 750 FC_LeFrOBJ_ExistProb 50;
BA_ "GenSigCycleTime" SG_ 750 FC_LeFrOBJ_Brakelight_Info 50;
BA_ "GenSigCycleTime" SG_ 750 FC_LeFrOBJ_Taillight_Info 50;
BA_ "GenSigCycleTime" SG_ 750 FC_LeFrOBJ_Dis_to_R_LaneMark 50;
BA_ "GenSigCycleTime" SG_ 750 FC_LeFrOBJ_Dis_to_L_LaneMark 50;
BA_ "GenSigCycleTime" SG_ 750 FC_LeFrOBJ_Ax 50;
BA_ "GenSigCycleTime" SG_ 750 FC_LeFrOBJ_Ay 50;
BA_ "GenSigCycleTime" SG_ 750 FC_LeFrOBJ_Vx_std 50;
BA_ "GenSigCycleTime" SG_ 750 FC_LeFrOBJ_Vx 50;
BA_ "GenSigCycleTime" SG_ 750 FC_LeFrOBJ_Vy_std 50;
BA_ "GenSigCycleTime" SG_ 750 FC_LeFrOBJ_Vy 50;
BA_ "GenSigCycleTime" SG_ 750 FC_LeFrOBJ_Dx_Vnce 50;
BA_ "GenSigCycleTime" SG_ 750 FC_LeFrOBJ_Dx 50;
BA_ "GenSigCycleTime" SG_ 750 FC_LeFrOBJ_Dy_Vnce 50;
BA_ "GenSigCycleTime" SG_ 750 FC_LeFrOBJ_Dy 50;
BA_ "GenSigCycleTime" SG_ 750 FC_LeFrOBJ_HeadingAngle 50;
BA_ "GenSigCycleTime" SG_ 750 FC_LeFrOBJ_Length 50;
BA_ "GenSigCycleTime" SG_ 750 FC_LeFrOBJ_Height 50;
BA_ "GenSigCycleTime" SG_ 750 FC_LeFrOBJ_Width 50;
BA_ "GenSigCycleTime" SG_ 750 FC_LeFrOBJ_Class 50;
BA_ "GenSigCycleTime" SG_ 750 FC_LeOBJ_Track_Age 50;
BA_ "GenSigCycleTime" SG_ 750 FC_LeOBJ_Track_ID 50;
BA_ "GenSigCycleTime" SG_ 750 FC_LeOBJ_FusionedFC_Track_ID 50;
BA_ "GenSigCycleTime" SG_ 750 FC_LeOBJ_fusion_Sts 50;
BA_ "GenSigCycleTime" SG_ 750 FC_LeOBJ_ObstacleProb 50;
BA_ "GenSigCycleTime" SG_ 750 FC_LeOBJ_ExistProb 50;
BA_ "GenSigCycleTime" SG_ 750 FC_LeOBJ_Brakelight_Info 50;
BA_ "GenSigCycleTime" SG_ 750 FC_LeOBJ_Taillight_Info 50;
BA_ "GenSigCycleTime" SG_ 750 FC_LeOBJ_Dis_to_R_LaneMark 50;
BA_ "GenSigCycleTime" SG_ 750 FC_LeOBJ_Dis_to_L_LaneMark 50;
BA_ "GenSigCycleTime" SG_ 750 FC_LeOBJ_Ax 50;
BA_ "GenSigCycleTime" SG_ 750 FC_LeOBJ_Ay 50;
BA_ "GenSigCycleTime" SG_ 750 FC_LeOBJ_Vx_std 50;
BA_ "GenSigCycleTime" SG_ 750 FC_LeOBJ_Vx 50;
BA_ "GenSigCycleTime" SG_ 750 FC_LeOBJ_Vy_std 50;
BA_ "GenSigCycleTime" SG_ 750 FC_LeOBJ_Vy 50;
BA_ "GenSigCycleTime" SG_ 750 FC_LeOBJ_Dx_Vnce 50;
BA_ "GenSigCycleTime" SG_ 750 FC_LeOBJ_Dx 50;
BA_ "GenSigCycleTime" SG_ 750 FC_LeOBJ_Dy_Vnce 50;
BA_ "GenSigCycleTime" SG_ 750 FC_LeOBJ_Dy 50;
BA_ "GenSigCycleTime" SG_ 750 FC_LeOBJ_HeadingAngle 50;
BA_ "GenSigCycleTime" SG_ 750 FC_LeOBJ_Length 50;
BA_ "GenSigCycleTime" SG_ 750 FC_LeOBJ_Height 50;
BA_ "GenSigCycleTime" SG_ 750 FC_LeOBJ_Width 50;
BA_ "GenSigCycleTime" SG_ 750 FC_LeOBJ_Class 50;
BA_ "GenSigCycleTime" SG_ 756 FC_RollingCounter_29D 50;
BA_ "GenSigCycleTime" SG_ 756 FC_CRCCheck_29D 50;
BA_ "GenSigCycleTime" SG_ 756 FC_RiFrOBJ_Track_Age 50;
BA_ "GenSigCycleTime" SG_ 756 FC_RiFrOBJ_Track_ID 50;
BA_ "GenSigCycleTime" SG_ 756 FC_RiFrOBJ_FusionedFC_Track_ID 50;
BA_ "GenSigCycleTime" SG_ 756 FC_RiFrOBJ_fusion_Sts 50;
BA_ "GenSigCycleTime" SG_ 756 FC_RiFrOBJ_ObstacleProb 50;
BA_ "GenSigCycleTime" SG_ 756 FC_RiFrOBJ_ExistProb 50;
BA_ "GenSigCycleTime" SG_ 756 FC_RiFrOBJ_Brakelight_Info 50;
BA_ "GenSigCycleTime" SG_ 756 FC_RiFrOBJ_Taillight_Info 50;
BA_ "GenSigCycleTime" SG_ 756 FC_RiFrOBJ_Dis_to_R_LaneMark 50;
BA_ "GenSigCycleTime" SG_ 756 FC_RiFrOBJ_Dis_to_L_LaneMark 50;
BA_ "GenSigCycleTime" SG_ 756 FC_RiFrOBJ_Ax 50;
BA_ "GenSigCycleTime" SG_ 756 FC_RiFrOBJ_Ay 50;
BA_ "GenSigCycleTime" SG_ 756 FC_RiFrOBJ_Vx_std 50;
BA_ "GenSigCycleTime" SG_ 756 FC_RiFrOBJ_Vx 50;
BA_ "GenSigCycleTime" SG_ 756 FC_RiFrOBJ_Vy_std 50;
BA_ "GenSigCycleTime" SG_ 756 FC_RiFrOBJ_Vy 50;
BA_ "GenSigCycleTime" SG_ 756 FC_RiFrOBJ_Dx_Vnce 50;
BA_ "GenSigCycleTime" SG_ 756 FC_RiFrOBJ_Dx 50;
BA_ "GenSigCycleTime" SG_ 756 FC_RiFrOBJ_Dy_Vnce 50;
BA_ "GenSigCycleTime" SG_ 756 FC_RiFrOBJ_Dy 50;
BA_ "GenSigCycleTime" SG_ 756 FC_RiFrOBJ_HeadingAngle 50;
BA_ "GenSigCycleTime" SG_ 756 FC_RiFrOBJ_Length 50;
BA_ "GenSigCycleTime" SG_ 756 FC_RiFrOBJ_Height 50;
BA_ "GenSigCycleTime" SG_ 756 FC_RiFrOBJ_Width 50;
BA_ "GenSigCycleTime" SG_ 756 FC_RiFrOBJ_Class 50;
BA_ "GenSigCycleTime" SG_ 756 FC_RiOBJ_Track_Age 50;
BA_ "GenSigCycleTime" SG_ 756 FC_RiOBJ_Track_ID 50;
BA_ "GenSigCycleTime" SG_ 756 FC_RiOBJ_FusionedFC_Track_ID 50;
BA_ "GenSigCycleTime" SG_ 756 FC_RiOBJ_fusion_Sts 50;
BA_ "GenSigCycleTime" SG_ 756 FC_RiOBJ_ObstacleProb 50;
BA_ "GenSigCycleTime" SG_ 756 FC_RiOBJ_ExistProb 50;
BA_ "GenSigCycleTime" SG_ 756 FC_RiOBJ_Brakelight_Info 50;
BA_ "GenSigCycleTime" SG_ 756 FC_RiOBJ_Taillight_Info 50;
BA_ "GenSigCycleTime" SG_ 756 FC_RiOBJ_Dis_to_R_LaneMark 50;
BA_ "GenSigCycleTime" SG_ 756 FC_RiOBJ_Dis_to_L_LaneMark 50;
BA_ "GenSigCycleTime" SG_ 756 FC_RiOBJ_Ax 50;
BA_ "GenSigCycleTime" SG_ 756 FC_RiOBJ_Ay 50;
BA_ "GenSigCycleTime" SG_ 756 FC_RiOBJ_Vx_std 50;
BA_ "GenSigCycleTime" SG_ 756 FC_RiOBJ_Vx 50;
BA_ "GenSigCycleTime" SG_ 756 FC_RiOBJ_Vy_std 50;
BA_ "GenSigCycleTime" SG_ 756 FC_RiOBJ_Vy 50;
BA_ "GenSigCycleTime" SG_ 756 FC_RiOBJ_Dx_Vnce 50;
BA_ "GenSigCycleTime" SG_ 756 FC_RiOBJ_Dx 50;
BA_ "GenSigCycleTime" SG_ 756 FC_RiOBJ_Dy_Vnce 50;
BA_ "GenSigCycleTime" SG_ 756 FC_RiOBJ_Dy 50;
BA_ "GenSigCycleTime" SG_ 756 FC_RiOBJ_HeadingAngle 50;
BA_ "GenSigCycleTime" SG_ 756 FC_RiOBJ_Length 50;
BA_ "GenSigCycleTime" SG_ 756 FC_RiOBJ_Height 50;
BA_ "GenSigCycleTime" SG_ 756 FC_RiOBJ_Width 50;
BA_ "GenSigCycleTime" SG_ 756 FC_RiOBJ_Class 50;
BA_ "GenSigCycleTime" SG_ 831 LAS_RollingCounter_33F 100;
BA_ "GenSigCycleTime" SG_ 831 LAS_CRCCheck_33F 100;
BA_ "GenSigCycleTime" SG_ 831 LAS_Line_06_curvature_alte_FT 100;
BA_ "GenSigStartValue" SG_ 831 LAS_Line_06_curvature_alte_FT 2048;
BA_ "GenSigCycleTime" SG_ 831 LAS_Line_05_curvature_alte_FT 100;
BA_ "GenSigStartValue" SG_ 831 LAS_Line_05_curvature_alte_FT 2048;
BA_ "GenSigCycleTime" SG_ 906 GW_MFS_SeekReduce_switch 40;
BA_ "GenSigInvalidValue" SG_ 906 GW_MFS_SeekReduce_switch "3";
BA_ "GenSigCycleTime" SG_ 906 GW_MFS_Answer_switch_signal 40;
BA_ "GenSigInvalidValue" SG_ 906 GW_MFS_Answer_switch_signal "3";
BA_ "GenSigCycleTime" SG_ 906 GW_MFS_Hungup_switch_signal 40;
BA_ "GenSigInvalidValue" SG_ 906 GW_MFS_Hungup_switch_signal "3";
BA_ "GenSigCycleTime" SG_ 906 GW_MFS_SeekPlus_switch 40;
BA_ "GenSigInvalidValue" SG_ 906 GW_MFS_SeekPlus_switch "3";
BA_ "GenSigCycleTime" SG_ 906 GW_MFS_Mute_switch 40;
BA_ "GenSigInvalidValue" SG_ 906 GW_MFS_Mute_switch "3";
BA_ "GenSigCycleTime" SG_ 906 GW_MFS_VolReduce_switch 40;
BA_ "GenSigInvalidValue" SG_ 906 GW_MFS_VolReduce_switch "3";
BA_ "GenSigCycleTime" SG_ 906 GW_MFS_VolPlus_switch 40;
BA_ "GenSigInvalidValue" SG_ 906 GW_MFS_VolPlus_switch "3";
BA_ "GenSigCycleTime" SG_ 906 GW_MFS_Speech_switch 40;
BA_ "GenSigInvalidValue" SG_ 906 GW_MFS_Speech_switch "3";
BA_ "GenSigCycleTime" SG_ 906 GW_MFS_OK_switch 40;
BA_ "GenSigInvalidValue" SG_ 906 GW_MFS_OK_switch "3";
BA_ "GenSigCycleTime" SG_ 906 GW_MFS_Down_switch 40;
BA_ "GenSigInvalidValue" SG_ 906 GW_MFS_Down_switch "3";
BA_ "GenSigCycleTime" SG_ 906 GW_MFS_UP_switch 40;
BA_ "GenSigInvalidValue" SG_ 906 GW_MFS_UP_switch "3";
BA_ "GenSigCycleTime" SG_ 906 GW_MFS_Right_switch 40;
BA_ "GenSigInvalidValue" SG_ 906 GW_MFS_Right_switch "3";
BA_ "GenSigCycleTime" SG_ 906 GW_MFS_Left_switch 40;
BA_ "GenSigInvalidValue" SG_ 906 GW_MFS_Left_switch "3";
BA_ "GenSigCycleTime" SG_ 1000 BCM_SOF_Q_STATE 100;
BA_ "GenSigInvalidValue" SG_ 1000 BCM_SOF_Q_STATE "3";
BA_ "GenSigStartValue" SG_ 1000 BCM_SOF_Q_STATE 3;
BA_ "GenSigCycleTime" SG_ 1000 BCM_SOF_Q 100;
BA_ "GenSigInvalidValue" SG_ 1000 BCM_SOF_Q "255";
BA_ "GenSigStartValue" SG_ 1000 BCM_SOF_Q 255;
BA_ "GenSigCycleTime" SG_ 1684 LAS_DTC2_Status 500;
BA_ "GenSigCycleTime" SG_ 1684 LAS_DTC2_LowByte 500;
BA_ "GenSigCycleTime" SG_ 1684 LAS_DTC2_MiddByte 500;
BA_ "GenSigCycleTime" SG_ 1684 LAS_DTC2_HighByte 500;
BA_ "GenSigCycleTime" SG_ 1684 LAS_DTC1_Status 500;
BA_ "GenSigCycleTime" SG_ 1684 LAS_DTC1_LowByte 500;
BA_ "GenSigCycleTime" SG_ 1684 LAS_DTC1_MiddByte 500;
BA_ "GenSigCycleTime" SG_ 1684 LAS_DTC1_HighByte 500;
BA_ "GenSigCycleTime" SG_ 723 ACC_CRCCheck_283 40;
BA_ "GenSigCycleTime" SG_ 723 ACC_RollingCounter_283 40;
BA_ "GenSigCycleTime" SG_ 723 ACC_AEBTargetLatRelSpeed_for_SRS 40;
BA_ "GenSigCycleTime" SG_ 723 ACC_AEBTargetLatRange_for_SRS 40;
BA_ "GenSigStartValue" SG_ 723 ACC_AEBTargetLatRange_for_SRS 500;
BA_ "GenSigCycleTime" SG_ 723 ACC_CRCCheckr_282 40;
BA_ "GenSigCycleTime" SG_ 723 ACC_RollingCounter_282 40;
BA_ "GenSigCycleTime" SG_ 723 ACC_AEBTargetProb_for_SRS 40;
BA_ "GenSigCycleTime" SG_ 723 ACC_AEBTargetType_for_SRS 40;
BA_ "GenSigStartValue" SG_ 723 ACC_AEBTargetType_for_SRS 15;
BA_ "GenSigCycleTime" SG_ 723 ACC_AEBTargetTTC_for_SRS 40;
BA_ "GenSigInvalidValue" SG_ 723 ACC_AEBTargetTTC_for_SRS "254";
BA_ "GenSigStartValue" SG_ 723 ACC_AEBTargetTTC_for_SRS 251;
BA_ "GenSigCycleTime" SG_ 723 ACC_AEBTargetRelSpeed_for_SRS 40;
BA_ "GenSigStartValue" SG_ 723 ACC_AEBTargetRelSpeed_for_SRS 250;
BA_ "GenSigCycleTime" SG_ 723 ACC_AEBTargetLngRange_for_SRS 40;
BA_ "GenSigStartValue" SG_ 723 ACC_AEBTargetLngRange_for_SRS 500;
BA_ "GenSigCycleTime" SG_ 723 ACC_AEBActive_for_SRS 40;
BA_ "GenSigCycleTime" SG_ 723 ACC_AEBStatus_for_SRS 40;
BA_ "GenSigInvalidValue" SG_ 723 ACC_AEBStatus_for_SRS "3";
BA_ "GenSigCycleTime" SG_ 780 LAS_ResetSts 100;
BA_ "GenSigInvalidValue" SG_ 780 LAS_ResetSts "7";
BA_ "GenSigCycleTime" SG_ 738 RLR_CRCCheck_2E2 50;
BA_ "GenSigCycleTime" SG_ 738 RLR_RollingCounter_2E2 50;
BA_ "GenSigCycleTime" SG_ 738 RLR_ElkOBJ2_Measured 50;
BA_ "GenSigInvalidValue" SG_ 738 RLR_ElkOBJ2_Measured "0";
BA_ "GenSigCycleTime" SG_ 738 RLR_ElkOBJ2_ExistProb 50;
BA_ "GenSigInvalidValue" SG_ 738 RLR_ElkOBJ2_ExistProb "0";
BA_ "GenSigCycleTime" SG_ 738 RLR_ElkOBJ2_Location 50;
BA_ "GenSigInvalidValue" SG_ 738 RLR_ElkOBJ2_Location "0";
BA_ "GenSigCycleTime" SG_ 738 RLR_ElkOBJ2_RelAx 50;
BA_ "GenSigCycleTime" SG_ 738 RLR_ElkOBJ2_RelAy 50;
BA_ "GenSigCycleTime" SG_ 738 RLR_ElkOBJ2_RelVx 50;
BA_ "GenSigCycleTime" SG_ 738 RLR_ElkOBJ2_RelVy 50;
BA_ "GenSigCycleTime" SG_ 738 RLR_ElkOBJ2_Dx 50;
BA_ "GenSigCycleTime" SG_ 738 RLR_ElkOBJ2_RefPointLoc 50;
BA_ "GenSigCycleTime" SG_ 738 RLR_ElkOBJ2_Dy 50;
BA_ "GenSigCycleTime" SG_ 738 RLR_ElkOBJ2_HeadingAngle 50;
BA_ "GenSigCycleTime" SG_ 738 RLR_ElkOBJ2_Length 50;
BA_ "GenSigCycleTime" SG_ 738 RLR_ElkOBJ2_Height 50;
BA_ "GenSigCycleTime" SG_ 738 RLR_ElkOBJ2_Width 50;
BA_ "GenSigCycleTime" SG_ 738 RLR_ElkOBJ2_Type 50;
BA_ "GenSigInvalidValue" SG_ 738 RLR_ElkOBJ2_Type "0";
BA_ "GenSigCycleTime" SG_ 738 RLR_ElkOBJ2_Track_ID 50;
BA_ "GenSigCycleTime" SG_ 738 RLR_ElkOBJ2_RefPointDx 50;
BA_ "GenSigCycleTime" SG_ 738 RLR_ElkOBJ2_RefPointDy 50;
BA_ "GenSigCycleTime" SG_ 738 RLR_ElkOBJ2_ObstacleProb 50;
BA_ "GenSigCycleTime" SG_ 738 RLR_ElkOBJ1_RefPointDx 50;
BA_ "GenSigCycleTime" SG_ 738 RLR_ElkOBJ1_RefPointDy 50;
BA_ "GenSigCycleTime" SG_ 738 RLR_ElkOBJ1_ObstacleProb 50;
BA_ "GenSigCycleTime" SG_ 738 RLR_ElkOBJ1_Measured 50;
BA_ "GenSigInvalidValue" SG_ 738 RLR_ElkOBJ1_Measured "0";
BA_ "GenSigCycleTime" SG_ 738 RLR_ElkOBJ1_ExistProb 50;
BA_ "GenSigInvalidValue" SG_ 738 RLR_ElkOBJ1_ExistProb "0";
BA_ "GenSigCycleTime" SG_ 738 RLR_ElkOBJ1_Location 50;
BA_ "GenSigInvalidValue" SG_ 738 RLR_ElkOBJ1_Location "0";
BA_ "GenSigCycleTime" SG_ 738 RLR_ElkOBJ1_RelAx 50;
BA_ "GenSigCycleTime" SG_ 738 RLR_ElkOBJ1_RelAy 50;
BA_ "GenSigCycleTime" SG_ 738 RLR_ElkOBJ1_RelVx 50;
BA_ "GenSigCycleTime" SG_ 738 RLR_ElkOBJ1_RelVy 50;
BA_ "GenSigCycleTime" SG_ 738 RLR_ElkOBJ1_Dx 50;
BA_ "GenSigCycleTime" SG_ 738 RLR_ElkOBJ1_RefPointLoc 50;
BA_ "GenSigCycleTime" SG_ 738 RLR_ElkOBJ1_Dy 50;
BA_ "GenSigCycleTime" SG_ 738 RLR_ElkOBJ1_HeadingAngle 50;
BA_ "GenSigCycleTime" SG_ 738 RLR_ElkOBJ1_Length 50;
BA_ "GenSigCycleTime" SG_ 738 RLR_ElkOBJ1_Height 50;
BA_ "GenSigCycleTime" SG_ 738 RLR_ElkOBJ1_Width 50;
BA_ "GenSigCycleTime" SG_ 738 RLR_ElkOBJ1_Type 50;
BA_ "GenSigInvalidValue" SG_ 738 RLR_ElkOBJ1_Type "0";
BA_ "GenSigCycleTime" SG_ 738 RLR_ElkOBJ1_Track_ID 50;
BA_ "GenSigCycleTime" SG_ 739 RLR_CRCCheck_2E3 50;
BA_ "GenSigCycleTime" SG_ 739 RLR_RollingCounter_2E3 50;
BA_ "GenSigCycleTime" SG_ 739 RLR_ElkOBJ4_Measured 50;
BA_ "GenSigInvalidValue" SG_ 739 RLR_ElkOBJ4_Measured "0";
BA_ "GenSigCycleTime" SG_ 739 RLR_ElkOBJ4_ExistProb 50;
BA_ "GenSigInvalidValue" SG_ 739 RLR_ElkOBJ4_ExistProb "0";
BA_ "GenSigCycleTime" SG_ 739 RLR_ElkOBJ4_Location 50;
BA_ "GenSigInvalidValue" SG_ 739 RLR_ElkOBJ4_Location "0";
BA_ "GenSigCycleTime" SG_ 739 RLR_ElkOBJ4_RelAx 50;
BA_ "GenSigCycleTime" SG_ 739 RLR_ElkOBJ4_RelAy 50;
BA_ "GenSigCycleTime" SG_ 739 RLR_ElkOBJ4_RelVx 50;
BA_ "GenSigCycleTime" SG_ 739 RLR_ElkOBJ4_RelVy 50;
BA_ "GenSigCycleTime" SG_ 739 RLR_ElkOBJ4_Dx 50;
BA_ "GenSigCycleTime" SG_ 739 RLR_ElkOBJ4_RefPointLoc 50;
BA_ "GenSigCycleTime" SG_ 739 RLR_ElkOBJ4_Dy 50;
BA_ "GenSigCycleTime" SG_ 739 RLR_ElkOBJ4_HeadingAngle 50;
BA_ "GenSigCycleTime" SG_ 739 RLR_ElkOBJ4_Length 50;
BA_ "GenSigCycleTime" SG_ 739 RLR_ElkOBJ4_Height 50;
BA_ "GenSigCycleTime" SG_ 739 RLR_ElkOBJ4_Width 50;
BA_ "GenSigCycleTime" SG_ 739 RLR_ElkOBJ4_Type 50;
BA_ "GenSigInvalidValue" SG_ 739 RLR_ElkOBJ4_Type "0";
BA_ "GenSigCycleTime" SG_ 739 RLR_ElkOBJ4_Track_ID 50;
BA_ "GenSigCycleTime" SG_ 739 RLR_ElkOBJ4_RefPointDx 50;
BA_ "GenSigCycleTime" SG_ 739 RLR_ElkOBJ4_RefPointDy 50;
BA_ "GenSigCycleTime" SG_ 739 RLR_ElkOBJ4_ObstacleProb 50;
BA_ "GenSigCycleTime" SG_ 739 RLR_ElkOBJ3_RefPointDx 50;
BA_ "GenSigCycleTime" SG_ 739 RLR_ElkOBJ3_RefPointDy 50;
BA_ "GenSigCycleTime" SG_ 739 RLR_ElkOBJ3_ObstacleProb 50;
BA_ "GenSigCycleTime" SG_ 739 RLR_ElkOBJ3_Measured 50;
BA_ "GenSigInvalidValue" SG_ 739 RLR_ElkOBJ3_Measured "0";
BA_ "GenSigCycleTime" SG_ 739 RLR_ElkOBJ3_ExistProb 50;
BA_ "GenSigInvalidValue" SG_ 739 RLR_ElkOBJ3_ExistProb "0";
BA_ "GenSigCycleTime" SG_ 739 RLR_ElkOBJ3_Location 50;
BA_ "GenSigInvalidValue" SG_ 739 RLR_ElkOBJ3_Location "0";
BA_ "GenSigCycleTime" SG_ 739 RLR_ElkOBJ3_RelAx 50;
BA_ "GenSigCycleTime" SG_ 739 RLR_ElkOBJ3_RelAy 50;
BA_ "GenSigCycleTime" SG_ 739 RLR_ElkOBJ3_RelVx 50;
BA_ "GenSigCycleTime" SG_ 739 RLR_ElkOBJ3_RelVy 50;
BA_ "GenSigCycleTime" SG_ 739 RLR_ElkOBJ3_Dx 50;
BA_ "GenSigCycleTime" SG_ 739 RLR_ElkOBJ3_RefPointLoc 50;
BA_ "GenSigCycleTime" SG_ 739 RLR_ElkOBJ3_Dy 50;
BA_ "GenSigCycleTime" SG_ 739 RLR_ElkOBJ3_HeadingAngle 50;
BA_ "GenSigCycleTime" SG_ 739 RLR_ElkOBJ3_Length 50;
BA_ "GenSigCycleTime" SG_ 739 RLR_ElkOBJ3_Height 50;
BA_ "GenSigCycleTime" SG_ 739 RLR_ElkOBJ3_Width 50;
BA_ "GenSigCycleTime" SG_ 739 RLR_ElkOBJ3_Type 50;
BA_ "GenSigInvalidValue" SG_ 739 RLR_ElkOBJ3_Type "0";
BA_ "GenSigCycleTime" SG_ 739 RLR_ElkOBJ3_Track_ID 50;
BA_ "GenSigCycleTime" SG_ 1304 BCM_CarMode 500;
BA_ "GenSigInvalidValue" SG_ 1304 BCM_CarMode "0";
BA_ "GenSigCycleTime" SG_ 686 LCDAL_SystemStatus 50;
BA_ "GenSigInvalidValue" SG_ 686 LCDAL_SystemStatus "7";
BA_ "GenSigStartValue" SG_ 686 LCDAL_SystemStatus 1;
BA_ "GenSigCycleTime" SG_ 985 ACC_ObsTarget10ID 100;
BA_ "GenSigCycleTime" SG_ 985 ACC_ObsTarget10Type 100;
BA_ "GenSigCycleTime" SG_ 985 ACC_ObsTarget10LatRange 100;
BA_ "GenSigStartValue" SG_ 985 ACC_ObsTarget10LatRange 1023;
BA_ "GenSigCycleTime" SG_ 985 ACC_ObsTarget10LngRange 100;
BA_ "GenSigStartValue" SG_ 985 ACC_ObsTarget10LngRange 2047;
BA_ "GenSigCycleTime" SG_ 985 ACC_ObsTarget9ID 100;
BA_ "GenSigCycleTime" SG_ 985 ACC_ObsTarget9Type 100;
BA_ "GenSigCycleTime" SG_ 985 ACC_ObsTarget9LatRange 100;
BA_ "GenSigStartValue" SG_ 985 ACC_ObsTarget9LatRange 1023;
BA_ "GenSigCycleTime" SG_ 985 ACC_ObsTarget9LngRange 100;
BA_ "GenSigStartValue" SG_ 985 ACC_ObsTarget9LngRange 2047;
BA_ "GenSigCycleTime" SG_ 985 ACC_ObsTarget8ID 100;
BA_ "GenSigCycleTime" SG_ 985 ACC_ObsTarget8Type 100;
BA_ "GenSigCycleTime" SG_ 985 ACC_ObsTarget8LatRange 100;
BA_ "GenSigStartValue" SG_ 985 ACC_ObsTarget8LatRange 1023;
BA_ "GenSigCycleTime" SG_ 985 ACC_ObsTarget8LngRange 100;
BA_ "GenSigStartValue" SG_ 985 ACC_ObsTarget8LngRange 2047;
BA_ "GenSigCycleTime" SG_ 985 ACC_ObsTarget7ID 100;
BA_ "GenSigCycleTime" SG_ 985 ACC_ObsTarget7Type 100;
BA_ "GenSigCycleTime" SG_ 985 ACC_ObsTarget7LatRange 100;
BA_ "GenSigStartValue" SG_ 985 ACC_ObsTarget7LatRange 1023;
BA_ "GenSigCycleTime" SG_ 985 ACC_ObsTarget7LngRange 100;
BA_ "GenSigStartValue" SG_ 985 ACC_ObsTarget7LngRange 2047;
BA_ "GenSigCycleTime" SG_ 985 ACC_ObsTarget6ID 100;
BA_ "GenSigCycleTime" SG_ 985 ACC_ObsTarget6Type 100;
BA_ "GenSigCycleTime" SG_ 985 ACC_ObsTarget6LatRange 100;
BA_ "GenSigStartValue" SG_ 985 ACC_ObsTarget6LatRange 1023;
BA_ "GenSigCycleTime" SG_ 985 ACC_ObsTarget6LngRange 100;
BA_ "GenSigStartValue" SG_ 985 ACC_ObsTarget6LngRange 2047;
BA_ "GenSigCycleTime" SG_ 985 ACC_ObsTarget5ID 100;
BA_ "GenSigCycleTime" SG_ 985 ACC_ObsTarget5Type 100;
BA_ "GenSigCycleTime" SG_ 985 ACC_ObsTarget5LatRange 100;
BA_ "GenSigStartValue" SG_ 985 ACC_ObsTarget5LatRange 1023;
BA_ "GenSigCycleTime" SG_ 985 ACC_ObsTarget5LngRange 100;
BA_ "GenSigStartValue" SG_ 985 ACC_ObsTarget5LngRange 2047;
BA_ "GenSigCycleTime" SG_ 985 ACC_ObsTarget4ID 100;
BA_ "GenSigCycleTime" SG_ 985 ACC_ObsTarget4Type 100;
BA_ "GenSigCycleTime" SG_ 985 ACC_ObsTarget4LatRange 100;
BA_ "GenSigStartValue" SG_ 985 ACC_ObsTarget4LatRange 1023;
BA_ "GenSigCycleTime" SG_ 985 ACC_ObsTarget4LngRange 100;
BA_ "GenSigStartValue" SG_ 985 ACC_ObsTarget4LngRange 2047;
BA_ "GenSigCycleTime" SG_ 985 ACC_ObsTarget3ID 100;
BA_ "GenSigCycleTime" SG_ 985 ACC_ObsTarget3Type 100;
BA_ "GenSigCycleTime" SG_ 985 ACC_ObsTarget3LatRange 100;
BA_ "GenSigStartValue" SG_ 985 ACC_ObsTarget3LatRange 1023;
BA_ "GenSigCycleTime" SG_ 985 ACC_ObsTarget3LngRange 100;
BA_ "GenSigStartValue" SG_ 985 ACC_ObsTarget3LngRange 2047;
BA_ "GenSigCycleTime" SG_ 985 ACC_ObsTarget2ID 100;
BA_ "GenSigCycleTime" SG_ 985 ACC_ObsTarget2Type 100;
BA_ "GenSigCycleTime" SG_ 985 ACC_ObsTarget2LatRange 100;
BA_ "GenSigStartValue" SG_ 985 ACC_ObsTarget2LatRange 1023;
BA_ "GenSigCycleTime" SG_ 985 ACC_ObsTarget2LngRange 100;
BA_ "GenSigStartValue" SG_ 985 ACC_ObsTarget2LngRange 2047;
BA_ "GenSigCycleTime" SG_ 985 ACC_ObsTarget1ID 100;
BA_ "GenSigCycleTime" SG_ 985 ACC_ObsTarget1Type 100;
BA_ "GenSigCycleTime" SG_ 985 ACC_ObsTarget1LatRange 100;
BA_ "GenSigStartValue" SG_ 985 ACC_ObsTarget1LatRange 1023;
BA_ "GenSigCycleTime" SG_ 985 ACC_ObsTarget1LngRange 100;
BA_ "GenSigStartValue" SG_ 985 ACC_ObsTarget1LngRange 2047;
BA_ "GenSigCycleTime" SG_ 987 ACC_ObsTarget20ID 100;
BA_ "GenSigCycleTime" SG_ 987 ACC_ObsTarget20Type 100;
BA_ "GenSigCycleTime" SG_ 987 ACC_ObsTarget20LatRange 100;
BA_ "GenSigStartValue" SG_ 987 ACC_ObsTarget20LatRange 1023;
BA_ "GenSigCycleTime" SG_ 987 ACC_ObsTarget20LngRange 100;
BA_ "GenSigStartValue" SG_ 987 ACC_ObsTarget20LngRange 2047;
BA_ "GenSigCycleTime" SG_ 987 ACC_ObsTarget19ID 100;
BA_ "GenSigCycleTime" SG_ 987 ACC_ObsTarget19Type 100;
BA_ "GenSigCycleTime" SG_ 987 ACC_ObsTarget19LatRange 100;
BA_ "GenSigStartValue" SG_ 987 ACC_ObsTarget19LatRange 1023;
BA_ "GenSigCycleTime" SG_ 987 ACC_ObsTarget19LngRange 100;
BA_ "GenSigStartValue" SG_ 987 ACC_ObsTarget19LngRange 2047;
BA_ "GenSigCycleTime" SG_ 987 ACC_ObsTarget18ID 100;
BA_ "GenSigCycleTime" SG_ 987 ACC_ObsTarget18Type 100;
BA_ "GenSigCycleTime" SG_ 987 ACC_ObsTarget18LatRange 100;
BA_ "GenSigStartValue" SG_ 987 ACC_ObsTarget18LatRange 1023;
BA_ "GenSigCycleTime" SG_ 987 ACC_ObsTarget18LngRange 100;
BA_ "GenSigStartValue" SG_ 987 ACC_ObsTarget18LngRange 2047;
BA_ "GenSigCycleTime" SG_ 987 ACC_ObsTarget17ID 100;
BA_ "GenSigCycleTime" SG_ 987 ACC_ObsTarget17Type 100;
BA_ "GenSigCycleTime" SG_ 987 ACC_ObsTarget17LatRange 100;
BA_ "GenSigStartValue" SG_ 987 ACC_ObsTarget17LatRange 1023;
BA_ "GenSigCycleTime" SG_ 987 ACC_ObsTarget17LngRange 100;
BA_ "GenSigStartValue" SG_ 987 ACC_ObsTarget17LngRange 2047;
BA_ "GenSigCycleTime" SG_ 987 ACC_ObsTarget16ID 100;
BA_ "GenSigCycleTime" SG_ 987 ACC_ObsTarget16Type 100;
BA_ "GenSigCycleTime" SG_ 987 ACC_ObsTarget16LatRange 100;
BA_ "GenSigStartValue" SG_ 987 ACC_ObsTarget16LatRange 1023;
BA_ "GenSigCycleTime" SG_ 987 ACC_ObsTarget16LngRange 100;
BA_ "GenSigStartValue" SG_ 987 ACC_ObsTarget16LngRange 2047;
BA_ "GenSigCycleTime" SG_ 987 ACC_ObsTarget15ID 100;
BA_ "GenSigCycleTime" SG_ 987 ACC_ObsTarget15Type 100;
BA_ "GenSigCycleTime" SG_ 987 ACC_ObsTarget15LatRange 100;
BA_ "GenSigStartValue" SG_ 987 ACC_ObsTarget15LatRange 1023;
BA_ "GenSigCycleTime" SG_ 987 ACC_ObsTarget15LngRange 100;
BA_ "GenSigStartValue" SG_ 987 ACC_ObsTarget15LngRange 2047;
BA_ "GenSigCycleTime" SG_ 987 ACC_ObsTarget14ID 100;
BA_ "GenSigCycleTime" SG_ 987 ACC_ObsTarget14Type 100;
BA_ "GenSigCycleTime" SG_ 987 ACC_ObsTarget14LatRange 100;
BA_ "GenSigStartValue" SG_ 987 ACC_ObsTarget14LatRange 1023;
BA_ "GenSigCycleTime" SG_ 987 ACC_ObsTarget14LngRange 100;
BA_ "GenSigStartValue" SG_ 987 ACC_ObsTarget14LngRange 2047;
BA_ "GenSigCycleTime" SG_ 987 ACC_ObsTarget13ID 100;
BA_ "GenSigCycleTime" SG_ 987 ACC_ObsTarget13Type 100;
BA_ "GenSigCycleTime" SG_ 987 ACC_ObsTarget13LatRange 100;
BA_ "GenSigStartValue" SG_ 987 ACC_ObsTarget13LatRange 1023;
BA_ "GenSigCycleTime" SG_ 987 ACC_ObsTarget13LngRange 100;
BA_ "GenSigStartValue" SG_ 987 ACC_ObsTarget13LngRange 2047;
BA_ "GenSigCycleTime" SG_ 987 ACC_ObsTarget12ID 100;
BA_ "GenSigCycleTime" SG_ 987 ACC_ObsTarget12Type 100;
BA_ "GenSigCycleTime" SG_ 987 ACC_ObsTarget12LatRange 100;
BA_ "GenSigStartValue" SG_ 987 ACC_ObsTarget12LatRange 1023;
BA_ "GenSigCycleTime" SG_ 987 ACC_ObsTarget12LngRange 100;
BA_ "GenSigStartValue" SG_ 987 ACC_ObsTarget12LngRange 2047;
BA_ "GenSigCycleTime" SG_ 987 ACC_ObsTarget11ID 100;
BA_ "GenSigCycleTime" SG_ 987 ACC_ObsTarget11Type 100;
BA_ "GenSigCycleTime" SG_ 987 ACC_ObsTarget11LatRange 100;
BA_ "GenSigStartValue" SG_ 987 ACC_ObsTarget11LatRange 1023;
BA_ "GenSigCycleTime" SG_ 987 ACC_ObsTarget11LngRange 100;
BA_ "GenSigStartValue" SG_ 987 ACC_ObsTarget11LngRange 2047;
VAL_ 999 BCM_Status_Temp 0 "No error" 1 "not used" 2 "HW defect (ADC defect)" 3 "LIN saturation (no HW  defect)" ;
VAL_ 999 BCM_T_BATT 146 "reserved" 255 "Invalid" ;
VAL_ 1021 BCM_DriveMode 0 "Normal" 1 "Eco" 2 "Sport  " 3 "Snow" 4 "Sport+" 5 "Smart" 6 "Race" 7 "Reserved" 15 "Invalid" ;
VAL_ 1021 BCM_PowerManageLevel 0 "Valid" 1 "Level1" 2 " Level2" 3 " Level3" 4 " Level4" 5 "Reserve" 7 "Invalid" ;
VAL_ 1310 TPMS_TirePosition 0 "No any sensor" 1 "Left Front tire.
0x2=Right Front tire" 3 "Right Rear tire.
0x4=Left Rear tire" 5 "reseved." ;
VAL_ 1374 ADS_FCEventCode 0 "inactive" 1 "事件0~事件1023" ;
VAL_ 1374 ADS_FCEventAmount 0 "0~127" ;
VAL_ 1374 ADS_FCEventStartEndIdentify 0 "End" 1 "Start" ;
VAL_ 1374 ADS_FCEID 0 "0~255" ;
VAL_ 1374 ADS_FCControllerCode 0 "inactive" 1 "ADS" 2 "APA" 3 "GW" 4 "HPP" 5 "FC" 6 "Reserved" ;
VAL_ 652 GW_MFS_handsoffDetectResult 0 "no Touch" 1 "Left Wheel Touch" 2 "Right Wheel Touch" 3 "Rear Wheel Touch" 4 "Left Wheel Grip" 5 "Right Wheel Grip" 6 "Both side touch" 7 " Both side Grip" ;
VAL_ 652 GW_MFS_DiagInfoSW_28C 0 "复位" 1 "变种信息错误" 2 "电源高于16V" 3 "电源低于9V" 4 "reversed" 7 "invalid" ;
VAL_ 652 GW_MFS_IACCenable_switch_signal 0 "按键未按下" 1 "按键按下" 2 "假按键" 3 "Error" ;
VAL_ 652 GW_MFS_DIST_switch_signal 0 "按键未按下" 1 "按键按下" 2 "假按键" 3 "Error" ;
VAL_ 652 GW_MFS_SETReduce_switch_signal 0 "按键未按下" 1 "按键按下" 2 "假按键" 3 "Error" ;
VAL_ 652 GW_MFS_RESPlus_switch_signal 0 "按键未按下" 1 "按键按下" 2 "假按键" 3 "Error" ;
VAL_ 652 GW_MFS_Cancle_switch_signal 0 "按键未按下" 1 "按键按下" 2 "假按键" 3 "Error" ;
VAL_ 652 GW_MFS_Crusie_switch_signal 0 "按键未按下" 1 "按键按下" 2 "假按键" 3 "Error" ;
VAL_ 652 GW_MFS_DISTReduce_switch_signal 0 "按键未按下
0x1=按键按下
0x2=假按键
0x3=Error" ;
VAL_ 652 GW_MFS_DISTPlus_switch_signal 0 "按键未按下
0x1=按键按下
0x2=假按键
0x3=Error" ;
VAL_ 1426 LAS_NotSleep_BYTE7BIT1 0 "Inactive" 1 " IGN硬线信号为ON档/总线电源挡位信号非OFF" ;
VAL_ 1426 LAS_NotSleep_BYTE7BIT0 0 "Inactive" 1 " CAN网络上其他节点不允许休眠" ;
VAL_ 1426 LAS_WakeUp_BYTE4BIT1 0 "Inactive" 1 " IG唤醒（若不接IG硬线则无此位）" ;
VAL_ 1426 LAS_WakeUp_BYTE4BIT0 0 "Inactive" 1 " CAN网络管理报文唤醒" ;
VAL_ 1428 FR_NotSleep_BYTE7BIT1 0 "Inactive" 1 " IGN硬线信号为ON档/总线电源挡位信号非OFF" ;
VAL_ 1428 FR_NotSleep_BYTE7BIT0 0 "Inactive" 1 " CAN网络上其他节点不允许休眠" ;
VAL_ 1428 FR_WakeUp_BYTE4BIT1 0 "Inactive" 1 " IG唤醒（若不接IG硬线则无此位）" ;
VAL_ 1428 FR_WakeUp_BYTE4BIT0 0 "Inactive" 1 " CAN网络管理报文唤醒" ;
VAL_ 80 SRS_WarningLampStatus 0 "Lamp off" 1 "Lamp on" 2 "Lamp Flashing" 3 "Not Used" ;
VAL_ 80 SRS_DriverBuckleSwitchStatus 0 "Buckled" 1 "Unbuckle " 2 "Not Used" 3 "Not Used
Default value: 0x0" ;
VAL_ 80 SRS_CrashOutputStatusCheckSum 0 "(SRS_CrashOutputStatus) XOR 0xF" ;
VAL_ 80 SRS_CrashOutputStatus 0 "No Crash" 1 "crash " 2 "Not Used" ;
VAL_ 80 SRS_CRCCheck_50 0 "0xFF，XOR value=0xFF，input data reflected=No，Result data reflected=No，check=0x48，Magic check=0xC4）" ;
VAL_ 898 ACC_LaneEquationStatus 0 "no display" 1 "Left Lane" 2 "Right Lane" 3 "reserved" ;
VAL_ 898 ACC_LaneEquationC3 0 "C0+C1*x+(1/2)*C2*x^2+(1/6)*C3*x^3，其中C3为车道线曲率变化率，换算公式为(-2047 + (0x0 ~ 0xFFE))*2^(-21))" ;
VAL_ 898 ACC_LaneEquationC2 0 "C0+C1*x+(1/2)*C2*x^2+(1/6)*C3*x^3，其中C2为车道线曲率，换算公式为(-2047 + (0x0 ~ 0xFFE))*2^(-16))" ;
VAL_ 898 ACC_LaneEquationC1 0 "C0+C1*x+(1/2)*C2*x^2+(1/6)*C3*x^3，其中C1为车辆相对预期轨迹的角度，换算公式为-1+(0x0 ~ 0xFFE)*2^(-11))" ;
VAL_ 898 ACC_LaneQuality 0 "" ;
VAL_ 898 ACC_FRTarget2Type 0 "no display" 1 "sedan" 2 "motorcycle" 3 "pedestrian" 4 "Bicycle" 5 "Bus" 6 "van" 7 "truck" 8 "reserved" 15 "other" ;
VAL_ 898 ACC_FRTarget2LatRange 0 "" 1001 "" ;
VAL_ 898 ACC_FRTarget2LngRange 0 "-70~180" 501 "reserved" 511 "no display" ;
VAL_ 898 ACC_FRTarget2Detection 0 "not dectected" 1 "IP display" 2 "Front Target" 3 "IACC target" 4 "AEB target" 5 "dangerous target（ELK、UDLC、RCW, etc）" 6 "reserved" ;
VAL_ 898 ACC_FRTarget2Direction 0 "Forward" 1 "OnComing" 2 "Left" 3 "Right" 4 "unknown" 5 "no display" 6 "reserved" ;
VAL_ 898 ACC_FRTarget1Direction 0 "Forward" 1 "OnComing" 2 "Left" 3 "Right" 4 "unknown" 5 "no display" 6 "reserved" ;
VAL_ 898 ACC_FRTarget1Type 0 "no display" 1 "sedan" 2 "motorcycle" 3 "pedestrian" 4 "Bicycle" 5 "Bus" 6 "van" 7 "truck" 8 "reserved" 15 "other" ;
VAL_ 898 ACC_FRTarget1LatRange 0 "" 1001 "" ;
VAL_ 898 ACC_FRTarget1LngRange 0 "-70~180" 501 "reserved" 511 "no display" ;
VAL_ 898 ACC_FRTarget1Detection 0 "not dectected" 1 "IP display" 2 "Front Target" 3 "IACC target" 4 "AEB target" 5 "dangerous target（ELK、UDLC、RCW, etc）" 6 "reserved" ;
VAL_ 898 ACC_FLTarget2LatRange 0 "" 1001 "" ;
VAL_ 391 ESP_ABSFailStatus 0 "Noerror" 1 "Error" ;
VAL_ 391 ESP_ESPFunctionStatus 0 "OFF" 1 "ON" ;
VAL_ 391 ESP_TCSFailStatus 0 "Noerror" 1 "Error" ;
VAL_ 391 ESP_VehicleSpeed 0 "0~360km/h" 6401 "Reserved" 8191 "Invalid
APA2.0接收" ;
VAL_ 391 ESP_VehicleSpeedValid 0 "Valid" 1 "NotValid" ;
VAL_ 391 ESP_ESPActiveStatus 0 "NotActive" 1 "Active" ;
VAL_ 391 ESP_EngTorqIncActive 0 "NotActive" 1 "Active" ;
VAL_ 391 ESP_EngTorqDecActive 0 "NotActive" 1 "Active" ;
VAL_ 391 ESP_ABSActiveStatus 0 "NotActive" 1 "Active" ;
VAL_ 407 EPB_SwitchPosition 0 "no request" 1 "Release request" 2 "Apply request" 3 "Error" ;
VAL_ 407 EPB_SwitchPositionValid 0 "valid _full function" 1 "error, init or substitute value (no function)" ;
VAL_ 407 EPB_FailStatus 0 "no error in EPB – external apply available" 1 "not defined" 2 "not defined" 3 "error in EPB – no external apply allowed" ;
VAL_ 407 EPB_AchievedClampForce 0 "ClampForce" 30 "Reserved" 31 "Error" ;
VAL_ 407 EPB_Status 0 "both brakes released" 1 "both brakes applied" 2 "both brakes in operation (applying/releasing)" 3 "unknown" ;
VAL_ 523 ESP_Vehicle_Speed_Reference 0 "0~360km/h" 6401 "Reserved" 8191 "Invalid" ;
VAL_ 523 Wheel_Speed_RR_Valid_Data 0 "Valid" 1 "NotValid" ;
VAL_ 523 Wheel_Speed_RR_Direction 0 "Forward" 1 "backward" 2 "Standstill" 3 "Invalid" ;
VAL_ 523 Wheel_Speed_RL_Valid_Data 0 "Valid" 1 "NotValid" ;
VAL_ 523 Wheel_Speed_RL_Direction 0 "Forward" 1 "backward" 2 "Standstill" 3 "Invalid" ;
VAL_ 523 Wheel_Speed_FR_Valid_Data 0 "Valid" 1 "NotValid" ;
VAL_ 523 Wheel_Speed_FR_Direction 0 "Forward" 1 "backward" 2 "Standstill" 3 "Invalid" ;
VAL_ 523 Wheel_Speed_FL_Valid_Data 0 "Valid" 1 "NotValid" ;
VAL_ 523 Wheel_Speed_FL_Direction 0 "Forward" 1 "backward" 2 "Standstill" 3 "Invalid" ;
VAL_ 523 ESP_VehicleStandstill 0 "notstandstill" 1 "standstill" ;
VAL_ 523 ESP_VDCActive 0 "NotActive" 1 "Active" ;
VAL_ 523 ESP_TCSActive 0 "NotActive" 1 "Active" ;
VAL_ 523 ESP_QDCACC 0 "noerror" 1 "error" 2 "reserved" 3 "reserved" ;
VAL_ 523 ESP_PrefillAvailable 0 "notavailable" 1 "available" ;
VAL_ 523 ESP_PrefillActive 0 "notactive" 1 "active" ;
VAL_ 523 ESP_OnlyABSActive 0 "NotActive" 1 "Active" ;
VAL_ 523 ESP_MasCylBrakePressureValid 0 "Valid" 1 "Invalid" ;
VAL_ 523 ESP_HDC_STATUS 0 "OFF" 1 "ON" 2 "Standby" 3 "Error" ;
VAL_ 523 ESP_CDD_Available 0 "notavailable" 1 "available" ;
VAL_ 523 ESP_CDD_Active 0 "notactive" 1 "active" ;
VAL_ 523 ESP_BrakeOverHeatBrakeDiscTemp 0 "nothigh" 1 "temptoohigh" ;
VAL_ 523 ESP_BrakeForce 0 "nobrakeforce" 1 "havebrakeforce" ;
VAL_ 523 ESP_AWBavailable 0 "notavailable" 1 "available" ;
VAL_ 523 ESP_AWBactive 0 "notactive" 1 "active" ;
VAL_ 523 ESP_AEBdecActive 0 "notactive" 1 "active" ;
VAL_ 523 ESP_AEBAvailable 0 "notavailable" 1 "available" ;
VAL_ 523 ESP_ABAavailable 0 "notavailable" 1 "available" ;
VAL_ 523 ESP_ABAactive 0 "notactive" 1 "active" ;
VAL_ 734 IP_DISFail 0 "no error" 1 "error" ;
VAL_ 734 IP_QDashACCFail 0 "no error" 1 "error" 2 "reserved" 3 "reserved" ;
VAL_ 947 BCM_BrakeLampError 0 "无故障" 1 "有故障" ;
VAL_ 947 BCM_RearFoglampStatus 0 "OFF" 1 "ON" 2 "Not used" 3 "Error" ;
VAL_ 1023 BCM_RightLowBeamError 0 "无故障" 1 "有故障" ;
VAL_ 1023 BCM_LeftLowBeamError 0 "无故障" 1 "有故障" ;
VAL_ 1023 BCM_AutoHeadlightSts 0 "Not Actived" 1 "Actived" ;
VAL_ 1023 BCM_FrontFoglampStatus 0 "OFF" 1 "ON" 2 "Not used" 3 "Reserved" ;
VAL_ 632 ESP_YawRateValid 0 "Valid" 1 "Invalid" ;
VAL_ 384 SAS_SASFailure 0 "No Failure" 1 "Failure" ;
VAL_ 384 SAS_Calibrated 0 "Calibrated" 1 " Not Calibrated" ;
VAL_ 384 SAS_SteeringAngleValid 0 "Valid " 1 "Invalid" ;
VAL_ 424 TCU_FastOnMode 0 "Off" 1 "On" ;
VAL_ 424 TCU_ActualGear 0 "Neutral" 1 "1stgear" 2 "2ndgear" 3 "3rdgear" 4 "4tgear" 5 "5tgear" 6 "6tgear" 7 "7tgear" 8 "8tgear" 9 "Reverse" 10 "Parking" 11 "Reserved" 12 "Reserved" 13 "Reserved" 14 "Reserved" 15 "Invalid" ;
VAL_ 424 TCU_ActualGearValid 0 "Valid" 1 "Invalid" ;
VAL_ 424 TCU_GearShiftPosition 0 "Parking" 1 "Reverse" 2 "Neutral" 3 "D" 4 "D3" 5 "D2" 6 "L" 7 "M_or_S" 8 "Reserved" 9 "Reserved" 10 "Reserved" 11 "Reserved" 12 "Reserved" 13 "Reserved" 14 "Unreliable" 15 "Invalid" ;
VAL_ 424 TCU_ShiftPostionValid 0 "Valid" 1 "Invalid" ;
VAL_ 424 TCU_TransFailureStatus 0 "Normal" 1 "Failwithoutlimphomemode" 2 "Failwithlimphomemode" 3 "undefine" ;
VAL_ 784 AMP_AllAlarmFailureStatus 0 "No Failure" 1 "Failure" ;
VAL_ 784 AMP_IPEnableAlarmFailureStatus 0 "No Failure" 1 "Failure" ;
VAL_ 790 LAS_Line_04_MeasureType_FT 0 "unknow" 1 "virtual_paral" 2 "measured_paral" 3 "virtual" 4 "measured" ;
VAL_ 790 LAS_Line_03_MeasureType_FT 0 "unknow" 1 "virtual_paral" 2 "measured_paral" 3 "virtual" 4 "measured" ;
VAL_ 790 LAS_Line_02_MeasureType_FT 0 "unknow" 1 "virtual_paral" 2 "measured_paral" 3 "virtual" 4 "measured" ;
VAL_ 790 LAS_Line_01_MeasureType_FT 0 "unknow" 1 "virtual_paral" 2 "measured_paral" 3 "virtual" 4 "measured" ;
VAL_ 790 LAS_Line_03_MeasureType 0 "unknown" 1 "Virtual" 2 "Measured" ;
VAL_ 790 LAS_Line_03_color 0 "Not Detected" 1 "white" 2 "yellow" 3 "white plus yellow" 4 "unknown" 5 "reserved" 7 "Invalid" ;
VAL_ 790 LAS_Line_03_Type 0 " solid" 1 "dashed" 2 "double_dashed_dashed" 3 "double_dashed_solid" 4 "double_ solid_ dashed" 5 "double_ solid_ solid" 6 " multiple（Eu&USA）" 7 "multiple_warning（Eu&USA）" 8 "car_pool" 9 "asphalt_joint（USA）" 10 "Bot-Dott（USA）" 11 " road_edge" 12 "guardrail" 13 "curbstone" 14 "wall" 15 "traffic_cone" 16 "delineator_post" 17 "parking_car" 18 "unknown_raised" 19 "fishbone" 20 "unknown" 21 "reserved" ;
VAL_ 790 LAS_Line_02_MeasureType 0 "unknown" 1 "Virtual" 2 "Measured" ;
VAL_ 790 LAS_Line_02_color 0 "Not Detected" 1 "white" 2 "yellow" 3 "white plus yellow" 4 "unknown" 5 "reserved" 7 "Invalid" ;
VAL_ 790 LAS_Line_02_Type 0 " solid" 1 "dashed" 2 "double_dashed_dashed" 3 "double_dashed_solid" 4 "double_ solid_ dashed" 5 "double_ solid_ solid" 6 " multiple（Eu&USA）" 7 "multiple_warning（Eu&USA）" 8 "car_pool" 9 "asphalt_joint（USA）" 10 "Bot-Dott（USA）" 11 " road_edge" 12 "guardrail" 13 "curbstone" 14 "wall" 15 "traffic_cone" 16 "delineator_post" 17 "parking_car" 18 "unknown_raised" 19 "fishbone" 20 "unknown" 21 "reserved" ;
VAL_ 790 LAS_Line_01_MeasureType 0 "unknown" 1 "Virtual" 2 "Measured" ;
VAL_ 790 LAS_Line_01_color 0 "Not Detected" 1 "white" 2 "yellow" 3 "white plus yellow" 4 "unknown" 5 "reserved" 7 "Invalid" ;
VAL_ 790 LAS_Line_01_Type 0 " solid" 1 "dashed" 2 "double_dashed_dashed" 3 "double_dashed_solid" 4 "double_ solid_ dashed" 5 "double_ solid_ solid" 6 " multiple（Eu&USA）" 7 "multiple_warning（Eu&USA）" 8 "car_pool" 9 "asphalt_joint（USA）" 10 "Bot-Dott（USA）" 11 " road_edge" 12 "guardrail" 13 "curbstone" 14 "wall" 15 "traffic_cone" 16 "delineator_post" 17 "parking_car" 18 "unknown_raised" 19 "fishbone" 20 "unknown" 21 "reserved" ;
VAL_ 800 GW_ResetReq 0 "Valid" 1 "THU" 2 " AMP" 3 "ADS/ADC" 4 " FC/LAS" 5 "FR/ACC" 6 "FLR" 7 "FRR" 8 "RLR/LCDAL" 9 "RRR/LCDAR" 10 "LVSM" 11 "INS" 12 "APA" 13 "BCML/BCM" 14 "GW/BCMR" 15 "EMS" 16 "PCU" 17 "BMS" 18 "PEU" 19 "OBC" 20 "TCU" 21 "IPUMP" 22 "ACM" 23 "ESL" 24 "PTS" 25 "ESCL" 26 "TMS/AC" 27 "DKC/RFBT/BLEM" 28 "WLCM" 29 "EPBI" 30 "IBCU" 31 "RBM" 32 "EPS" 33 "EPS2" 34 "DSM" 35 "IP" 36 "SLCM" 37 "HUD" 38 "Reserve" 127 "Invalid" ;
VAL_ 822 LAS_Line_06_MeasureType_FT 0 "unknow" 1 "virtual_paral" 2 "measured_paral" 3 "virtual" 4 "measured" ;
VAL_ 822 LAS_Line_05_MeasureType_FT 0 "unknow" 1 "virtual_paral" 2 "measured_paral" 3 "virtual" 4 "measured" ;
VAL_ 822 LAS_Line_06_MeasureType 0 "unknown" 1 "Virtual" 2 "Measured" ;
VAL_ 822 LAS_Line_06_color 0 "Not Detected" 1 "white" 2 "yellow" 3 "white plus yellow" 4 "unknown" 5 "reserved" 7 "Invalid" ;
VAL_ 822 LAS_Line_06_Type 0 " solid" 1 "dashed" 2 "double_dashed_dashed" 3 "double_dashed_solid" 4 "double_ solid_ dashed" 5 "double_ solid_ solid" 6 " multiple（Eu&USA）" 7 "multiple_warning（Eu&USA）" 8 "car_pool" 9 "asphalt_joint（USA）" 10 "Bot-Dott（USA）" 11 " road_edge" 12 "guardrail" 13 "curbstone" 14 "wall" 15 "traffic_cone" 16 "delineator_post" 17 "parking_car" 18 "unknown_raised" 19 "fishbone" 20 "unknown" 21 "reserved" ;
VAL_ 822 LAS_Line_05_MeasureType 0 "unknown" 1 "Virtual" 2 "Measured" ;
VAL_ 822 LAS_Line_05_color 0 "Not Detected" 1 "white" 2 "yellow" 3 "white plus yellow" 4 "unknown" 5 "reserved" 7 "Invalid" ;
VAL_ 822 LAS_Line_05_Type 0 " solid" 1 "dashed" 2 "double_dashed_dashed" 3 "double_dashed_solid" 4 "double_ solid_ dashed" 5 "double_ solid_ solid" 6 " multiple（Eu&USA）" 7 "multiple_warning（Eu&USA）" 8 "car_pool" 9 "asphalt_joint（USA）" 10 "Bot-Dott（USA）" 11 " road_edge" 12 "guardrail" 13 "curbstone" 14 "wall" 15 "traffic_cone" 16 "delineator_post" 17 "parking_car" 18 "unknown_raised" 19 "fishbone" 20 "unknown" 21 "reserved" ;
VAL_ 822 LAS_Line_04_MeasureType 0 "unknown" 1 "Virtual" 2 "Measured" ;
VAL_ 822 LAS_Line_04_color 0 "Not Detected" 1 "white" 2 "yellow" 3 "white plus yellow" 4 "unknown" 5 "reserved" 7 "Invalid" ;
VAL_ 822 LAS_Line_04_Type 0 " solid" 1 "dashed" 2 "double_dashed_dashed" 3 "double_dashed_solid" 4 "double_ solid_ dashed" 5 "double_ solid_ solid" 6 " multiple（Eu&USA）" 7 "multiple_warning（Eu&USA）" 8 "car_pool" 9 "asphalt_joint（USA）" 10 "Bot-Dott（USA）" 11 " road_edge" 12 "guardrail" 13 "curbstone" 14 "wall" 15 "traffic_cone" 16 "delineator_post" 17 "parking_car" 18 "unknown_raised" 19 "fishbone" 20 "unknown" 21 "reserved" ;
VAL_ 683 FC_AEBOBJ_fusion_Sts 0 "undefined" 1 "fusion" 2 "carmera only" 3 "radar only" ;
VAL_ 683 FC_AEBOBJ_Brakelight_Info 0 "off" 1 "on" ;
VAL_ 683 FC_AEBOBJ_Taillight_Info 0 "off" 1 "left" 2 "right" 3 "left and right" 4 "invalid" 5 "reserved" ;
VAL_ 683 FC_AEBOBJ_Class 0 "Not Detected" 1 "car" 2 "truck" 3 "bicycle/motorbike" 4 "pedestrian" 5 "general" 6 "animal" 7 "uncertain" ;
VAL_ 711 FRC_TiOut 0 "no timeout" 1 "timeout" ;
VAL_ 711 FRC_FCTBStatus 0 "OFF(关闭)" 1 "Inactive(未激活)" 2 "Active" 3 "Failure" ;
VAL_ 711 FRC_FCTAEnable 0 "off" 1 "on" ;
VAL_ 711 FRC_PrefillActive 0 " not Active" 1 " Active" ;
VAL_ 711 FRC_SystemStatus 0 "Reserved" 1 "StartUp" 2 "Running" 3 "Blocked" 4 "Calibration" 5 "ShutDown" 6 "Hot" 7 "Failure" ;
VAL_ 711 FRC_Right_FCTARStatus 0 "OFF(关闭)" 1 "Inactive(未激活)" 2 "Active" 3 "Failure" ;
VAL_ 711 FRC_Right_FCTARAlert 0 "No FCTA warning" 1 "FCTA warning Level1" 2 "FCTA warning Level2" 3 "FCTA warning Level3" ;
VAL_ 711 FRC_Left_FCTALAlert 0 "No FCTA warning" 1 "FCTA warning Level1" 2 "FCTA warning Level2" 3 "FCTA warning Level3" ;
VAL_ 711 FRC_FCTBActive 0 " not Active" 1 " Active." ;
VAL_ 711 FRC_FCTBEnable 0 "off" 1 "on" ;
VAL_ 747 FC_FrFrOBJ_fusion_Sts 0 "undefined" 1 "fusion" 2 "carmera only" 3 "radar only" ;
VAL_ 747 FC_FrFrOBJ_Brakelight_Info 0 "off" 1 "on" ;
VAL_ 747 FC_FrFrOBJ_Taillight_Info 0 "off" 1 "left" 2 "right" 3 "left and right" 4 "invalid" 5 "reserved" ;
VAL_ 747 FC_FrFrOBJ_Class 0 "Not Detected" 1 "car" 2 "truck" 3 "bicycle/motorbike" 4 "pedestrian" 5 "general" 6 "animal" 7 "uncertain" ;
VAL_ 747 FC_FrOBJ_fusion_Sts 0 "undefined" 1 "fusion" 2 "carmera only" 3 "radar only" ;
VAL_ 747 FC_FrOBJ_Brakelight_Info 0 "off" 1 "on" ;
VAL_ 747 FC_FrOBJ_Taillight_Info 0 "off" 1 "left" 2 "right" 3 "left and right" 4 "invalid" 5 "reserved" ;
VAL_ 747 FC_FrOBJ_Class 0 "Not Detected" 1 "car" 2 "truck" 3 "bicycle/motorbike" 4 "pedestrian" 5 "general" 6 "animal" 7 "uncertain" ;
VAL_ 750 FC_LeFrOBJ_fusion_Sts 0 "undefined" 1 "fusion" 2 "carmera only" 3 "radar only" ;
VAL_ 750 FC_LeFrOBJ_Brakelight_Info 0 "off" 1 "on" ;
VAL_ 750 FC_LeFrOBJ_Taillight_Info 0 "off" 1 "left" 2 "right" 3 "left and right" 4 "invalid" 5 "reserved" ;
VAL_ 750 FC_LeFrOBJ_Class 0 "Not Detected" 1 "car" 2 "truck" 3 "bicycle/motorbike" 4 "pedestrian" 5 "general" 6 "animal" 7 "uncertain" ;
VAL_ 750 FC_LeOBJ_fusion_Sts 0 "undefined" 1 "fusion" 2 "carmera only" 3 "radar only" ;
VAL_ 750 FC_LeOBJ_Brakelight_Info 0 "off" 1 "on" ;
VAL_ 750 FC_LeOBJ_Taillight_Info 0 "off" 1 "left" 2 "right" 3 "left and right" 4 "invalid" 5 "reserved" ;
VAL_ 750 FC_LeOBJ_Class 0 "Not Detected" 1 "car" 2 "truck" 3 "bicycle/motorbike" 4 "pedestrian" 5 "general" 6 "animal" 7 "uncertain" ;
VAL_ 756 FC_RiFrOBJ_fusion_Sts 0 "undefined" 1 "fusion" 2 "carmera only" 3 "radar only" ;
VAL_ 756 FC_RiFrOBJ_Brakelight_Info 0 "off" 1 "on" ;
VAL_ 756 FC_RiFrOBJ_Taillight_Info 0 "off" 1 "left" 2 "right" 3 "left and right" 4 "invalid" 5 "reserved" ;
VAL_ 756 FC_RiFrOBJ_Class 0 "Not Detected" 1 "car" 2 "truck" 3 "bicycle/motorbike" 4 "pedestrian" 5 "general" 6 "animal" 7 "uncertain" ;
VAL_ 756 FC_RiOBJ_fusion_Sts 0 "undefined" 1 "fusion" 2 "carmera only" 3 "radar only" ;
VAL_ 756 FC_RiOBJ_Brakelight_Info 0 "off" 1 "on" ;
VAL_ 756 FC_RiOBJ_Taillight_Info 0 "off" 1 "left" 2 "right" 3 "left and right" 4 "invalid" 5 "reserved" ;
VAL_ 756 FC_RiOBJ_Class 0 "Not Detected" 1 "car" 2 "truck" 3 "bicycle/motorbike" 4 "pedestrian" 5 "general" 6 "animal" 7 "uncertain" ;
VAL_ 906 GW_MFS_SeekReduce_switch 0 "按键未按下" 1 "按键按下" 2 "假按键" 3 "Error" ;
VAL_ 906 GW_MFS_Answer_switch_signal 0 "按键未按下" 1 "按键按下" 2 "假按键" 3 "Error" ;
VAL_ 906 GW_MFS_Hungup_switch_signal 0 "按键未按下" 1 "按键按下" 2 "假按键" 3 "Error" ;
VAL_ 906 GW_MFS_SeekPlus_switch 0 "按键未按下" 1 "按键按下" 2 "假按键" 3 "Error" ;
VAL_ 906 GW_MFS_Mute_switch 0 "按键未按下" 1 "按键按下" 2 "假按键" 3 "Error" ;
VAL_ 906 GW_MFS_VolReduce_switch 0 "按键未按下" 1 "按键按下" 2 "假按键" 3 "Error" ;
VAL_ 906 GW_MFS_VolPlus_switch 0 "按键未按下" 1 "按键按下" 2 "假按键" 3 "Error" ;
VAL_ 906 GW_MFS_Speech_switch 0 "按键未按下" 1 "按键按下" 2 "假按键" 3 "Error" ;
VAL_ 906 GW_MFS_OK_switch 0 "按键未按下" 1 "按键按下" 2 "假按键" 3 "Error" ;
VAL_ 906 GW_MFS_Down_switch 0 "按键未按下" 1 "按键按下" 2 "假按键" 3 "Error" ;
VAL_ 906 GW_MFS_UP_switch 0 "按键未按下" 1 "按键按下" 2 "假按键" 3 "Error" ;
VAL_ 906 GW_MFS_Right_switch 0 "按键未按下" 1 "按键按下" 2 "假按键" 3 "Error" ;
VAL_ 906 GW_MFS_Left_switch 0 "按键未按下" 1 "按键按下" 2 "假按键" 3 "Error" ;
VAL_ 1000 BCM_SOF_Q_STATE 0 "deviation > 15%" 1 "deviation <15%" 2 "deviation < 10%" 3 "invalid" ;
VAL_ 1000 BCM_SOF_Q 255 "Invalid" ;
VAL_ 723 ACC_CRCCheck_283 0 "0xFF，XOR value=0xFF，input data reflected=No，Result data reflected=No，check=0x48，Magic check=0xC4）" ;
VAL_ 723 ACC_AEBTargetLatRange_for_SRS 0 "-50-50m
0x3E9-0x3FF=reserved" ;
VAL_ 723 ACC_CRCCheckr_282 0 "0xFF，XOR value=0xFF，input data reflected=No，Result data reflected=No，check=0x48，Magic check=0xC4）" ;
VAL_ 723 ACC_AEBTargetType_for_SRS 0 "no display
0x1=sedan
0x2=motorcycle" 3 "pedestrian" 4 "Bicycle" 5 "Bus" 6 "reserved" 7 "truck" 8 "reserved" 15 "other" ;
VAL_ 723 ACC_AEBTargetTTC_for_SRS 0 "0.01~2.50
0xFA =Time to Impact more than 2.5s and valid
0xFB=Timeout
0xFC~0xFD=reserve
0xFE=Invaild" ;
VAL_ 723 ACC_AEBTargetRelSpeed_for_SRS 0 "-250-250
0x1F5-0x1FF=reserved" ;
VAL_ 723 ACC_AEBTargetLngRange_for_SRS 0 "-70~180" 501 "reserved" 511 "no display" ;
VAL_ 723 ACC_AEBActive_for_SRS 0 "not Active" 1 "Active" ;
VAL_ 723 ACC_AEBStatus_for_SRS 0 "off" 1 "on" 2 " reserved" 3 "failure" ;
VAL_ 780 LAS_ResetSts 0 "Valid" 1 "GW请求复位" 2 "自身判断复位" 3 "不满足复位条件" 4 "Reserve" 7 "Invalid" ;
VAL_ 738 RLR_ElkOBJ2_Measured 0 "unknown" 1 "Measured" 2 "Predicted" 3 "Reserved" ;
VAL_ 738 RLR_ElkOBJ2_Location 0 "unknown" 1 "Left Lane" 2 "Right  Lane" 3 "Ego Lane" ;
VAL_ 738 RLR_ElkOBJ2_Type 0 "Not Detected" 1 "car" 2 "truck" 3 "bicycle/motorbike" 4 "pedestrian" 5 "general" 6 "animal" 7 "uncertain" ;
VAL_ 738 RLR_ElkOBJ1_Measured 0 "unknown" 1 "Measured" 2 "Predicted" 3 "Reserved" ;
VAL_ 738 RLR_ElkOBJ1_Location 0 "unknown" 1 "Left Lane" 2 "Right  Lane" 3 "Ego Lane" ;
VAL_ 738 RLR_ElkOBJ1_Type 0 "Not Detected" 1 "car" 2 "truck" 3 "bicycle/motorbike" 4 "pedestrian" 5 "general" 6 "animal" 7 "uncertain" ;
VAL_ 739 RLR_ElkOBJ4_Measured 0 "unknown" 1 "Measured" 2 "Predicted" 3 "Reserved" ;
VAL_ 739 RLR_ElkOBJ4_Location 0 "unknown" 1 "Left Lane" 2 "Right  Lane" 3 "Ego Lane" ;
VAL_ 739 RLR_ElkOBJ4_Type 0 "Not Detected" 1 "car" 2 "truck" 3 "bicycle/motorbike" 4 "pedestrian" 5 "general" 6 "animal" 7 "uncertain" ;
VAL_ 739 RLR_ElkOBJ3_Measured 0 "unknown" 1 "Measured" 2 "Predicted" 3 "Reserved" ;
VAL_ 739 RLR_ElkOBJ3_Location 0 "unknown" 1 "Left Lane" 2 "Right  Lane" 3 "Ego Lane" ;
VAL_ 739 RLR_ElkOBJ3_Type 0 "Not Detected" 1 "car" 2 "truck" 3 "bicycle/motorbike" 4 "pedestrian" 5 "general" 6 "animal" 7 "uncertain" ;
VAL_ 1304 BCM_CarMode 0 "车辆处于用户模式 " 1 " 车辆处于工厂模式" 2 "车辆处于运输模式" 3 " Reserved" ;
VAL_ 686 LCDAL_SystemStatus 0 "Reserved" 1 "StartUp" 2 "Running" 3 "Blocked" 4 "Calibration" 5 "ShutDown" 6 "Hot" 7 "Failure" ;
VAL_ 985 ACC_ObsTarget10ID 0 "not detect" 1 "1~30" 31 "invalid" ;
VAL_ 985 ACC_ObsTarget10Type 0 "no display" 1 "Cone Consideration" 2 "Warning Column" 3 "Water Horse" 4 "Anti-Collision Bucket" 5 "Emergancy Triangles" 6 "others" 7 "reserved" ;
VAL_ 985 ACC_ObsTarget10LatRange 0 "-50~50" 1001 "reserved" ;
VAL_ 985 ACC_ObsTarget10LngRange 0 "-20~120" 1401 "reserved" ;
VAL_ 985 ACC_ObsTarget9ID 0 "not detect" 1 "1~30" 31 "invalid" ;
VAL_ 985 ACC_ObsTarget9Type 0 "no display" 1 "Cone Consideration" 2 "Warning Column" 3 "Water Horse" 4 "Anti-Collision Bucket" 5 "Emergancy Triangles" 6 "others" 7 "reserved" ;
VAL_ 985 ACC_ObsTarget9LatRange 0 "-50~50" 1001 "reserved" ;
VAL_ 985 ACC_ObsTarget9LngRange 0 "-20~120" 1401 "reserved" ;
VAL_ 985 ACC_ObsTarget8ID 0 "not detect" 1 "1~30" 31 "invalid" ;
VAL_ 985 ACC_ObsTarget8Type 0 "no display" 1 "Cone Consideration" 2 "Warning Column" 3 "Water Horse" 4 "Anti-Collision Bucket" 5 "Emergancy Triangles" 6 "others" 7 "reserved" ;
VAL_ 985 ACC_ObsTarget8LatRange 0 "-50~50" 1001 "reserved" ;
VAL_ 985 ACC_ObsTarget8LngRange 0 "-20~120" 1401 "reserved" ;
VAL_ 985 ACC_ObsTarget7ID 0 "not detect" 1 "1~30" 31 "invalid" ;
VAL_ 985 ACC_ObsTarget7Type 0 "no display" 1 "Cone Consideration" 2 "Warning Column" 3 "Water Horse" 4 "Anti-Collision Bucket" 5 "Emergancy Triangles" 6 "others" 7 "reserved" ;
VAL_ 985 ACC_ObsTarget7LatRange 0 "-50~50" 1001 "reserved" ;
VAL_ 985 ACC_ObsTarget7LngRange 0 "-20~120" 1401 "reserved" ;
VAL_ 985 ACC_ObsTarget6ID 0 "not detect" 1 "1~30" 31 "invalid" ;
VAL_ 985 ACC_ObsTarget6Type 0 "no display" 1 "Cone Consideration" 2 "Warning Column" 3 "Water Horse" 4 "Anti-Collision Bucket" 5 "Emergancy Triangles" 6 "others" 7 "reserved" ;
VAL_ 985 ACC_ObsTarget6LatRange 0 "-50~50" 1001 "reserved" ;
VAL_ 985 ACC_ObsTarget6LngRange 0 "-20~120" 1401 "reserved" ;
VAL_ 985 ACC_ObsTarget5ID 0 "not detect" 1 "1~30" 31 "invalid" ;
VAL_ 985 ACC_ObsTarget5Type 0 "no display" 1 "Cone Consideration" 2 "Warning Column" 3 "Water Horse" 4 "Anti-Collision Bucket" 5 "Emergancy Triangles" 6 "others" 7 "reserved" ;
VAL_ 985 ACC_ObsTarget5LatRange 0 "-50~50" 1001 "reserved" ;
VAL_ 985 ACC_ObsTarget5LngRange 0 "-20~120" 1401 "reserved" ;
VAL_ 985 ACC_ObsTarget4ID 0 "not detect" 1 "1~30" 31 "invalid" ;
VAL_ 985 ACC_ObsTarget4Type 0 "no display" 1 "Cone Consideration" 2 "Warning Column" 3 "Water Horse" 4 "Anti-Collision Bucket" 5 "Emergancy Triangles" 6 "others" 7 "reserved" ;
VAL_ 985 ACC_ObsTarget4LatRange 0 "-50~50" 1001 "reserved" ;
VAL_ 985 ACC_ObsTarget4LngRange 0 "-20~120" 1401 "reserved" ;
VAL_ 985 ACC_ObsTarget3ID 0 "not detect" 1 "1~30" 31 "invalid" ;
VAL_ 985 ACC_ObsTarget3Type 0 "no display" 1 "Cone Consideration" 2 "Warning Column" 3 "Water Horse" 4 "Anti-Collision Bucket" 5 "Emergancy Triangles" 6 "others" 7 "reserved" ;
VAL_ 985 ACC_ObsTarget3LatRange 0 "-50~50" 1001 "reserved" ;
VAL_ 985 ACC_ObsTarget3LngRange 0 "-20~120" 1401 "reserved" ;
VAL_ 985 ACC_ObsTarget2ID 0 "not detect" 1 "1~30" 31 "invalid" ;
VAL_ 985 ACC_ObsTarget2Type 0 "no display" 1 "Cone Consideration" 2 "Warning Column" 3 "Water Horse" 4 "Anti-Collision Bucket" 5 "Emergancy Triangles" 6 "others" 7 "reserved" ;
VAL_ 985 ACC_ObsTarget2LatRange 0 "-50~50" 1001 "reserved" ;
VAL_ 985 ACC_ObsTarget2LngRange 0 "-20~120" 1401 "reserved" ;
VAL_ 985 ACC_ObsTarget1ID 0 "not detect" 1 "1~30" 31 "invalid" ;
VAL_ 985 ACC_ObsTarget1Type 0 "no display" 1 "Cone Consideration" 2 "Warning Column" 3 "Water Horse" 4 "Anti-Collision Bucket" 5 "Emergancy Triangles" 6 "others" 7 "reserved" ;
VAL_ 985 ACC_ObsTarget1LatRange 0 "-50~50" 1001 "reserved" ;
VAL_ 985 ACC_ObsTarget1LngRange 0 "-20~120" 1401 "reserved" ;
VAL_ 987 ACC_ObsTarget20ID 0 "not detect" 1 "1~30" 31 "invalid" ;
VAL_ 987 ACC_ObsTarget20Type 0 "no display" 1 "Cone Consideration" 2 "Warning Column" 3 "Water Horse" 4 "Anti-Collision Bucket" 5 "Emergancy Triangles" 6 "others" 7 "reserved" ;
VAL_ 987 ACC_ObsTarget20LatRange 0 "-50~50" 1001 "reserved" ;
VAL_ 987 ACC_ObsTarget20LngRange 0 "-20~120" 1401 "reserved" ;
VAL_ 987 ACC_ObsTarget19ID 0 "not detect" 1 "1~30" 31 "invalid" ;
VAL_ 987 ACC_ObsTarget19Type 0 "no display" 1 "Cone Consideration" 2 "Warning Column" 3 "Water Horse" 4 "Anti-Collision Bucket" 5 "Emergancy Triangles" 6 "others" 7 "reserved" ;
VAL_ 987 ACC_ObsTarget19LatRange 0 "-50~50" 1001 "reserved" ;
VAL_ 987 ACC_ObsTarget19LngRange 0 "-20~120" 1401 "reserved" ;
VAL_ 987 ACC_ObsTarget18ID 0 "not detect" 1 "1~30" 31 "invalid" ;
VAL_ 987 ACC_ObsTarget18Type 0 "no display" 1 "Cone Consideration" 2 "Warning Column" 3 "Water Horse" 4 "Anti-Collision Bucket" 5 "Emergancy Triangles" 6 "others" 7 "reserved" ;
VAL_ 987 ACC_ObsTarget18LatRange 0 "-50~50" 1001 "reserved" ;
VAL_ 987 ACC_ObsTarget18LngRange 0 "-20~120" 1401 "reserved" ;
VAL_ 987 ACC_ObsTarget17ID 0 "not detect" 1 "1~30" 31 "invalid" ;
VAL_ 987 ACC_ObsTarget17Type 0 "no display" 1 "Cone Consideration" 2 "Warning Column" 3 "Water Horse" 4 "Anti-Collision Bucket" 5 "Emergancy Triangles" 6 "others" 7 "reserved" ;
VAL_ 987 ACC_ObsTarget17LatRange 0 "-50~50" 1001 "reserved" ;
VAL_ 987 ACC_ObsTarget17LngRange 0 "-20~120" 1401 "reserved" ;
VAL_ 987 ACC_ObsTarget16ID 0 "not detect" 1 "1~30" 31 "invalid" ;
VAL_ 987 ACC_ObsTarget16Type 0 "no display" 1 "Cone Consideration" 2 "Warning Column" 3 "Water Horse" 4 "Anti-Collision Bucket" 5 "Emergancy Triangles" 6 "others" 7 "reserved" ;
VAL_ 987 ACC_ObsTarget16LatRange 0 "-50~50" 1001 "reserved" ;
VAL_ 987 ACC_ObsTarget16LngRange 0 "-20~120" 1401 "reserved" ;
VAL_ 987 ACC_ObsTarget15ID 0 "not detect" 1 "1~30" 31 "invalid" ;
VAL_ 987 ACC_ObsTarget15Type 0 "no display" 1 "Cone Consideration" 2 "Warning Column" 3 "Water Horse" 4 "Anti-Collision Bucket" 5 "Emergancy Triangles" 6 "others" 7 "reserved" ;
VAL_ 987 ACC_ObsTarget15LatRange 0 "-50~50" 1001 "reserved" ;
VAL_ 987 ACC_ObsTarget15LngRange 0 "-20~120" 1401 "reserved" ;
VAL_ 987 ACC_ObsTarget14ID 0 "not detect" 1 "1~30" 31 "invalid" ;
VAL_ 987 ACC_ObsTarget14Type 0 "no display" 1 "Cone Consideration" 2 "Warning Column" 3 "Water Horse" 4 "Anti-Collision Bucket" 5 "Emergancy Triangles" 6 "others" 7 "reserved" ;
VAL_ 987 ACC_ObsTarget14LatRange 0 "-50~50" 1001 "reserved" ;
VAL_ 987 ACC_ObsTarget14LngRange 0 "-20~120" 1401 "reserved" ;
VAL_ 987 ACC_ObsTarget13ID 0 "not detect" 1 "1~30" 31 "invalid" ;
VAL_ 987 ACC_ObsTarget13Type 0 "no display" 1 "Cone Consideration" 2 "Warning Column" 3 "Water Horse" 4 "Anti-Collision Bucket" 5 "Emergancy Triangles" 6 "others" 7 "reserved" ;
VAL_ 987 ACC_ObsTarget13LatRange 0 "-50~50" 1001 "reserved" ;
VAL_ 987 ACC_ObsTarget13LngRange 0 "-20~120" 1401 "reserved" ;
VAL_ 987 ACC_ObsTarget12ID 0 "not detect" 1 "1~30" 31 "invalid" ;
VAL_ 987 ACC_ObsTarget12Type 0 "no display" 1 "Cone Consideration" 2 "Warning Column" 3 "Water Horse" 4 "Anti-Collision Bucket" 5 "Emergancy Triangles" 6 "others" 7 "reserved" ;
VAL_ 987 ACC_ObsTarget12LatRange 0 "-50~50" 1001 "reserved" ;
VAL_ 987 ACC_ObsTarget12LngRange 0 "-20~120" 1401 "reserved" ;
VAL_ 987 ACC_ObsTarget11ID 0 "not detect" 1 "1~30" 31 "invalid" ;
VAL_ 987 ACC_ObsTarget11Type 0 "no display" 1 "Cone Consideration" 2 "Warning Column" 3 "Water Horse" 4 "Anti-Collision Bucket" 5 "Emergancy Triangles" 6 "others" 7 "reserved" ;
VAL_ 987 ACC_ObsTarget11LatRange 0 "-50~50" 1001 "reserved" ;
VAL_ 987 ACC_ObsTarget11LngRange 0 "-20~120" 1401 "reserved" ;
